VERSION ""

NS_ :

BS_:

BU_: CVC_I MHU TBOX FCAM_I MRR SRR_RL SRR_RR SRR_FL SRR_FR DUMMY_ECU ADCU_I AMP HUD

BO_ 854 CVC_ADAS_SOTA_REQUEST: 20 CVC_I
 SG_ CRC_CVC_ADAS_SOTA_REQUEST : 7|8@0+ (1,0) [0|255] ""  MHU,FCAM_I,SRR_RL,SRR_RR,SRR_FL,SRR_FR,ADCU_I
 SG_ ALIVE_CVC_ADAS_SOTA_REQUEST : 11|4@0+ (1,0) [0|15] ""  MHU,FCAM_I,SRR_RL,SRR_RR,SRR_FL,SRR_FR,ADCU_I
 SG_ CVC_ADAS_HWA_SOTA : 114|3@0+ (1,0) [0|7] ""  MHU,FCAM_I,SRR_RL,SRR_RR,SRR_FL,SRR_FR,ADCU_I
 SG_ CVC_ADAS_AESA_SOTA : 20|3@0+ (1,0) [0|7] ""  MHU,FCAM_I,SRR_RL,SRR_RR,SRR_FL,SRR_FR,ADCU_I
 SG_ CVC_ADAS_ALCA_SOTA : 23|3@0+ (1,0) [0|7] ""  MHU,FCAM_I,SRR_RL,SRR_RR,SRR_FL,SRR_FR,ADCU_I
 SG_ CVC_ADAS_BasicCruise_SOTA : 17|3@0+ (1,0) [0|7] ""  MHU,FCAM_I,SRR_RL,SRR_RR,SRR_FL,SRR_FR,ADCU_I
 SG_ CVC_ADAS_ACC_SOTA : 30|3@0+ (1,0) [0|7] ""  MHU,FCAM_I,SRR_RL,SRR_RR,SRR_FL,SRR_FR,ADCU_I
 SG_ CVC_ADAS_TSR_SOTA : 27|3@0+ (1,0) [0|7] ""  MHU,FCAM_I,SRR_RL,SRR_RR,SRR_FL,SRR_FR,ADCU_I
 SG_ CVC_ADAS_ISA_SOTA : 24|3@0+ (1,0) [0|7] ""  MHU,FCAM_I,SRR_RL,SRR_RR,SRR_FL,SRR_FR,ADCU_I
 SG_ CVC_ADAS_NOP_SOTA : 37|3@0+ (1,0) [0|7] ""  MHU,FCAM_I,SRR_RL,SRR_RR,SRR_FL,SRR_FR,ADCU_I
 SG_ CVC_ADAS_AAESA_SOTA : 34|3@0+ (1,0) [0|7] ""  MHU,FCAM_I,SRR_RL,SRR_RR,SRR_FL,SRR_FR,ADCU_I
 SG_ CVC_ADAS_ALCM_SOTA : 47|3@0+ (1,0) [0|7] ""  MHU,FCAM_I,SRR_RL,SRR_RR,SRR_FL,SRR_FR,ADCU_I
 SG_ CVC_ADAS_AACC_SOTA : 41|3@0+ (1,0) [0|7] ""  MHU,FCAM_I,SRR_RL,SRR_RR,SRR_FL,SRR_FR,ADCU_I
 SG_ CVC_ADAS_TLD_SOTA : 54|3@0+ (1,0) [0|7] ""  MHU,FCAM_I,SRR_RL,SRR_RR,SRR_FL,SRR_FR,ADCU_I
 SG_ CVC_ADAS_DNS_SOTA : 51|3@0+ (1,0) [0|7] ""  MHU,FCAM_I,SRR_RL,SRR_RR,SRR_FL,SRR_FR,ADCU_I
 SG_ CVC_ADAS_LDW_SOTA : 48|3@0+ (1,0) [0|7] ""  MHU,FCAM_I,SRR_RL,SRR_RR,SRR_FL,SRR_FR,ADCU_I
 SG_ CVC_ADAS_LKA_SOTA : 61|3@0+ (1,0) [0|7] ""  MHU,FCAM_I,SRR_RL,SRR_RR,SRR_FL,SRR_FR,ADCU_I
 SG_ CVC_ADAS_ELK_SOTA : 58|3@0+ (1,0) [0|7] ""  MHU,FCAM_I,SRR_RL,SRR_RR,SRR_FL,SRR_FR,ADCU_I
 SG_ CVC_ADAS_FAEB_SOTA : 71|3@0+ (1,0) [0|7] ""  MHU,FCAM_I,SRR_RL,SRR_RR,SRR_FL,SRR_FR,ADCU_I
 SG_ CVC_ADAS_ESA_SOTA : 68|3@0+ (1,0) [0|7] ""  MHU,FCAM_I,SRR_RL,SRR_RR,SRR_FL,SRR_FR,ADCU_I
 SG_ CVC_ADAS_RAEB_SOTA : 65|3@0+ (1,0) [0|7] ""  MHU,FCAM_I,SRR_RL,SRR_RR,SRR_FL,SRR_FR,ADCU_I
 SG_ CVC_ADAS_FCW_SOTA : 78|3@0+ (1,0) [0|7] ""  MHU,FCAM_I,SRR_RL,SRR_RR,SRR_FL,SRR_FR,ADCU_I
 SG_ CVC_ADAS_RCTA_SOTA : 75|3@0+ (1,0) [0|7] ""  MHU,FCAM_I,SRR_RL,SRR_RR,SRR_FL,SRR_FR,ADCU_I
 SG_ CVC_ADAS_BSD_SOTA : 72|3@0+ (1,0) [0|7] ""  MHU,FCAM_I,SRR_RL,SRR_RR,SRR_FL,SRR_FR,ADCU_I
 SG_ CVC_ADAS_DOW_SOTA : 85|3@0+ (1,0) [0|7] ""  MHU,FCAM_I,SRR_RL,SRR_RR,SRR_FL,SRR_FR,ADCU_I
 SG_ CVC_ADAS_IA_SOTA : 82|3@0+ (1,0) [0|7] ""  MHU,FCAM_I,SRR_RL,SRR_RR,SRR_FL,SRR_FR,ADCU_I
 SG_ CVC_ADAS_SVM_SOTA : 95|3@0+ (1,0) [0|7] ""  MHU,FCAM_I,SRR_RL,SRR_RR,SRR_FL,SRR_FR,ADCU_I
 SG_ CVC_ADAS_RVC_SOTA : 89|3@0+ (1,0) [0|7] ""  MHU,FCAM_I,SRR_RL,SRR_RR,SRR_FL,SRR_FR,ADCU_I
 SG_ CVC_ADAS_FPA_SOTA : 92|3@0+ (1,0) [0|7] ""  MHU,FCAM_I,SRR_RL,SRR_RR,SRR_FL,SRR_FR,ADCU_I
 SG_ CVC_ADAS_RPA_SOTA : 102|3@0+ (1,0) [0|7] ""  MHU,FCAM_I,SRR_RL,SRR_RR,SRR_FL,SRR_FR,ADCU_I
 SG_ CVC_ADAS_SpaFAPA_SOTA : 99|3@0+ (1,0) [0|7] ""  MHU,FCAM_I,SRR_RL,SRR_RR,SRR_FL,SRR_FR,ADCU_I
 SG_ CVC_ADAS_RP_SOTA : 44|3@0+ (1,0) [0|7] ""  MHU,FCAM_I,SRR_RL,SRR_RR,SRR_FL,SRR_FR,ADCU_I
 SG_ CVC_ADAS_VParkingSelect_SOTA : 110|3@0+ (1,0) [0|7] ""  MHU,FCAM_I,SRR_RL,SRR_RR,SRR_FL,SRR_FR,ADCU_I
 SG_ CVC_ADAS_VParkingComfort_SOTA : 107|3@0+ (1,0) [0|7] ""  MHU,FCAM_I,SRR_RL,SRR_RR,SRR_FL,SRR_FR,ADCU_I
 SG_ CVC_ADAS_VParkingSummon_SOTA : 104|3@0+ (1,0) [0|7] ""  MHU,FCAM_I,SRR_RL,SRR_RR,SRR_FL,SRR_FR,ADCU_I
 SG_ CVC_ADAS_VParkingAutoRev_SOTA : 117|3@0+ (1,0) [0|7] ""  MHU,FCAM_I,SRR_RL,SRR_RR,SRR_FL,SRR_FR,ADCU_I
 SG_ CVC_ADAS_AHB_SOTA : 127|3@0+ (1,0) [0|7] ""  MHU,FCAM_I,SRR_RL,SRR_RR,SRR_FL,SRR_FR,ADCU_I
 SG_ CVC_ADAS_ADB_SOTA : 124|3@0+ (1,0) [0|7] ""  MHU,FCAM_I,SRR_RL,SRR_RR,SRR_FL,SRR_FR,ADCU_I
 SG_ CVC_ADAS_DMS_SOTA : 121|3@0+ (1,0) [0|7] ""  MHU,FCAM_I,SRR_RL,SRR_RR,SRR_FL,SRR_FR,ADCU_I
 SG_ CVC_ADAS_DMSFaceID_SOTA : 134|3@0+ (1,0) [0|7] ""  MHU,FCAM_I,SRR_RL,SRR_RR,SRR_FL,SRR_FR,ADCU_I
 SG_ CVC_ADAS_DCM_SOTA : 131|3@0+ (1,0) [0|7] ""  MHU,FCAM_I,SRR_RL,SRR_RR,SRR_FL,SRR_FR,ADCU_I
 SG_ CVC_ADAS_AdasEDR_SOTA : 128|3@0+ (1,0) [0|7] ""  MHU,FCAM_I,SRR_RL,SRR_RR,SRR_FL,SRR_FR,ADCU_I
 SG_ CVC_ADAS_ACPE_SOTA : 141|3@0+ (1,0) [0|7] ""  MHU,FCAM_I,SRR_RL,SRR_RR,SRR_FL,SRR_FR,ADCU_I
 SG_ CVC_ADAS_SentryMode_SOTA : 138|3@0+ (1,0) [0|7] ""  MHU,FCAM_I,SRR_RL,SRR_RR,SRR_FL,SRR_FR,ADCU_I

BO_ 862 CVC_Vehicle_info: 16 CVC_I
 SG_ CRC_CVC_Vehicle_info : 7|8@0+ (1,0) [0|255] ""  MHU,ADCU_I
 SG_ ALIVE_CVC_Vehicle_info : 11|4@0+ (1,0) [0|15] ""  MHU,ADCU_I
 SG_ CVC_VehLock_STS : 13|2@0+ (1,0) [0|3] ""  ADCU_I,HUD
 SG_ CVC_VehSpd_ScreenDisplay : 23|8@0+ (1,0) [0|254] ""  ADCU_I,HUD
 SG_ CVC_VehChgAllow : 25|2@0+ (1,0) [0|3] ""  ADCU_I,HUD
 SG_ CVC_VehDischgAllow : 15|2@0+ (1,0) [0|3] ""  ADCU_I,HUD
 SG_ Re_InitCharging_Req : 27|2@0+ (1,0) [0|3] ""  ADCU_I,HUD
 SG_ CVC_StopChg_Req : 28|1@0+ (1,0) [0|1] ""  ADCU_I,HUD
 SG_ CVC_GunUnlock_Req : 30|2@0+ (1,0) [0|3] ""  ADCU_I,HUD
 SG_ CVC_Ack_LimitSetting_SOC : 39|7@0+ (1,0) [0|100] "%"  ADCU_I,HUD
 SG_ CVC_ACInputChgCurLim : 47|6@0+ (1,0) [0|48] "A"  ADCU_I,HUD
 SG_ CVC_HV_DispSOC : 41|10@0+ (0.1,0) [0|100] "%"  MHU,ADCU_I
 SG_ CVC_HV_Cur_LoadComp : 63|10@0+ (0.1,0) [0|100] "A"  ADCU_I,HUD
 SG_ CVC_AntiTheft_Status : 69|3@0+ (1,0) [0|7] ""  MHU,FCAM_I,SRR_RR,ADCU_I

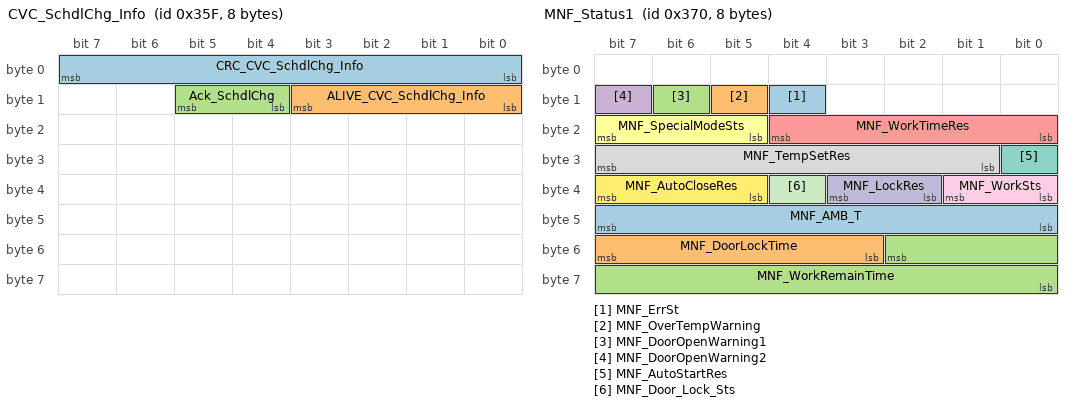
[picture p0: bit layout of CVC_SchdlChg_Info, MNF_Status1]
BO_ 863 CVC_SchdlChg_Info: 8 CVC_I
 SG_ CRC_CVC_SchdlChg_Info : 7|8@0+ (1,0) [0|255] ""  MHU
 SG_ ALIVE_CVC_SchdlChg_Info : 11|4@0+ (1,0) [0|15] ""  MHU
 SG_ Ack_SchdlChg : 13|2@0+ (1,0) [0|3] ""  MHU

BO_ 866 WCBS_RecuBrkTrqReq: 24 CVC_I
 SG_ CRC_WCBS_RecuBrkTrqReq : 7|8@0+ (1,0) [0|255] ""  SRR_RR,SRR_FR
 SG_ ALIVE_WCBS_RecuBrkTrqReq : 11|4@0+ (1,0) [0|15] ""  SRR_RR,SRR_FR
 SG_ WCBS_RBC_STS : 12|1@0+ (1,0) [0|1] ""  SRR_RR,SRR_FR
 SG_ WCBS_RegenMonFail : 13|1@0+ (1,0) [0|1] ""  SRR_RR,SRR_FR
 SG_ WCBS_TorqReqMode : 15|2@0+ (1,0) [0|3] ""  SRR_RR,SRR_FR
 SG_ WCBS_F_RegenTarTrq : 23|16@0+ (1,-4000) [-4000|0] "Nm"  SRR_RR,SRR_FR
 SG_ WCBS_R_RegenTarTrq : 39|16@0+ (1,-4000) [-4000|0] "Nm"  SRR_RR,SRR_FR
 SG_ WCBS_F_RegenTarTrqValid : 48|1@0+ (1,0) [0|1] ""  SRR_RR,SRR_FR
 SG_ WCBS_R_RegenTarTrqValid : 49|1@0+ (1,0) [0|1] ""  SRR_RR,SRR_FR
 SG_ WCBS_F_FrictionTarTrq : 63|16@0+ (1,-4000) [-4000|0] "Nm"  SRR_RR,SRR_FR
 SG_ WCBS_R_FrictionTarTrq : 79|16@0+ (1,-4000) [-4000|0] "Nm"  SRR_RR,SRR_FR
 SG_ Secure_ResetCnt_0x362 : 135|16@0+ (1,0) [0|65535] ""  SRR_RR,SRR_FR
 SG_ Secure_MsgCnt_0x362 : 151|16@0+ (1,0) [0|65535] ""  SRR_RR,SRR_FR
 SG_ Secure_MAC_0x362 : 167|32@0+ (1,0) [0|4294967295] ""  SRR_RR,SRR_FR

BO_ 872 FMCU_Fault: 8 CVC_I
 SG_ FMCU_PhaseOverCurrentSWFault : 0|1@0+ (1,0) [0|1] ""  MHU
 SG_ FMCU_MCUOverTempFault : 1|1@0+ (1,0) [0|1] ""  MHU
 SG_ FMCU_MCUOverTempAlarm : 2|1@0+ (1,0) [0|1] ""  MHU
 SG_ FMCU_MotOverTemp2Fault : 5|1@0+ (1,0) [0|1] ""  MHU
 SG_ FMCU_MotTempSenFault : 6|1@0+ (1,0) [0|1] ""  MHU
 SG_ FMCU_MotOverTemp1Fault : 7|1@0+ (1,0) [0|1] ""  MHU
 SG_ FMCU_MotOverTempAlarm : 8|1@0+ (1,0) [0|1] ""  MHU
 SG_ FMCU_MCUHVUnderVoltageFault : 9|1@0+ (1,0) [0|1] ""  MHU
 SG_ FMCU_MCUHVUnderVoltageAlarm : 10|1@0+ (1,0) [0|1] ""  MHU
 SG_ FMCU_MCUHVOverVoltageFault : 11|1@0+ (1,0) [0|1] ""  MHU
 SG_ FMCU_MCUHVOverVoltageAlarm : 12|1@0+ (1,0) [0|1] ""  MHU
 SG_ FMCU_MCUCurrentSenWFault : 13|1@0+ (1,0) [0|1] ""  MHU
 SG_ FMCU_MCUCurrentSenVFault : 14|1@0+ (1,0) [0|1] ""  MHU
 SG_ FMCU_MCUCurrentSenUFault : 15|1@0+ (1,0) [0|1] ""  MHU
 SG_ FMCU_PhaseOverCurrentHWFault : 16|1@0+ (1,0) [0|1] ""  MHU
 SG_ FMCU_MotOverFault : 17|1@0+ (1,0) [0|1] ""  MHU
 SG_ FMCU_MotOverAlarm : 18|1@0+ (1,0) [0|1] ""  MHU
 SG_ FMCU_12VUnderVoltageAlarm : 20|1@0+ (1,0) [0|1] ""  MHU
 SG_ FMCU_12VOverVoltageAlarm : 21|1@0+ (1,0) [0|1] ""  MHU
 SG_ FMCU_MCUHVSensorFault : 22|1@0+ (1,0) [0|1] ""  MHU
 SG_ FMCU_MCUDisChgFault : 24|1@0+ (1,0) [0|1] ""  MHU
 SG_ FMCU_MotBlockedFault : 30|1@0+ (1,0) [0|1] ""  MHU
 SG_ FMCU_MotRotSenFault : 31|1@0+ (1,0) [0|1] ""  MHU
 SG_ FMCU_BMSLostFault : 34|1@0+ (1,0) [0|1] ""  MHU
 SG_ FMCU_CVCLostFault : 35|1@0+ (1,0) [0|1] ""  MHU
 SG_ FMCU_CANBusoffFault : 36|1@0+ (1,0) [0|1] ""  MHU
 SG_ FMCU_IGBTFault : 37|1@0+ (1,0) [0|1] ""  MHU
 SG_ FMCU_MCUCurrentSenWZeroFault : 38|1@0+ (1,0) [0|1] ""  MHU
 SG_ FMCU_MCUCurrentSenVZeroFault : 43|1@0+ (1,0) [0|1] ""  MHU
 SG_ FMCU_MCUCurrentSenUZeroFault : 44|1@0+ (1,0) [0|1] ""  MHU
 SG_ FMCU_MCUTempSenWFault : 45|1@0+ (1,0) [0|1] ""  MHU
 SG_ FMCU_MCUTempSenVFault : 46|1@0+ (1,0) [0|1] ""  MHU
 SG_ FMCU_MCUTempSenUFault : 47|1@0+ (1,0) [0|1] ""  MHU
 SG_ FMCU_InitMode : 50|1@0+ (1,0) [0|1] ""  MHU
 SG_ FMCU_MCUFaultCode : 63|8@0+ (1,0) [0|255] ""  MHU

BO_ 874 RMCU_Fault: 8 CVC_I
 SG_ RMCU_PhaseOverCurrentSWFault : 0|1@0+ (1,0) [0|1] ""  MHU
 SG_ RMCU_MCUOverTempFault : 1|1@0+ (1,0) [0|1] ""  MHU
 SG_ RMCU_MCUOverTempAlarm : 2|1@0+ (1,0) [0|1] ""  MHU
 SG_ RMCU_MotOverTemp2Fault : 5|1@0+ (1,0) [0|1] ""  MHU
 SG_ RMCU_MotTempSenFault : 6|1@0+ (1,0) [0|1] ""  MHU
 SG_ RMCU_MotOverTemp1Fault : 7|1@0+ (1,0) [0|1] ""  MHU
 SG_ RMCU_MotOverTempAlarm : 8|1@0+ (1,0) [0|1] ""  MHU
 SG_ RMCU_MCUHVUnderVoltageFault : 9|1@0+ (1,0) [0|1] ""  MHU
 SG_ RMCU_MCUHVUnderVoltageAlarm : 10|1@0+ (1,0) [0|1] ""  MHU
 SG_ RMCU_MCUHVOverVoltageFault : 11|1@0+ (1,0) [0|1] ""  MHU
 SG_ RMCU_MCUHVOverVoltageAlarm : 12|1@0+ (1,0) [0|1] ""  MHU
 SG_ RMCU_MCUCurrentSenWFault : 13|1@0+ (1,0) [0|1] ""  MHU
 SG_ RMCU_MCUCurrentSenVFault : 14|1@0+ (1,0) [0|1] ""  MHU
 SG_ RMCU_MCUCurrentSenUFault : 15|1@0+ (1,0) [0|1] ""  MHU
 SG_ RMCU_PhaseOverCurrentHWFault : 16|1@0+ (1,0) [0|1] ""  MHU
 SG_ RMCU_MotOverFault : 17|1@0+ (1,0) [0|1] ""  MHU
 SG_ RMCU_MotOverAlarm : 18|1@0+ (1,0) [0|1] ""  MHU
 SG_ RMCU_12VUnderVoltageAlarm : 20|1@0+ (1,0) [0|1] ""  MHU
 SG_ RMCU_12VOverVoltageAlarm : 21|1@0+ (1,0) [0|1] ""  MHU
 SG_ RMCU_MCUHVSensorFault : 22|1@0+ (1,0) [0|1] ""  MHU
 SG_ RMCU_MCUDisChgFault : 24|1@0+ (1,0) [0|1] ""  MHU
 SG_ RMCU_MotBlockedFault : 30|1@0+ (1,0) [0|1] ""  MHU
 SG_ RMCU_MotRotSenFault : 31|1@0+ (1,0) [0|1] ""  MHU
 SG_ RMCU_BMSLostFault : 34|1@0+ (1,0) [0|1] ""  MHU
 SG_ RMCU_CVCLostFault : 35|1@0+ (1,0) [0|1] ""  MHU
 SG_ RMCU_CANBusoffFault : 36|1@0+ (1,0) [0|1] ""  MHU
 SG_ RMCU_IGBTFault : 37|1@0+ (1,0) [0|1] ""  MHU
 SG_ RMCU_MCUCurrentSenWZeroFault : 38|1@0+ (1,0) [0|1] ""  MHU
 SG_ RMCU_MCUCurrentSenVZeroFault : 43|1@0+ (1,0) [0|1] ""  MHU
 SG_ RMCU_MCUCurrentSenUZeroFault : 44|1@0+ (1,0) [0|1] ""  MHU
 SG_ RMCU_MCUTempSenWFault : 45|1@0+ (1,0) [0|1] ""  MHU
 SG_ RMCU_MCUTempSenVFault : 46|1@0+ (1,0) [0|1] ""  MHU
 SG_ RMCU_MCUTempSenUFault : 47|1@0+ (1,0) [0|1] ""  MHU
 SG_ RMCU_InitMode : 50|1@0+ (1,0) [0|1] ""  MHU
 SG_ RMCU_MCUFaultCode : 63|8@0+ (1,0) [0|255] ""  MHU

BO_ 880 MNF_Status1: 8 CVC_I
 SG_ MNF_ErrSt : 12|1@0+ (1,0) [0|1] ""  MHU
 SG_ MNF_OverTempWarning : 13|1@0+ (1,0) [0|1] ""  MHU
 SG_ MNF_DoorOpenWarning1 : 14|1@0+ (1,0) [0|1] ""  MHU
 SG_ MNF_DoorOpenWarning2 : 15|1@0+ (1,0) [0|1] ""  MHU
 SG_ MNF_WorkTimeRes : 20|5@0+ (1,0) [0|24] "h"  MHU
 SG_ MNF_SpecialModeSts : 23|3@0+ (1,0) [0|7] ""  MHU
 SG_ MNF_AutoStartRes : 24|1@0+ (1,0) [0|1] ""  MHU
 SG_ MNF_TempSetRes : 31|7@0+ (1,-10) [-10|116] ""  MHU
 SG_ MNF_WorkSts : 33|2@0+ (1,0) [0|3] ""  MHU
 SG_ MNF_LockRes : 35|2@0+ (1,0) [0|3] ""  MHU
 SG_ MNF_Door_Lock_Sts : 36|1@0+ (1,0) [0|1] ""  MHU
 SG_ MNF_AutoCloseRes : 39|3@0+ (1,0) [0|6] ""  MHU
 SG_ MNF_AMB_T : 47|8@0+ (1,-50) [-50|204] "Degree C"  MHU
 SG_ MNF_DoorLockTime : 55|5@0+ (1,0) [0|30] "s"  MHU
 SG_ MNF_WorkRemainTime : 50|11@0+ (1,0) [0|2046] "min"  MHU

BO_ 881 MNF_Status2: 8 CVC_I
 SG_ MNF_INT_T : 23|8@0+ (1,-50) [-50|204] "Degree C"  MHU
 SG_ MNF_ErrInfo : 27|4@0+ (1,0) [0|12] ""  MHU
 SG_ MNF_HVReq : 28|1@0+ (1,0) [0|1] ""  MHU

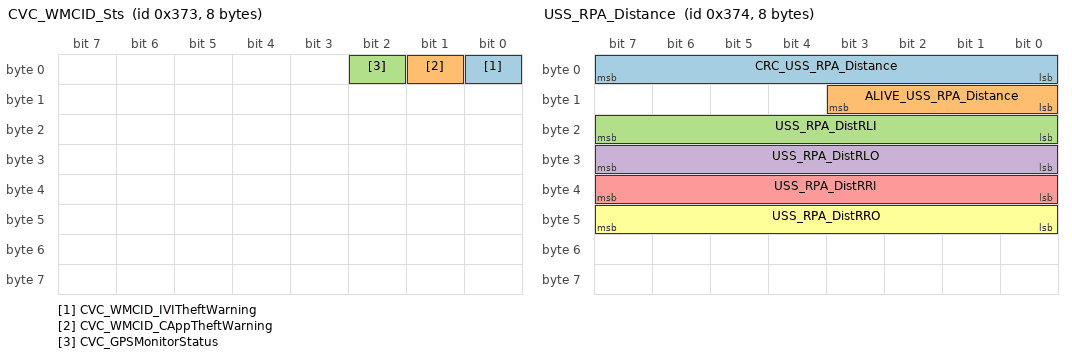
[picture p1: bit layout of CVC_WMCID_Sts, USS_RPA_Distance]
BO_ 883 CVC_WMCID_Sts: 8 CVC_I
 SG_ CVC_WMCID_IVITheftWarning : 0|1@0+ (1,0) [0|1] ""  MHU
 SG_ CVC_WMCID_CAppTheftWarning : 1|1@0+ (1,0) [0|1] ""  MHU
 SG_ CVC_GPSMonitorStatus : 2|1@0+ (1,0) [0|1] ""  MHU

BO_ 884 USS_RPA_Distance: 8 CVC_I
 SG_ CRC_USS_RPA_Distance : 7|8@0+ (1,0) [0|255] ""  MHU
 SG_ ALIVE_USS_RPA_Distance : 11|4@0+ (1,0) [0|15] ""  MHU
 SG_ USS_RPA_DistRLI : 23|8@0+ (1,0) [0|255] "cm"  MHU
 SG_ USS_RPA_DistRLO : 31|8@0+ (1,0) [0|255] "cm"  MHU
 SG_ USS_RPA_DistRRI : 39|8@0+ (1,0) [0|255] "cm"  MHU
 SG_ USS_RPA_DistRRO : 47|8@0+ (1,0) [0|255] "cm"  MHU

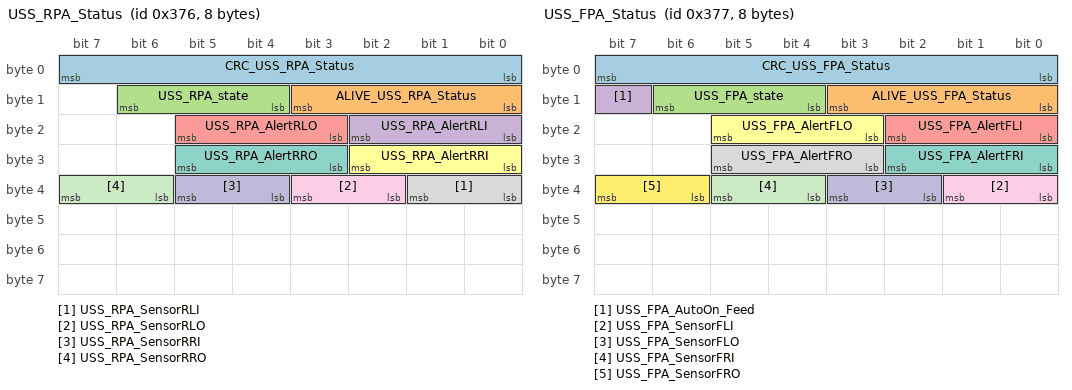
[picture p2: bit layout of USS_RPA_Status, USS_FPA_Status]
BO_ 886 USS_RPA_Status: 8 CVC_I
 SG_ CRC_USS_RPA_Status : 7|8@0+ (1,0) [0|255] ""  MHU
 SG_ ALIVE_USS_RPA_Status : 11|4@0+ (1,0) [0|15] ""  MHU
 SG_ USS_RPA_state : 14|3@0+ (1,0) [0|7] ""  MHU
 SG_ USS_RPA_AlertRLI : 18|3@0+ (1,0) [0|7] ""  MHU
 SG_ USS_RPA_AlertRLO : 21|3@0+ (1,0) [0|7] ""  MHU
 SG_ USS_RPA_AlertRRI : 26|3@0+ (1,0) [0|7] ""  MHU
 SG_ USS_RPA_AlertRRO : 29|3@0+ (1,0) [0|7] ""  MHU
 SG_ USS_RPA_SensorRLI : 33|2@0+ (1,0) [0|3] ""  MHU
 SG_ USS_RPA_SensorRLO : 35|2@0+ (1,0) [0|3] ""  MHU
 SG_ USS_RPA_SensorRRI : 37|2@0+ (1,0) [0|3] ""  MHU
 SG_ USS_RPA_SensorRRO : 39|2@0+ (1,0) [0|3] ""  MHU

BO_ 887 USS_FPA_Status: 8 CVC_I
 SG_ CRC_USS_FPA_Status : 7|8@0+ (1,0) [0|255] ""  MHU
 SG_ ALIVE_USS_FPA_Status : 11|4@0+ (1,0) [0|15] ""  MHU
 SG_ USS_FPA_state : 14|3@0+ (1,0) [0|7] ""  MHU
 SG_ USS_FPA_AutoOn_Feed : 15|1@0+ (1,0) [0|1] ""  MHU
 SG_ USS_FPA_AlertFLI : 18|3@0+ (1,0) [0|7] ""  MHU
 SG_ USS_FPA_AlertFLO : 21|3@0+ (1,0) [0|7] ""  MHU
 SG_ USS_FPA_AlertFRI : 26|3@0+ (1,0) [0|7] ""  MHU
 SG_ USS_FPA_AlertFRO : 29|3@0+ (1,0) [0|7] ""  MHU
 SG_ USS_FPA_SensorFLI : 33|2@0+ (1,0) [0|3] ""  MHU
 SG_ USS_FPA_SensorFLO : 35|2@0+ (1,0) [0|3] ""  MHU
 SG_ USS_FPA_SensorFRI : 37|2@0+ (1,0) [0|3] ""  MHU
 SG_ USS_FPA_SensorFRO : 39|2@0+ (1,0) [0|3] ""  MHU

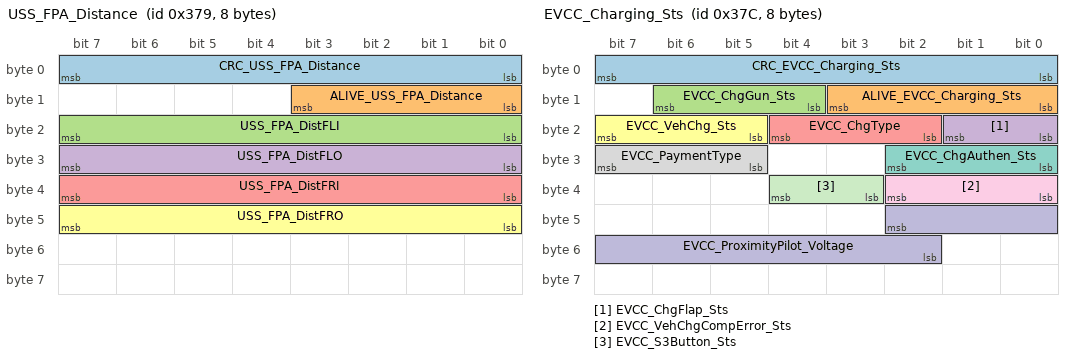
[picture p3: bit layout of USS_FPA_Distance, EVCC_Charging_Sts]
BO_ 889 USS_FPA_Distance: 8 CVC_I
 SG_ CRC_USS_FPA_Distance : 7|8@0+ (1,0) [0|255] ""  MHU
 SG_ ALIVE_USS_FPA_Distance : 11|4@0+ (1,0) [0|15] ""  MHU
 SG_ USS_FPA_DistFLI : 23|8@0+ (1,0) [0|255] "cm"  MHU
 SG_ USS_FPA_DistFLO : 31|8@0+ (1,0) [0|255] "cm"  MHU
 SG_ USS_FPA_DistFRI : 39|8@0+ (1,0) [0|255] "cm"  MHU
 SG_ USS_FPA_DistFRO : 47|8@0+ (1,0) [0|255] "cm"  MHU

BO_ 892 EVCC_Charging_Sts: 8 CVC_I
 SG_ CRC_EVCC_Charging_Sts : 7|8@0+ (1,0) [0|255] ""  MHU,ADCU_I
 SG_ ALIVE_EVCC_Charging_Sts : 11|4@0+ (1,0) [0|15] ""  MHU,ADCU_I
 SG_ EVCC_ChgGun_Sts : 14|3@0+ (1,0) [0|7] ""  MHU,ADCU_I
 SG_ EVCC_ChgFlap_Sts : 17|2@0+ (1,0) [0|3] ""  MHU,ADCU_I
 SG_ EVCC_ChgType : 20|3@0+ (1,0) [0|7] ""  MHU,ADCU_I
 SG_ EVCC_VehChg_Sts : 23|3@0+ (1,0) [0|7] ""  MHU,ADCU_I
 SG_ EVCC_ChgAuthen_Sts : 26|3@0+ (1,0) [0|7] ""  MHU,ADCU_I
 SG_ EVCC_PaymentType : 31|3@0+ (1,0) [0|7] ""  MHU,ADCU_I
 SG_ EVCC_VehChgCompError_Sts : 34|3@0+ (1,0) [0|7] ""  MHU,ADCU_I
 SG_ EVCC_ProximityPilot_Voltage : 42|9@0+ (0.01,0) [0|5] "V"  MHU,ADCU_I
 SG_ EVCC_S3Button_Sts : 36|2@0+ (1,0) [0|3] ""  MHU,ADCU_I

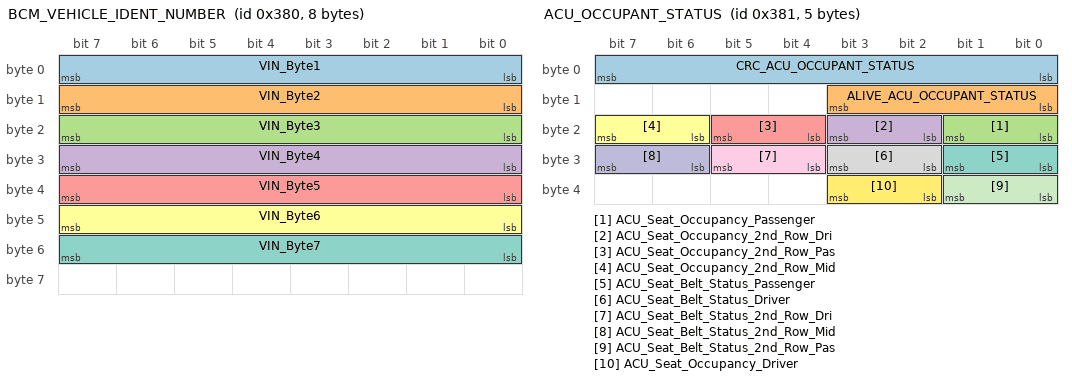
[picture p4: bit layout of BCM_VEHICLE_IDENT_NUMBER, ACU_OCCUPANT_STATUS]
BO_ 896 BCM_VEHICLE_IDENT_NUMBER: 8 CVC_I
 SG_ VIN_Byte1 : 7|8@0+ (1,0) [0|255] ""  MHU,FCAM_I,SRR_RR,ADCU_I
 SG_ VIN_Byte2 : 15|8@0+ (1,0) [0|255] ""  MHU,FCAM_I,SRR_RR,ADCU_I
 SG_ VIN_Byte3 : 23|8@0+ (1,0) [0|255] ""  MHU,FCAM_I,SRR_RR,ADCU_I
 SG_ VIN_Byte4 : 31|8@0+ (1,0) [0|255] ""  MHU,FCAM_I,SRR_RR,ADCU_I
 SG_ VIN_Byte5 : 39|8@0+ (1,0) [0|255] ""  MHU,FCAM_I,SRR_RR,ADCU_I
 SG_ VIN_Byte6 : 47|8@0+ (1,0) [0|255] ""  MHU,FCAM_I,SRR_RR,ADCU_I
 SG_ VIN_Byte7 : 55|8@0+ (1,0) [0|255] ""  MHU,FCAM_I,SRR_RR,ADCU_I

BO_ 897 ACU_OCCUPANT_STATUS: 5 CVC_I
 SG_ CRC_ACU_OCCUPANT_STATUS : 7|8@0+ (1,0) [0|255] ""  MHU,TBOX,FCAM_I,MRR,SRR_RL,SRR_RR,SRR_FL,SRR_FR,ADCU_I,AMP
 SG_ ALIVE_ACU_OCCUPANT_STATUS : 11|4@0+ (1,0) [0|15] ""  MHU,TBOX,FCAM_I,MRR,SRR_RL,SRR_RR,SRR_FL,SRR_FR,ADCU_I,AMP
 SG_ ACU_Seat_Occupancy_Passenger : 17|2@0+ (1,0) [0|3] ""  MHU,TBOX,FCAM_I,MRR,SRR_RL,SRR_RR,SRR_FL,SRR_FR,ADCU_I,AMP
 SG_ ACU_Seat_Occupancy_2nd_Row_Dri : 19|2@0+ (1,0) [0|3] ""  MHU,TBOX,FCAM_I,MRR,SRR_RL,SRR_RR,SRR_FL,SRR_FR,ADCU_I,AMP
 SG_ ACU_Seat_Occupancy_2nd_Row_Pas : 21|2@0+ (1,0) [0|3] ""  MHU,TBOX,FCAM_I,MRR,SRR_RL,SRR_RR,SRR_FL,SRR_FR,ADCU_I,AMP
 SG_ ACU_Seat_Occupancy_2nd_Row_Mid : 23|2@0+ (1,0) [0|3] ""  MHU,TBOX,FCAM_I,MRR,SRR_RL,SRR_RR,SRR_FL,SRR_FR,ADCU_I,AMP
 SG_ ACU_Seat_Belt_Status_Passenger : 25|2@0+ (1,0) [0|3] ""  MHU,TBOX,FCAM_I,MRR,SRR_RL,SRR_RR,SRR_FL,SRR_FR,ADCU_I,AMP
 SG_ ACU_Seat_Belt_Status_Driver : 27|2@0+ (1,0) [0|3] ""  MHU,TBOX,FCAM_I,MRR,SRR_RL,SRR_RR,SRR_FL,SRR_FR,ADCU_I,AMP
 SG_ ACU_Seat_Belt_Status_2nd_Row_Dri : 29|2@0+ (1,0) [0|3] ""  MHU,TBOX,FCAM_I,MRR,SRR_RL,SRR_RR,SRR_FL,SRR_FR,ADCU_I,AMP
 SG_ ACU_Seat_Belt_Status_2nd_Row_Mid : 31|2@0+ (1,0) [0|3] ""  MHU,TBOX,FCAM_I,MRR,SRR_RL,SRR_RR,SRR_FL,SRR_FR,ADCU_I,AMP
 SG_ ACU_Seat_Belt_Status_2nd_Row_Pas : 33|2@0+ (1,0) [0|3] ""  MHU,TBOX,FCAM_I,MRR,SRR_RL,SRR_RR,SRR_FL,SRR_FR,ADCU_I,AMP
 SG_ ACU_Seat_Occupancy_Driver : 35|2@0+ (1,0) [0|3] ""  MHU,TBOX,FCAM_I,MRR,SRR_RL,SRR_RR,SRR_FL,SRR_FR,ADCU_I,AMP

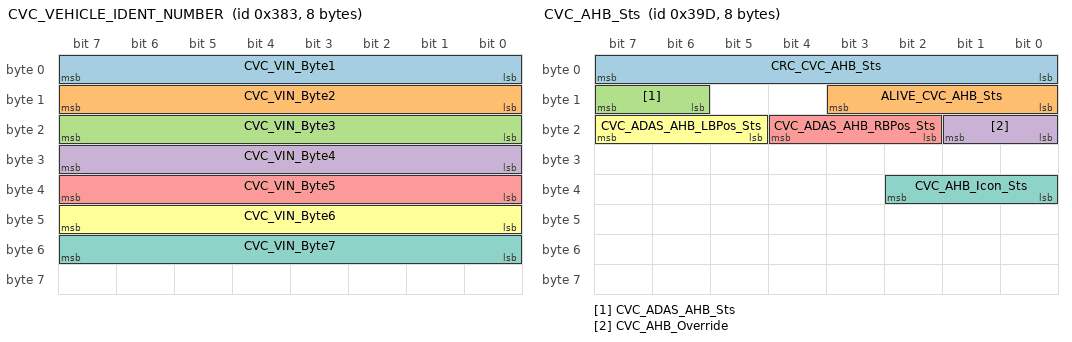
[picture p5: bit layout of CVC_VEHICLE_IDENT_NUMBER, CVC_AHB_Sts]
BO_ 899 CVC_VEHICLE_IDENT_NUMBER: 8 CVC_I
 SG_ CVC_VIN_Byte1 : 7|8@0+ (1,0) [0|255] ""  MHU
 SG_ CVC_VIN_Byte2 : 15|8@0+ (1,0) [0|255] ""  MHU
 SG_ CVC_VIN_Byte3 : 23|8@0+ (1,0) [0|255] ""  MHU
 SG_ CVC_VIN_Byte4 : 31|8@0+ (1,0) [0|255] ""  MHU
 SG_ CVC_VIN_Byte5 : 39|8@0+ (1,0) [0|255] ""  MHU
 SG_ CVC_VIN_Byte6 : 47|8@0+ (1,0) [0|255] ""  MHU
 SG_ CVC_VIN_Byte7 : 55|8@0+ (1,0) [0|255] ""  MHU

BO_ 925 CVC_AHB_Sts: 8 CVC_I
 SG_ CRC_CVC_AHB_Sts : 7|8@0+ (1,0) [0|255] ""  MHU,FCAM_I,ADCU_I
 SG_ ALIVE_CVC_AHB_Sts : 11|4@0+ (1,0) [0|15] ""  MHU,FCAM_I,ADCU_I
 SG_ CVC_ADAS_AHB_Sts : 15|2@0+ (1,0) [0|3] ""  MHU,ADCU_I
 SG_ CVC_AHB_Override : 17|2@0+ (1,0) [0|3] ""  MHU,ADCU_I
 SG_ CVC_ADAS_AHB_RBPos_Sts : 20|3@0+ (1,0) [0|7] ""  FCAM_I,ADCU_I
 SG_ CVC_ADAS_AHB_LBPos_Sts : 23|3@0+ (1,0) [0|7] ""  FCAM_I,ADCU_I
 SG_ CVC_AHB_Icon_Sts : 34|3@0+ (1,0) [0|7] ""  MHU,ADCU_I

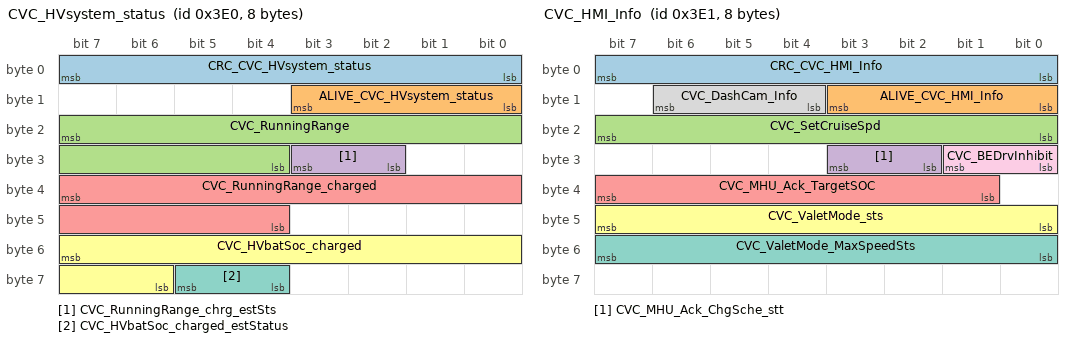
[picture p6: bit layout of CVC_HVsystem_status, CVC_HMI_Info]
BO_ 992 CVC_HVsystem_status: 8 CVC_I
 SG_ CRC_CVC_HVsystem_status : 7|8@0+ (1,0) [0|255] ""  MHU
 SG_ ALIVE_CVC_HVsystem_status : 11|4@0+ (1,0) [0|15] ""  MHU
 SG_ CVC_RunningRange : 23|12@0+ (0.5,0) [0|2047] "km"  MHU
 SG_ CVC_RunningRange_chrg_estSts : 27|2@0+ (1,0) [0|3] ""  MHU
 SG_ CVC_RunningRange_charged : 39|12@0+ (0.5,0) [0|2047] "km"  MHU
 SG_ CVC_HVbatSoc_charged : 55|10@0+ (0.1,0) [0|100] "%"  MHU
 SG_ CVC_HVbatSoc_charged_estStatus : 61|2@0+ (1,0) [0|3] ""  MHU

BO_ 993 CVC_HMI_Info: 8 CVC_I
 SG_ CRC_CVC_HMI_Info : 7|8@0+ (1,0) [0|255] ""  MHU
 SG_ ALIVE_CVC_HMI_Info : 11|4@0+ (1,0) [0|15] ""  MHU
 SG_ CVC_SetCruiseSpd : 23|8@0+ (1,0) [0|200] "km/h"  MHU
 SG_ CVC_MHU_Ack_ChgSche_stt : 27|2@0+ (1,0) [0|3] ""  MHU
 SG_ CVC_MHU_Ack_TargetSOC : 39|7@0+ (1,0) [10|100] "%"  MHU
 SG_ CVC_ValetMode_sts : 47|8@0+ (1,0) [0|255] ""  MHU
 SG_ CVC_ValetMode_MaxSpeedSts : 55|8@0+ (1,0) [0|255] "km/h"  MHU
 SG_ CVC_DashCam_Info : 14|3@0+ (1,0) [0|7] ""  MHU
 SG_ CVC_BEDrvInhibit : 25|2@0+ (1,0) [0|3] ""  MHU

BO_ 358 CVC_Status: 12 CVC_I
 SG_ CRC_CVC_Status : 7|8@0+ (1,0) [0|255] ""  MHU
 SG_ ALIVE_CVC_Status : 11|4@0+ (1,0) [0|15] ""  MHU
 SG_ CVC_DriveModeSts : 18|3@0+ (1,0) [0|7] ""  MHU
 SG_ CVC_DriveReady : 19|1@0+ (1,0) [0|1] ""  MHU
 SG_ CVC_Fault : 22|3@0+ (1,0) [0|7] ""  MHU
 SG_ CVC_VecFltInd : 23|1@0+ (1,0) [0|1] ""  MHU
 SG_ CVC_Creep_Sts : 25|2@0+ (1,0) [0|3] ""  MHU
 SG_ CVC_CruiseCtrlSts : 55|3@0+ (1,0) [0|7] ""  MHU
 SG_ CVC_StsBrakePedalSwitch : 29|2@0+ (1,0) [0|3] ""  MHU
 SG_ CVC_VehicleMode : 31|2@0+ (1,0) [0|3] ""  MHU
 SG_ CVC_CruiseSetSpd : 39|8@0+ (1,0) [30|120] ""  MHU
 SG_ CVC_CruiseFaultIndication : 41|2@0+ (1,0) [0|3] ""  MHU
 SG_ CVC_FuelDetectionSwitchState : 43|2@0+ (1,0) [0|3] ""  MHU
 SG_ CVC_FuelDetectionState : 45|2@0+ (1,0) [0|3] ""  MHU
 SG_ CVC_ParkingChargeRequest : 47|2@0+ (1,0) [0|3] ""  MHU
 SG_ CVC_ParkingChargeModeSet : 51|2@0+ (1,0) [0|3] ""  MHU
 SG_ CVC_REX_StartTimer : 49|10@0+ (1,0) [0|1023] "s"  MHU
 SG_ LV_EM_Rampup_Req : 15|2@0+ (1,0) [0|3] ""  DUMMY_ECU
 SG_ LV_PowerSupply_Status : 52|1@0+ (1,0) [0|1] ""  DUMMY_ECU
 SG_ LV_EM_OTA_Req : 27|2@0+ (1,0) [0|3] ""  DUMMY_ECU
 SG_ CVC_STAT_AirDistributionModeLH : 71|3@0+ (1,0) [0|7] ""  MHU
 SG_ CVC_STAT_AirDistributionModeRH : 68|3@0+ (1,0) [0|7] ""  MHU
 SG_ CVC_STAT_DriverOnly : 65|2@0+ (1,0) [0|3] ""  MHU

BO_ 994 WCBS_IMU_Output: 16 CVC_I
 SG_ CRC_WCBS_IMU_Output : 7|8@0+ (1,0) [0|255] ""  MHU,TBOX,SRR_RR,SRR_FR
 SG_ ALIVE_WCBS_IMU_Output : 11|4@0+ (1,0) [0|15] ""  MHU,TBOX,SRR_RR,SRR_FR
 SG_ WCBS_LateralACC_Valid : 12|1@0+ (1,0) [0|1] ""  MHU,TBOX,SRR_RR,SRR_FR
 SG_ WCBS_LongitudeACC_Valid : 13|1@0+ (1,0) [0|1] ""  MHU,TBOX,SRR_RR,SRR_FR
 SG_ WCBS_VehDynYawRate_Valid : 14|1@0+ (1,0) [0|1] ""  MHU,TBOX,SRR_RR,SRR_FR
 SG_ WCBS_LateralACC : 23|16@0+ (0.005,-60) [-60|60] "m/s2"  MHU,TBOX,SRR_RR,SRR_FR
 SG_ WCBS_LongitudeACC : 39|16@0+ (0.005,-60) [-60|60] "m/s2"  MHU,TBOX,SRR_RR,SRR_FR
 SG_ WCBS_VehDynYawRate : 55|16@0+ (0.02,-300) [-300|300] "deg/s"  MHU,TBOX,SRR_RR,SRR_FR
 SG_ WCBS_LateralACCRaw : 71|16@0+ (0.002,-60) [-60|60] "m/s2"  MHU,TBOX,SRR_RR,SRR_FR
 SG_ WCBS_LongitudeACCRaw : 87|16@0+ (0.002,-60) [-60|60] "m/s2"  MHU,TBOX,SRR_RR,SRR_FR
 SG_ WCBS_VehDynYawRateRaw : 103|16@0+ (0.01,-300) [-300|300] "deg/s"  MHU,TBOX,SRR_RR,SRR_FR
 SG_ WCBS_ESCTarYawRate : 119|16@0+ (0.01,-300) [-300|300] "deg/s"  MHU,TBOX,SRR_RR,SRR_FR

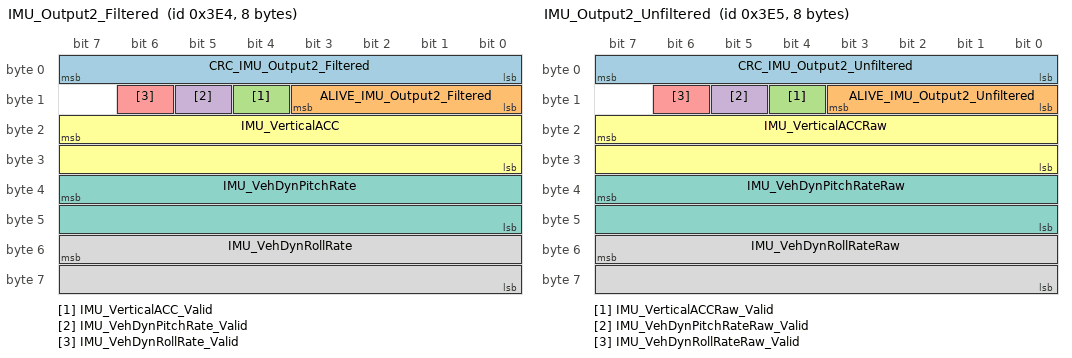
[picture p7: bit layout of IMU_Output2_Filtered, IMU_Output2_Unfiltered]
BO_ 996 IMU_Output2_Filtered: 8 CVC_I
 SG_ CRC_IMU_Output2_Filtered : 7|8@0+ (1,0) [0|255] ""  MHU,TBOX,SRR_RR,SRR_FR
 SG_ ALIVE_IMU_Output2_Filtered : 11|4@0+ (1,0) [0|15] ""  MHU,TBOX,SRR_RR,SRR_FR
 SG_ IMU_VerticalACC_Valid : 12|1@0+ (1,0) [0|1] ""  MHU,TBOX,SRR_RR,SRR_FR
 SG_ IMU_VehDynPitchRate_Valid : 13|1@0+ (1,0) [0|1] ""  MHU,TBOX,SRR_RR,SRR_FR
 SG_ IMU_VehDynRollRate_Valid : 14|1@0+ (1,0) [0|1] ""  MHU,TBOX,SRR_RR,SRR_FR
 SG_ IMU_VerticalACC : 23|16@0+ (0.002,-60) [-60|60] "m/s2"  MHU,TBOX,SRR_RR,SRR_FR
 SG_ IMU_VehDynPitchRate : 39|16@0+ (0.01,-300) [-300|300] "deg/s"  MHU,TBOX,SRR_RR,SRR_FR
 SG_ IMU_VehDynRollRate : 55|16@0+ (0.01,-300) [-300|300] "deg/s"  MHU,TBOX,SRR_RR,SRR_FR

BO_ 997 IMU_Output2_Unfiltered: 8 CVC_I
 SG_ CRC_IMU_Output2_Unfiltered : 7|8@0+ (1,0) [0|255] ""  MHU,TBOX,SRR_RR,SRR_FR
 SG_ ALIVE_IMU_Output2_Unfiltered : 11|4@0+ (1,0) [0|15] ""  MHU,TBOX,SRR_RR,SRR_FR
 SG_ IMU_VerticalACCRaw_Valid : 12|1@0+ (1,0) [0|1] ""  MHU,TBOX,SRR_RR,SRR_FR
 SG_ IMU_VehDynPitchRateRaw_Valid : 13|1@0+ (1,0) [0|1] ""  MHU,TBOX,SRR_RR,SRR_FR
 SG_ IMU_VehDynRollRateRaw_Valid : 14|1@0+ (1,0) [0|1] ""  MHU,TBOX,SRR_RR,SRR_FR
 SG_ IMU_VerticalACCRaw : 23|16@0+ (0.002,-60) [-60|60] "m/s2"  MHU,TBOX,SRR_RR,SRR_FR
 SG_ IMU_VehDynPitchRateRaw : 39|16@0+ (0.01,-300) [-300|300] "deg/s"  MHU,TBOX,SRR_RR,SRR_FR
 SG_ IMU_VehDynRollRateRaw : 55|16@0+ (0.01,-300) [-300|300] "deg/s"  MHU,TBOX,SRR_RR,SRR_FR

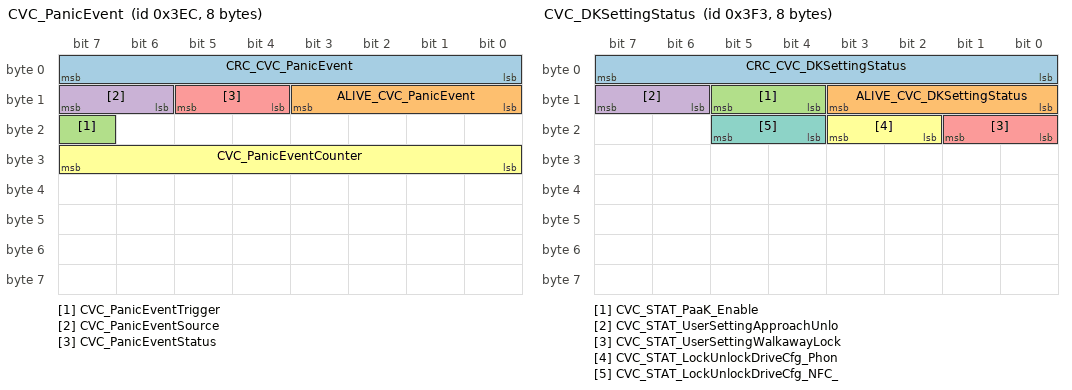
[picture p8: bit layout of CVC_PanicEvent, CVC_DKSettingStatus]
BO_ 1004 CVC_PanicEvent: 8 CVC_I
 SG_ CRC_CVC_PanicEvent : 7|8@0+ (1,0) [0|255] ""  MHU
 SG_ ALIVE_CVC_PanicEvent : 11|4@0+ (1,0) [0|15] ""  MHU
 SG_ CVC_PanicEventTrigger : 23|1@0+ (1,0) [0|1] ""  MHU
 SG_ CVC_PanicEventSource : 15|2@0+ (1,0) [0|3] ""  MHU
 SG_ CVC_PanicEventStatus : 13|2@0+ (1,0) [0|3] ""  MHU
 SG_ CVC_PanicEventCounter : 31|8@0+ (1,0) [0|255] ""  MHU

BO_ 1011 CVC_DKSettingStatus: 8 CVC_I
 SG_ CRC_CVC_DKSettingStatus : 7|8@0+ (1,0) [0|255] ""  MHU
 SG_ ALIVE_CVC_DKSettingStatus : 11|4@0+ (1,0) [0|15] ""  MHU
 SG_ CVC_STAT_PaaK_Enable : 13|2@0+ (1,0) [0|3] ""  MHU
 SG_ CVC_STAT_UserSettingApproachUnlo : 15|2@0+ (1,0) [0|3] ""  MHU
 SG_ CVC_STAT_UserSettingWalkawayLock : 17|2@0+ (1,0) [0|3] ""  MHU
 SG_ CVC_STAT_LockUnlockDriveCfg_Phon : 19|2@0+ (1,0) [0|3] ""  MHU
 SG_ CVC_STAT_LockUnlockDriveCfg_NFC_ : 21|2@0+ (1,0) [0|3] ""  MHU

BO_ 1012 DK_WarnMsg: 8 CVC_I
 SG_ CRC_DK_WarnMsg : 7|8@0+ (1,0) [0|255] ""  MHU
 SG_ ALIVE_DK_WarnMsg : 11|4@0+ (1,0) [0|15] ""  MHU
 SG_ DKAnchor_FrontAnchorStatus_A1 : 12|1@0+ (1,0) [0|1] ""  MHU
 SG_ DKAnchor_LeftAnchorStatus_A2 : 13|1@0+ (1,0) [0|1] ""  MHU
 SG_ DKAnchor_RightAnchorStatus_A3 : 14|1@0+ (1,0) [0|1] ""  MHU
 SG_ DKAnchor_RearAnchorStatus_A4 : 15|1@0+ (1,0) [0|1] ""  MHU
 SG_ DKAnchor_DKCUAnchorStatus_A5 : 16|1@0+ (1,0) [0|1] ""  MHU
 SG_ DKAnchor_CPDAnchorStatus_A6 : 17|1@0+ (1,0) [0|1] ""  MHU
 SG_ DKAnchor_ExtNFCStatus_A7 : 18|1@0+ (1,0) [0|1] ""  DUMMY_ECU
 SG_ DKAnchor_IntNFCStatus_A8 : 19|1@0+ (1,0) [0|1] ""  DUMMY_ECU
 SG_ DK_PhoneKeyPanicAlarmAlert : 20|1@0+ (1,0) [0|1] ""  DUMMY_ECU
 SG_ DK_PhoneKeyBattLowAlert : 21|1@0+ (1,0) [0|1] ""  DUMMY_ECU
 SG_ DK_PhoneKeyIdleStsAlert : 22|1@0+ (1,0) [0|1] ""  DUMMY_ECU
 SG_ DK_VehicleIdleStsAlert : 23|1@0+ (1,0) [0|1] ""  DUMMY_ECU
 SG_ DK_BleOnOffStsAlert : 24|1@0+ (1,0) [0|1] ""  DUMMY_ECU
 SG_ DK_LeftCarAlert : 25|1@0+ (1,0) [0|1] ""  DUMMY_ECU
 SG_ DK_AuthFailAlert : 26|1@0+ (1,0) [0|1] ""  DUMMY_ECU
 SG_ DK_PhoneKeyForgotInsideAlert : 27|1@0+ (1,0) [0|1] ""  DUMMY_ECU
 SG_ DK_PhoneKeyApproachUnlockAlert : 28|1@0+ (1,0) [0|1] ""  DUMMY_ECU
 SG_ DK_PhoneKeyCapabilityAlert : 29|1@0+ (1,0) [0|1] ""  DUMMY_ECU
 SG_ DK_PhoneKeyNfcExteriorAuthFailAl : 30|1@0+ (1,0) [0|1] ""  DUMMY_ECU
 SG_ DK_PhoneKeyNfcInteriorAuthFailAl : 31|1@0+ (1,0) [0|1] ""  DUMMY_ECU
 SG_ DK_PhoneKeyTrunkClosingAlert : 32|1@0+ (1,0) [0|1] ""  DUMMY_ECU
 SG_ DK_PhoneKeyWalkawayLockFailAlert : 33|1@0+ (1,0) [0|1] ""  DUMMY_ECU
 SG_ DK_PhoneKeyRemoteBLECmdFailAlert : 34|1@0+ (1,0) [0|1] ""  DUMMY_ECU

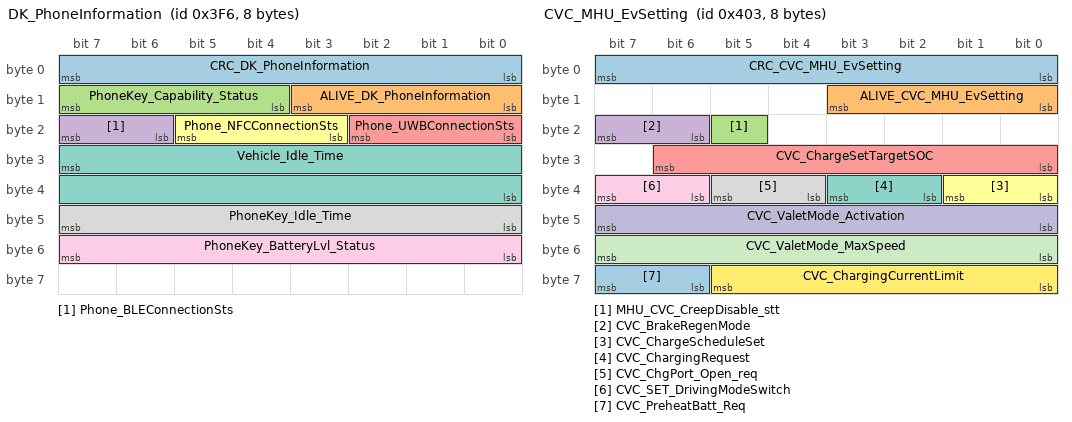
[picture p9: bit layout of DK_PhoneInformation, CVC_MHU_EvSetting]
BO_ 1014 DK_PhoneInformation: 8 CVC_I
 SG_ CRC_DK_PhoneInformation : 7|8@0+ (1,0) [0|255] ""  MHU
 SG_ ALIVE_DK_PhoneInformation : 11|4@0+ (1,0) [0|15] ""  MHU
 SG_ PhoneKey_Capability_Status : 15|4@0+ (1,0) [0|15] ""  MHU
 SG_ Phone_BLEConnectionSts : 23|2@0+ (1,0) [0|3] ""  MHU
 SG_ Phone_UWBConnectionSts : 18|3@0+ (1,0) [0|7] ""  MHU
 SG_ Phone_NFCConnectionSts : 21|3@0+ (1,0) [0|7] ""  MHU
 SG_ Vehicle_Idle_Time : 31|16@0+ (1,0) [0|65535] ""  DUMMY_ECU
 SG_ PhoneKey_Idle_Time : 47|8@0+ (1,0) [0|255] ""  DUMMY_ECU
 SG_ PhoneKey_BatteryLvl_Status : 55|8@0+ (1,0) [0|100] ""  DUMMY_ECU

BO_ 1015 CVC_MFS_Control_Button: 12 CVC_I
 SG_ CRC_CVC_MFS_Control_Button : 7|8@0+ (1,0) [0|255] ""  MHU,FCAM_I,ADCU_I
 SG_ ALIVE_CVC_MFS_Control_Button : 11|4@0+ (1,0) [0|15] ""  MHU,FCAM_I,ADCU_I
 SG_ MFS_L_Lever_Control : 14|3@0+ (1,0) [0|7] ""  MHU,FCAM_I,ADCU_I
 SG_ MFS_L_LeverButton_Control : 24|3@0+ (1,0) [0|7] ""  MHU,FCAM_I,ADCU_I
 SG_ MFS_L_Failure : 17|3@0+ (1,0) [0|7] ""  MHU,FCAM_I,ADCU_I
 SG_ MFS_L_UpControl : 23|3@0+ (1,0) [0|7] ""  MHU,FCAM_I,ADCU_I
 SG_ MFS_L_DownControl : 20|3@0+ (1,0) [0|7] ""  MHU,FCAM_I,ADCU_I
 SG_ MFS_L_LeftControl : 30|3@0+ (1,0) [0|7] ""  MHU,FCAM_I,ADCU_I
 SG_ MFS_L_RightControl : 27|3@0+ (1,0) [0|7] ""  MHU,FCAM_I,ADCU_I
 SG_ MFS_LIN_error : 51|3@0+ (1,0) [0|7] ""  MHU,FCAM_I,ADCU_I
 SG_ MFS_R_Lever_Control : 37|3@0+ (1,0) [0|7] ""  MHU,FCAM_I,ADCU_I
 SG_ MFS_R_LeverButton_Control : 54|3@0+ (1,0) [0|7] ""  MHU,FCAM_I,ADCU_I
 SG_ MFS_R_Failure : 48|3@0+ (1,0) [0|7] ""  MHU,FCAM_I,ADCU_I
 SG_ MFS_R_UpControl : 47|3@0+ (1,0) [0|7] ""  MHU,FCAM_I,ADCU_I
 SG_ MFS_R_DownControl : 34|3@0+ (1,0) [0|7] ""  MHU,FCAM_I,ADCU_I
 SG_ MFS_R_LeftControl : 44|3@0+ (1,0) [0|7] ""  MHU,FCAM_I,ADCU_I
 SG_ MFS_R_RightControl : 41|3@0+ (1,0) [0|7] ""  MHU,FCAM_I,ADCU_I
 SG_ MFS_Delta_Scroll_Wheel_Left : 71|8@0+ (1,0) [0|255] ""  MHU,FCAM_I,ADCU_I
 SG_ MFS_Delta_Scroll_Wheel_Right : 79|8@0+ (1,0) [0|255] ""  MHU,FCAM_I,ADCU_I
 SG_ MFS_Scroll_Wheel_Left_Direction : 61|2@0+ (1,0) [0|3] ""  MHU,FCAM_I,ADCU_I
 SG_ MFS_Scroll_Wheel_Right_Direction : 59|2@0+ (1,0) [0|3] ""  MHU,FCAM_I,ADCU_I
 SG_ MFS_Scroll_Wheel_Left_Press : 57|2@0+ (1,0) [0|3] ""  MHU,FCAM_I,ADCU_I
 SG_ MFS_Scroll_Wheel_Right_Press : 85|2@0+ (1,0) [0|3] ""  MHU,FCAM_I,ADCU_I
 SG_ MFS_Scroll_Wheel_Left_Valid : 86|1@0+ (1,0) [0|1] ""  MHU,FCAM_I,ADCU_I
 SG_ MFS_Scroll_Wheel_Right_Valid : 87|1@0+ (1,0) [0|1] ""  MHU,FCAM_I,ADCU_I
 SG_ MFS_Scroll_Wheel_Left_ID : 83|4@0+ (1,0) [0|15] ""  MHU,FCAM_I,ADCU_I
 SG_ MFS_Scroll_Wheel_Right_ID : 91|4@0+ (1,0) [0|15] ""  MHU,FCAM_I,ADCU_I

BO_ 1027 CVC_MHU_EvSetting: 8 CVC_I
 SG_ CRC_CVC_MHU_EvSetting : 7|8@0+ (1,0) [0|255] ""  FCAM_I,SRR_RR,ADCU_I
 SG_ ALIVE_CVC_MHU_EvSetting : 11|4@0+ (1,0) [0|15] ""  FCAM_I,SRR_RR,ADCU_I
 SG_ MHU_CVC_CreepDisable_stt : 21|1@0+ (1,0) [0|1] ""  FCAM_I,SRR_RR,ADCU_I
 SG_ CVC_BrakeRegenMode : 23|2@0+ (1,0) [0|3] ""  FCAM_I,SRR_RR,ADCU_I
 SG_ CVC_ChargeSetTargetSOC : 30|7@0+ (1,0) [10|100] "%"  FCAM_I,SRR_RR,ADCU_I
 SG_ CVC_ChargeScheduleSet : 33|2@0+ (1,0) [0|3] ""  FCAM_I,SRR_RR,ADCU_I
 SG_ CVC_ChargingRequest : 35|2@0+ (1,0) [0|3] ""  FCAM_I,SRR_RR,ADCU_I
 SG_ CVC_ChgPort_Open_req : 37|2@0+ (1,0) [0|3] ""  FCAM_I,SRR_RR,ADCU_I
 SG_ CVC_SET_DrivingModeSwitch : 39|2@0+ (1,0) [0|3] ""  FCAM_I,SRR_RR,ADCU_I
 SG_ CVC_ValetMode_Activation : 47|8@0+ (1,0) [0|255] ""  FCAM_I,SRR_RR,ADCU_I
 SG_ CVC_ValetMode_MaxSpeed : 55|8@0+ (1,0) [0|255] "km/h"  FCAM_I,SRR_RR,ADCU_I
 SG_ CVC_ChargingCurrentLimit : 61|6@0+ (1,0) [0|62] "A"  FCAM_I,SRR_RR,ADCU_I
 SG_ CVC_PreheatBatt_Req : 63|2@0+ (1,0) [0|2] ""  MHU,FCAM_I,SRR_RR,ADCU_I

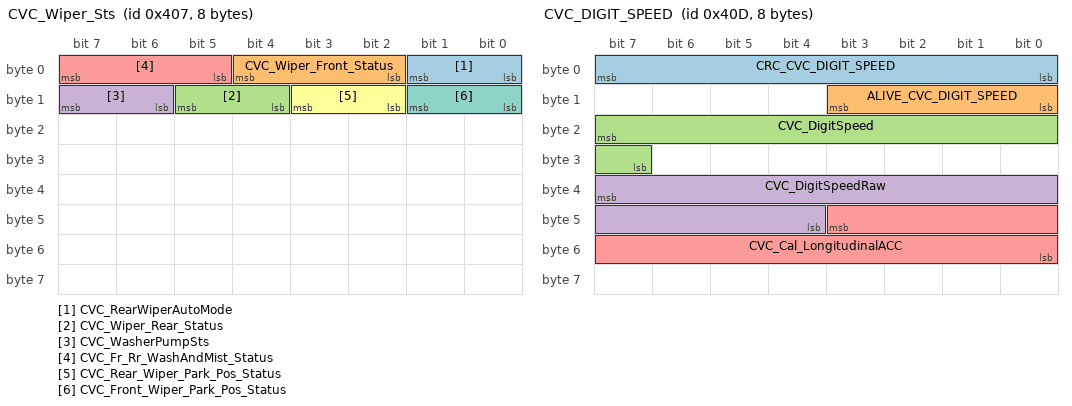
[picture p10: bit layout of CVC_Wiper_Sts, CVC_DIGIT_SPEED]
BO_ 1031 CVC_Wiper_Sts: 8 CVC_I
 SG_ CVC_RearWiperAutoMode : 1|2@0+ (1,0) [0|3] ""  MHU,FCAM_I,ADCU_I
 SG_ CVC_Wiper_Front_Status : 4|3@0+ (1,0) [0|7] ""  FCAM_I,ADCU_I
 SG_ CVC_Wiper_Rear_Status : 13|2@0+ (1,0) [0|3] ""  FCAM_I,ADCU_I
 SG_ CVC_WasherPumpSts : 15|2@0+ (1,0) [0|3] ""  FCAM_I,ADCU_I
 SG_ CVC_Fr_Rr_WashAndMist_Status : 7|3@0+ (1,0) [0|7] ""  FCAM_I,ADCU_I
 SG_ CVC_Rear_Wiper_Park_Pos_Status : 11|2@0+ (1,0) [0|3] ""  FCAM_I,ADCU_I
 SG_ CVC_Front_Wiper_Park_Pos_Status : 9|2@0+ (1,0) [0|3] ""  FCAM_I,ADCU_I

BO_ 1037 CVC_DIGIT_SPEED: 8 CVC_I
 SG_ CRC_CVC_DIGIT_SPEED : 7|8@0+ (1,0) [0|255] ""  MHU,FCAM_I,SRR_RR,ADCU_I
 SG_ ALIVE_CVC_DIGIT_SPEED : 11|4@0+ (1,0) [0|15] ""  MHU,FCAM_I,SRR_RR,ADCU_I
 SG_ CVC_DigitSpeed : 23|9@0+ (1,0) [0|300] "km/h"  MHU,FCAM_I,SRR_RR,ADCU_I
 SG_ CVC_DigitSpeedRaw : 39|12@0+ (0.1,0) [0|300] "km/h"  MHU,FCAM_I,SRR_RR,ADCU_I
 SG_ CVC_Cal_LongitudinalACC : 43|12@0+ (0.01,-20) [-20|20] "m/s2"  MHU,FCAM_I,SRR_RR,ADCU_I

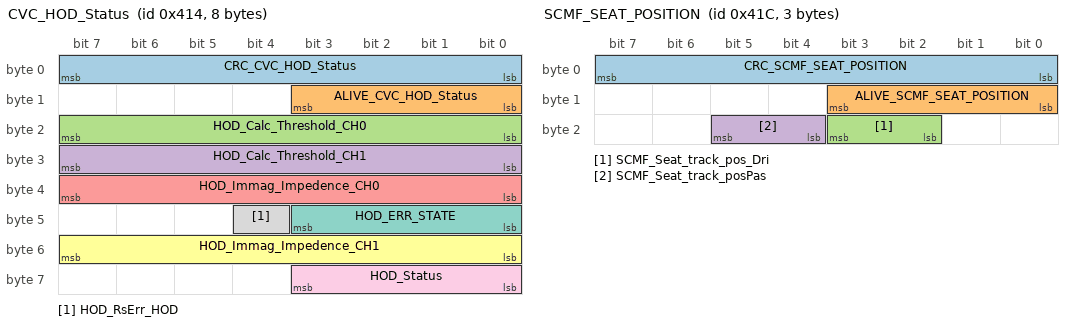
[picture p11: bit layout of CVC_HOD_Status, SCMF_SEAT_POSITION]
BO_ 1044 CVC_HOD_Status: 8 CVC_I
 SG_ CRC_CVC_HOD_Status : 7|8@0+ (1,0) [0|255] ""  FCAM_I,ADCU_I
 SG_ ALIVE_CVC_HOD_Status : 11|4@0+ (1,0) [0|15] ""  FCAM_I,ADCU_I
 SG_ HOD_Calc_Threshold_CH0 : 23|8@0+ (1,0) [0|255] ""  FCAM_I,ADCU_I
 SG_ HOD_Calc_Threshold_CH1 : 31|8@0+ (1,0) [0|255] ""  FCAM_I,ADCU_I
 SG_ HOD_Immag_Impedence_CH0 : 39|8@0+ (1,0) [0|255] ""  FCAM_I,ADCU_I
 SG_ HOD_Immag_Impedence_CH1 : 55|8@0+ (1,0) [0|255] ""  FCAM_I,ADCU_I
 SG_ HOD_ERR_STATE : 43|4@0+ (1,0) [0|15] ""  FCAM_I,ADCU_I
 SG_ HOD_RsErr_HOD : 44|1@0+ (1,0) [0|1] ""  FCAM_I,ADCU_I
 SG_ HOD_Status : 59|4@0+ (1,0) [0|15] ""  FCAM_I,ADCU_I

BO_ 1052 SCMF_SEAT_POSITION: 3 CVC_I
 SG_ CRC_SCMF_SEAT_POSITION : 7|8@0+ (1,0) [0|255] ""  MHU
 SG_ ALIVE_SCMF_SEAT_POSITION : 11|4@0+ (1,0) [0|15] ""  MHU
 SG_ SCMF_Seat_track_pos_Dri : 19|2@0+ (1,0) [0|3] ""  MHU
 SG_ SCMF_Seat_track_posPas : 21|2@0+ (1,0) [0|3] ""  MHU

BO_ 1055 OCS_PasSts: 3 CVC_I
 SG_ CRC_OCS_PasSts : 7|8@0+ (1,0) [0|255] ""  MHU
 SG_ ALIVE_OCS_PasSts : 11|4@0+ (1,0) [0|15] ""  MHU
 SG_ OCS_Passenger_class_stat : 17|2@0+ (1,0) [0|3] ""  MHU

BO_ 1059 AVAS_Status: 8 CVC_I
 SG_ AVAS_BatteryUnderVoltage : 0|1@0+ (1,0) [0|1] ""  MHU,AMP
 SG_ AVAS_BatteryOverVoltage : 1|1@0+ (1,0) [0|1] ""  MHU,AMP
 SG_ AVAS_VINInfoNotPrgm : 2|1@0+ (1,0) [0|1] ""  MHU,AMP
 SG_ AVAS_AMPVoltSplDrvOperationFail : 3|1@0+ (1,0) [0|1] ""  MHU,AMP
 SG_ AVAS_AMPIntFaultOverCurr : 4|1@0+ (1,0) [0|1] ""  MHU,AMP
 SG_ AVAS_AMPInternalFaultDCError : 5|1@0+ (1,0) [0|1] ""  MHU,AMP
 SG_ AVAS_AMPInternalFaultOverTemp : 6|1@0+ (1,0) [0|1] ""  MHU,AMP
 SG_ AVAS_AMPInternalFaultClockError : 7|1@0+ (1,0) [0|1] ""  MHU,AMP
 SG_ AVAS_SpkrMntPwrSwDrvHighFlt : 8|1@0+ (1,0) [0|1] ""  MHU,AMP
 SG_ AVAS_SpkrMntPwrSwDrvLowFlt : 9|1@0+ (1,0) [0|1] ""  MHU,AMP
 SG_ AVAS_InternalSpeakerOpen : 10|1@0+ (1,0) [0|1] ""  MHU,AMP
 SG_ AVAS_ECUMalFlshOperationErr : 11|1@0+ (1,0) [0|1] ""  MHU,AMP
 SG_ AVAS_ECUMalfunctionRamFailure : 12|1@0+ (1,0) [0|1] ""  MHU,AMP
 SG_ AVAS_ECUMalEEPROMFailure : 13|1@0+ (1,0) [0|1] ""  MHU,AMP
 SG_ AVAS_CANBusOff : 14|1@0+ (1,0) [0|1] ""  MHU,AMP
 SG_ AVAS_LossCommVehicleSpeed : 15|1@0+ (1,0) [0|1] ""  MHU,AMP
 SG_ AVAS_LossCommGearPosition : 16|1@0+ (1,0) [0|1] ""  MHU,AMP
 SG_ AVAS_LossCommAVASCloseCmd : 17|1@0+ (1,0) [0|1] ""  MHU,AMP
 SG_ AVAS_EnableSts : 20|1@0+ (1,0) [0|1] ""  MHU,AMP

BO_ 1064 CVC_CH_1: 1 CVC_I
 SG_ TRMFitted : 2|2@0+ (1,0) [0|3] ""  MHU,FCAM_I,SRR_RR,ADCU_I

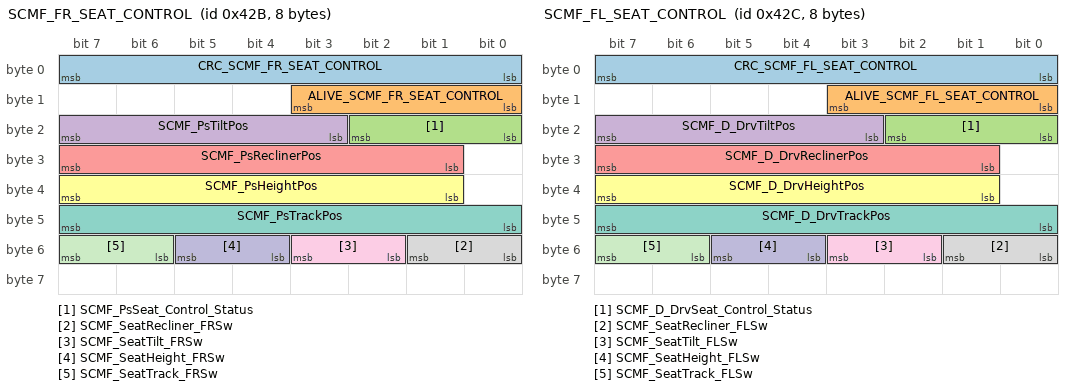
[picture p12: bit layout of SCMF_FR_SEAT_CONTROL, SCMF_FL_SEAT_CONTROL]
BO_ 1067 SCMF_FR_SEAT_CONTROL: 8 CVC_I
 SG_ CRC_SCMF_FR_SEAT_CONTROL : 7|8@0+ (1,0) [0|255] ""  MHU
 SG_ ALIVE_SCMF_FR_SEAT_CONTROL : 11|4@0+ (1,0) [0|15] ""  MHU
 SG_ SCMF_PsSeat_Control_Status : 18|3@0+ (1,0) [0|7] ""  MHU
 SG_ SCMF_PsTiltPos : 23|5@0+ (1,0) [0|31] "mm"  MHU
 SG_ SCMF_PsReclinerPos : 31|7@0+ (1,-54) [-54|24] "degree"  MHU
 SG_ SCMF_PsHeightPos : 39|7@0+ (1,-30) [-30|35] "mm"  MHU
 SG_ SCMF_PsTrackPos : 47|8@0+ (1,-40) [-40|190] "mm"  MHU
 SG_ SCMF_SeatRecliner_FRSw : 49|2@0+ (1,0) [0|3] ""  MHU
 SG_ SCMF_SeatTilt_FRSw : 51|2@0+ (1,0) [0|3] ""  MHU
 SG_ SCMF_SeatHeight_FRSw : 53|2@0+ (1,0) [0|3] ""  MHU
 SG_ SCMF_SeatTrack_FRSw : 55|2@0+ (1,0) [0|3] ""  MHU

BO_ 1068 SCMF_FL_SEAT_CONTROL: 8 CVC_I
 SG_ CRC_SCMF_FL_SEAT_CONTROL : 7|8@0+ (1,0) [0|255] ""  MHU
 SG_ ALIVE_SCMF_FL_SEAT_CONTROL : 11|4@0+ (1,0) [0|15] ""  MHU
 SG_ SCMF_D_DrvSeat_Control_Status : 18|3@0+ (1,0) [0|7] ""  MHU
 SG_ SCMF_D_DrvTiltPos : 23|5@0+ (1,0) [0|31] "mm"  MHU
 SG_ SCMF_D_DrvReclinerPos : 31|7@0+ (1,-54) [-54|24] "degree"  MHU
 SG_ SCMF_D_DrvHeightPos : 39|7@0+ (1,-30) [-30|35] "mm"  MHU
 SG_ SCMF_D_DrvTrackPos : 47|8@0+ (1,-40) [-40|190] "mm"  MHU
 SG_ SCMF_SeatRecliner_FLSw : 49|2@0+ (1,0) [0|3] ""  MHU
 SG_ SCMF_SeatTilt_FLSw : 51|2@0+ (1,0) [0|3] ""  MHU
 SG_ SCMF_SeatHeight_FLSw : 53|2@0+ (1,0) [0|3] ""  MHU
 SG_ SCMF_SeatTrack_FLSw : 55|2@0+ (1,0) [0|3] ""  MHU

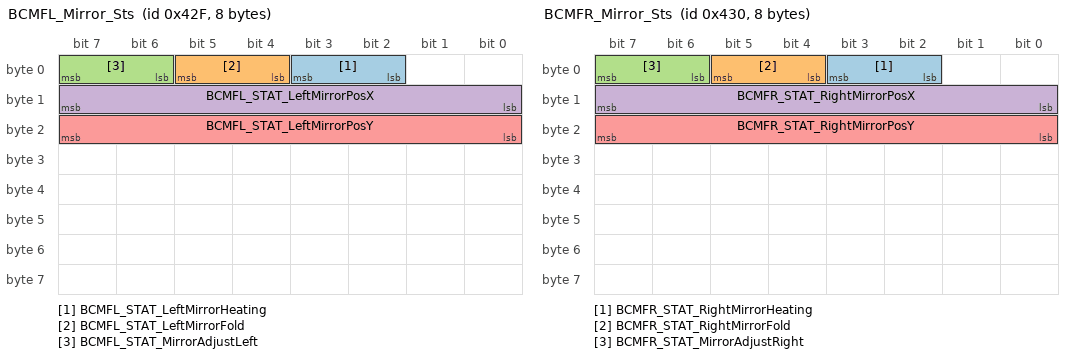
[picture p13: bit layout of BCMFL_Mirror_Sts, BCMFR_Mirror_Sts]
BO_ 1071 BCMFL_Mirror_Sts: 8 CVC_I
 SG_ BCMFL_STAT_LeftMirrorHeating : 3|2@0+ (1,0) [0|3] "" Vector__XXX
 SG_ BCMFL_STAT_LeftMirrorFold : 5|2@0+ (1,0) [0|3] ""  MHU,ADCU_I
 SG_ BCMFL_STAT_MirrorAdjustLeft : 7|2@0+ (1,0) [0|3] "" Vector__XXX
 SG_ BCMFL_STAT_LeftMirrorPosX : 15|8@0+ (1,-15) [-15|15] "Degree" Vector__XXX
 SG_ BCMFL_STAT_LeftMirrorPosY : 23|8@0+ (1,-15) [-15|15] "Degree" Vector__XXX

BO_ 1072 BCMFR_Mirror_Sts: 8 CVC_I
 SG_ BCMFR_STAT_RightMirrorHeating : 3|2@0+ (1,0) [0|3] "" Vector__XXX
 SG_ BCMFR_STAT_RightMirrorFold : 5|2@0+ (1,0) [0|3] ""  MHU,ADCU_I
 SG_ BCMFR_STAT_MirrorAdjustRight : 7|2@0+ (1,0) [0|3] "" Vector__XXX
 SG_ BCMFR_STAT_RightMirrorPosX : 15|8@0+ (1,-15) [-15|15] "Degree" Vector__XXX
 SG_ BCMFR_STAT_RightMirrorPosY : 23|8@0+ (1,-15) [-15|15] "Degree" Vector__XXX

BO_ 181 BCM_WindowsFR_Status: 8 CVC_I
 SG_ CRC_BCM_WindowsFR_Status : 7|8@0+ (1,0) [0|255] ""  ADCU_I
 SG_ ALIVE_BCM_WindowsFR_Status : 11|4@0+ (1,0) [0|15] ""  ADCU_I
 SG_ BCMFR_WindowsFR_AntiPinch_Warn : 19|2@0+ (1,0) [0|3] ""  ADCU_I
 SG_ BCMFR_WindowFR_Learning_Sts : 23|2@0+ (1,0) [0|3] ""  ADCU_I
 SG_ BCMFR_WindowFR_Suppression_Warn : 25|2@0+ (1,0) [0|2] ""  ADCU_I
 SG_ BCMFR_WindowFR_LockActive : 26|1@0+ (1,0) [0|1] ""  ADCU_I
 SG_ BCMFR_WindowFR_ThermalProtect : 29|2@0+ (1,0) [0|2] ""  ADCU_I
 SG_ BCMFR_WindowFR_Error : 27|1@0+ (1,0) [0|1] ""  ADCU_I
 SG_ BCMFR_WindowsRR_AntiPinch_Warn : 33|2@0+ (1,0) [0|3] ""  ADCU_I
 SG_ BCMFR_WindowRR_LockActive : 35|1@0+ (1,0) [0|1] ""  ADCU_I
 SG_ BCMFR_WindowRR_Error : 34|1@0+ (1,0) [0|1] ""  ADCU_I
 SG_ BCMFR_WindowRR_Learning_Sts : 37|2@0+ (1,0) [0|3] ""  ADCU_I
 SG_ BCMFR_WindowRR_Suppression_Warn : 39|2@0+ (1,0) [0|2] ""  ADCU_I
 SG_ BCMFR_WindowRR_ThermalProtect : 41|2@0+ (1,0) [0|2] ""  ADCU_I
 SG_ BCMFR_WindowBtnPress_FrontPass : 44|3@0+ (1,0) [0|4] ""  ADCU_I
 SG_ Window_Position_FR : 51|4@0+ (1,0) [0|15] ""  ADCU_I
 SG_ Window_Position_RR : 55|4@0+ (1,0) [0|15] ""  ADCU_I
 SG_ BCMFR_WindowBtnPress_RR : 47|3@0+ (1,0) [0|4] ""  ADCU_I
 SG_ BCMFR_WindowFR_Malfunction_Warn : 63|2@0+ (1,0) [0|3] ""  ADCU_I
 SG_ BCMFR_WindowRR_Malfunction_Warn : 61|2@0+ (1,0) [0|3] ""  ADCU_I

BO_ 535 BCMRE_ExteriorLight_STS: 12 CVC_I
 SG_ BCM_PositionLight_RL_STS : 2|3@0+ (1,0) [0|4] ""  ADCU_I
 SG_ BCM_PositionLight_RR_STS : 5|3@0+ (1,0) [0|4] ""  ADCU_I
 SG_ BCM_TurnIndicator_RL_STS : 10|3@0+ (1,0) [0|4] ""  ADCU_I
 SG_ BCM_TurnIndicator_RR_STS : 13|3@0+ (1,0) [0|4] ""  ADCU_I
 SG_ BCM_ReverseLamp_RL_STS : 18|3@0+ (1,0) [0|4] ""  ADCU_I
 SG_ BCM_ReverseLamp_RR_STS : 21|3@0+ (1,0) [0|4] ""  ADCU_I
 SG_ BCM_BrakeLight_RL_STS : 26|3@0+ (1,0) [0|4] ""  ADCU_I
 SG_ BCM_BrakeLight_RR_STS : 29|3@0+ (1,0) [0|4] ""  ADCU_I
 SG_ BCM_RearFogLamp_RR_STS : 34|3@0+ (1,0) [0|4] ""  ADCU_I
 SG_ BCM_BrakeLight_Center_STS : 37|3@0+ (1,0) [0|4] ""  ADCU_I
 SG_ BCM_LicensePlateLamp_RE_STS : 42|3@0+ (1,0) [0|4] ""  ADCU_I
 SG_ BCM_RearFogLamp_RL_STS : 45|3@0+ (1,0) [0|4] ""  ADCU_I
 SG_ BCM_SignatureRear_STS : 55|3@0+ (1,0) [0|4] ""  ADCU_I
 SG_ BCMRE_WelcomeFarewellLight_STS : 71|3@0+ (1,0) [0|7] ""  ADCU_I
 SG_ BCM_PositionLight_RM_STS : 68|3@0+ (1,0) [0|4] ""  ADCU_I
 SG_ BCM_ParkingLight_RL_STS : 65|2@0+ (1,0) [0|3] ""  ADCU_I
 SG_ BCM_ParkingLight_RM_STS : 79|2@0+ (1,0) [0|3] ""  ADCU_I
 SG_ BCM_ParkingLight_RR_STS : 77|2@0+ (1,0) [0|3] ""  ADCU_I

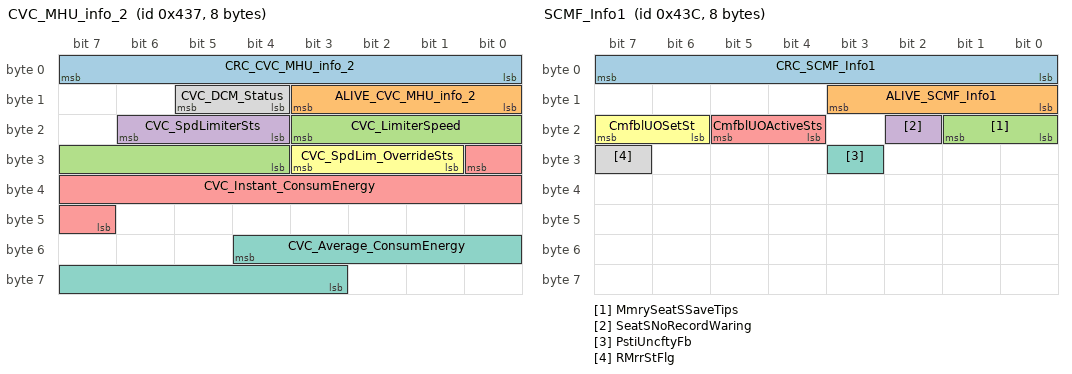
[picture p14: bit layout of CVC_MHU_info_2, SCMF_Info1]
BO_ 1079 CVC_MHU_info_2: 8 CVC_I
 SG_ CRC_CVC_MHU_info_2 : 7|8@0+ (1,0) [0|255] ""  MHU
 SG_ ALIVE_CVC_MHU_info_2 : 11|4@0+ (1,0) [0|15] ""  MHU
 SG_ CVC_LimiterSpeed : 19|8@0+ (1,0) [0|200] "km/h"  MHU
 SG_ CVC_SpdLimiterSts : 22|3@0+ (1,0) [0|7] ""  MHU
 SG_ CVC_Instant_ConsumEnergy : 24|10@0+ (0.1,0) [0|100] "kWh/100km"  MHU
 SG_ CVC_SpdLim_OverrideSts : 27|3@0+ (10,0) [0|30] "km/h"  MHU
 SG_ CVC_Average_ConsumEnergy : 52|10@0+ (0.1,0) [0|100] "kWh/100km"  MHU
 SG_ CVC_DCM_Status : 13|2@0+ (1,0) [0|3] ""  MHU,ADCU_I

BO_ 1082 CVC_MHU_info: 8 CVC_I
 SG_ CRC_CVC_MHU_info : 7|8@0+ (1,0) [0|255] ""  MHU
 SG_ ALIVE_CVC_MHU_info : 11|4@0+ (1,0) [0|15] ""  MHU
 SG_ CVC_BrakeRegenMode : 13|2@0+ (1,0) [0|3] ""  MHU
 SG_ CVC_CreepEnable_stt : 14|1@0+ (1,0) [0|1] ""  MHU
 SG_ CVC_PowerRegenGaugeDisplay : 23|8@0+ (1,-100) [-100|100] "%"  MHU
 SG_ CVC_Regen_available : 31|2@0+ (1,0) [0|3] ""  MHU
 SG_ CVC_StoppingMode_stt : 37|3@0+ (1,0) [0|7] ""  MHU
 SG_ CVC_AutoP_Feedback : 39|2@0+ (1,0) [0|3] ""  MHU
 SG_ CVC_SOC_display : 46|10@0+ (0.1,0) [0|100] "%"  MHU
 SG_ CVC_Hvbatt_charging_stt : 58|1@0+ (1,0) [0|1] ""  MHU
 SG_ CVC_PreheatBatt_Sts : 15|1@0+ (1,0) [0|1] ""  MHU
 SG_ CVC_HDC_Status : 34|3@0+ (1,0) [0|7] ""  MHU
 SG_ CVC_STAT_RearAircondition : 52|2@0+ (1,0) [0|3] ""  MHU
 SG_ CVC_STAT_AirDistributionRear : 50|2@0+ (1,0) [0|3] ""  MHU
 SG_ CVC_STAT_RearFanSpeed : 62|4@0+ (1,0) [0|15] ""  MHU
 SG_ CVC_STAT_TempRear : 29|6@0+ (0.5,16) [16|32] "degC"  MHU
 SG_ CVC_STAT_RearAuto : 48|2@0+ (1,0) [0|3] ""  MHU

BO_ 1084 SCMF_Info1: 8 CVC_I
 SG_ CRC_SCMF_Info1 : 7|8@0+ (1,0) [0|255] ""  MHU
 SG_ ALIVE_SCMF_Info1 : 11|4@0+ (1,0) [0|15] ""  MHU
 SG_ MmrySeatSSaveTips : 17|2@0+ (1,0) [0|3] ""  MHU
 SG_ SeatSNoRecordWaring : 18|1@0+ (1,0) [0|1] ""  MHU
 SG_ CmfblUOActiveSts : 21|2@0+ (1,0) [0|3] ""  MHU
 SG_ CmfblUOSetSt : 23|2@0+ (1,0) [0|3] ""  MHU
 SG_ PstiUncftyFb : 27|1@0+ (1,0) [0|1] ""  MHU
 SG_ RMrrStFlg : 31|1@0+ (1,0) [0|1] ""  MHU

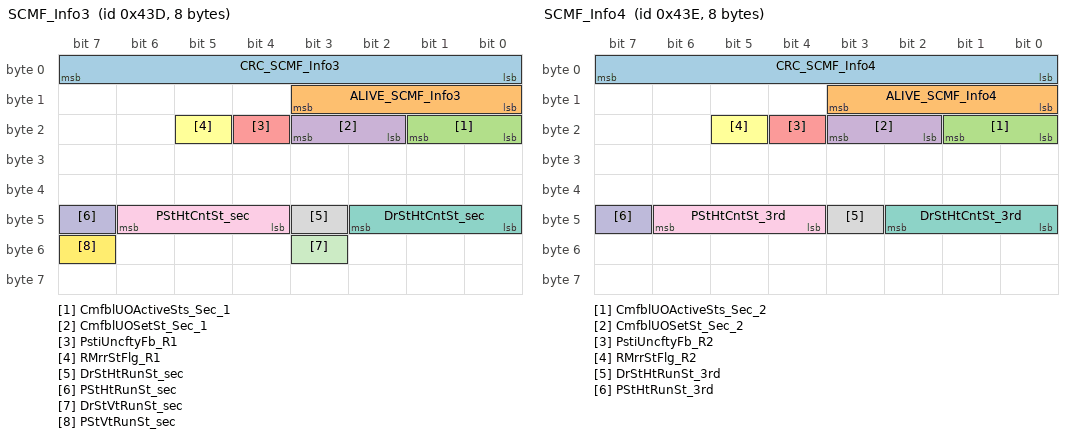
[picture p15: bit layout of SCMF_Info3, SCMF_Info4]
BO_ 1085 SCMF_Info3: 8 CVC_I
 SG_ CRC_SCMF_Info3 : 7|8@0+ (1,0) [0|255] ""  MHU
 SG_ ALIVE_SCMF_Info3 : 11|4@0+ (1,0) [0|15] ""  MHU
 SG_ CmfblUOActiveSts_Sec_1 : 17|2@0+ (1,0) [0|3] ""  MHU
 SG_ CmfblUOSetSt_Sec_1 : 19|2@0+ (1,0) [0|3] ""  MHU
 SG_ PstiUncftyFb_R1 : 20|1@0+ (1,0) [0|1] ""  MHU
 SG_ RMrrStFlg_R1 : 21|1@0+ (1,0) [0|1] ""  MHU
 SG_ DrStHtCntSt_sec : 42|3@0+ (1,0) [0|7] ""  MHU
 SG_ DrStHtRunSt_sec : 43|1@0+ (1,0) [0|1] ""  MHU
 SG_ PStHtCntSt_sec : 46|3@0+ (1,0) [0|7] ""  MHU
 SG_ PStHtRunSt_sec : 47|1@0+ (1,0) [0|1] ""  MHU
 SG_ DrStVtRunSt_sec : 51|1@0+ (1,0) [0|1] ""  MHU
 SG_ PStVtRunSt_sec : 55|1@0+ (1,0) [0|1] ""  MHU

BO_ 1086 SCMF_Info4: 8 CVC_I
 SG_ CRC_SCMF_Info4 : 7|8@0+ (1,0) [0|255] ""  MHU
 SG_ ALIVE_SCMF_Info4 : 11|4@0+ (1,0) [0|15] ""  MHU
 SG_ CmfblUOActiveSts_Sec_2 : 17|2@0+ (1,0) [0|3] ""  MHU
 SG_ CmfblUOSetSt_Sec_2 : 19|2@0+ (1,0) [0|3] ""  MHU
 SG_ PstiUncftyFb_R2 : 20|1@0+ (1,0) [0|1] ""  MHU
 SG_ RMrrStFlg_R2 : 21|1@0+ (1,0) [0|1] ""  MHU
 SG_ DrStHtCntSt_3rd : 42|3@0+ (1,0) [0|7] ""  MHU
 SG_ DrStHtRunSt_3rd : 43|1@0+ (1,0) [0|1] ""  MHU
 SG_ PStHtCntSt_3rd : 46|3@0+ (1,0) [0|7] ""  MHU
 SG_ PStHtRunSt_3rd : 47|1@0+ (1,0) [0|1] ""  MHU

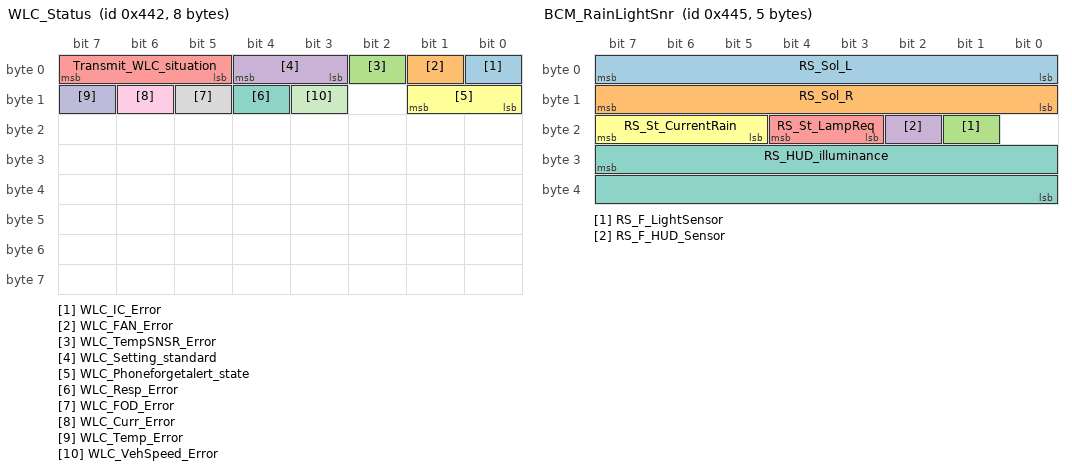
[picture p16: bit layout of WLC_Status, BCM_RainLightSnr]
BO_ 1090 WLC_Status: 8 CVC_I
 SG_ WLC_IC_Error : 0|1@0+ (1,0) [0|1] ""  MHU
 SG_ WLC_FAN_Error : 1|1@0+ (1,0) [0|1] ""  MHU
 SG_ WLC_TempSNSR_Error : 2|1@0+ (1,0) [0|1] ""  MHU
 SG_ WLC_Setting_standard : 4|2@0+ (1,0) [0|3] ""  MHU
 SG_ Transmit_WLC_situation : 7|3@0+ (1,0) [0|7] ""  MHU
 SG_ WLC_Phoneforgetalert_state : 9|2@0+ (1,0) [0|3] ""  MHU
 SG_ WLC_Resp_Error : 12|1@0+ (1,0) [0|1] ""  MHU
 SG_ WLC_FOD_Error : 13|1@0+ (1,0) [0|1] ""  MHU
 SG_ WLC_Curr_Error : 14|1@0+ (1,0) [0|1] ""  MHU
 SG_ WLC_Temp_Error : 15|1@0+ (1,0) [0|1] ""  MHU
 SG_ WLC_VehSpeed_Error : 11|1@0+ (1,0) [0|1] ""  MHU

BO_ 1093 BCM_RainLightSnr: 5 CVC_I
 SG_ RS_Sol_L : 7|8@0+ (5,0) [0|1000] "W/m^2"  MHU,ADCU_I
 SG_ RS_Sol_R : 15|8@0+ (5,0) [0|1000] "W/m^2"  MHU,ADCU_I
 SG_ RS_F_LightSensor : 17|1@0+ (1,0) [0|1] ""  MHU,ADCU_I
 SG_ RS_F_HUD_Sensor : 18|1@0+ (1,0) [0|1] ""  MHU,ADCU_I
 SG_ RS_St_LampReq : 20|2@0+ (1,0) [0|3] ""  MHU,ADCU_I
 SG_ RS_St_CurrentRain : 23|3@0+ (1,0) [0|7] ""  MHU,ADCU_I
 SG_ RS_HUD_illuminance : 31|16@0+ (1,0) [0|10000] "cd/m2"  MHU,ADCU_I

BO_ 529 BCMFL_ExteriorLight_STS: 16 CVC_I
 SG_ CRC_BCMFL_ExteriorLight_STS : 7|8@0+ (1,0) [0|255] ""  ADCU_I
 SG_ ALIVE_BCMFL_ExteriorLight_STS : 11|4@0+ (1,0) [0|15] ""  ADCU_I
 SG_ BCM_LowBeam_FL_Sts : 102|3@0+ (1,0) [0|4] ""  ADCU_I
 SG_ BCM_HighBeam_FL_Sts : 98|3@0+ (1,0) [0|4] ""  ADCU_I
 SG_ BCM_TurnIndicator_FL_STS : 18|3@0+ (1,0) [0|4] ""  ADCU_I
 SG_ BCM_PositionLight_FL_STS : 34|3@0+ (1,0) [0|4] ""  ADCU_I
 SG_ BCM_RearFogLamp_FL_STS : 46|3@0+ (1,0) [0|4] ""  DUMMY_ECU
 SG_ BCM_HeightSensorSTS_Front : 71|2@0+ (1,0) [0|3] ""  DUMMY_ECU
 SG_ BCM_HeightSensorValue_Front : 69|14@0+ (0.5,0) [0|8191.5] ""  DUMMY_ECU
 SG_ BCM_MirrorLED_FL_STS : 82|3@0+ (1,0) [0|4] ""  DUMMY_ECU
 SG_ BCM_HazardButton_FL_STS : 86|3@0+ (1,0) [0|4] ""  DUMMY_ECU
 SG_ BCM_DaytimeRunningLight_FL_Sts : 90|3@0+ (1,0) [0|4] ""  DUMMY_ECU
 SG_ BCM_FrontFogLamp_FL_STS : 94|3@0+ (1,0) [0|4] ""  DUMMY_ECU

BO_ 1100 SCMF_Info2: 8 CVC_I
 SG_ SCMF_RLSeatVent_Sts : 15|3@0+ (1,0) [0|7] ""  MHU
 SG_ SCMF_RRSeatVent_Sts : 20|3@0+ (1,0) [0|7] ""  MHU
 SG_ MmryFctOprtSetSt : 23|3@0+ (1,0) [0|7] ""  MHU
 SG_ PsStHtCntSt : 26|3@0+ (1,0) [0|7] ""  MHU
 SG_ PsStHtRunSt : 27|1@0+ (1,0) [0|1] ""  MHU
 SG_ DrStHtCntSt : 30|3@0+ (1,0) [0|7] ""  MHU
 SG_ DrStHtRunSt : 31|1@0+ (1,0) [0|1] ""  MHU
 SG_ SCMF_FRSeatVent_Sts : 34|3@0+ (1,0) [0|7] ""  MHU
 SG_ PsStVtRunSt : 35|1@0+ (1,0) [0|1] ""  MHU
 SG_ SCMF_FLSeatVent_Sts : 38|3@0+ (1,0) [0|7] ""  MHU
 SG_ DrStVtRunSt : 39|1@0+ (1,0) [0|1] ""  MHU
 SG_ Key2AscitAcuntSt : 43|4@0+ (1,0) [0|15] ""  MHU
 SG_ Key1AscitAcuntSt : 47|4@0+ (1,0) [0|15] ""  MHU
 SG_ Key4AscitAcuntSt : 51|4@0+ (1,0) [0|15] ""  MHU
 SG_ Key3AscitAcuntSt : 55|4@0+ (1,0) [0|15] ""  MHU
 SG_ MmryDrvSeatSSetReq : 59|4@0+ (1,0) [0|15] ""  MHU
 SG_ MmryPsSeatSSetReq : 63|4@0+ (1,0) [0|15] ""  MHU

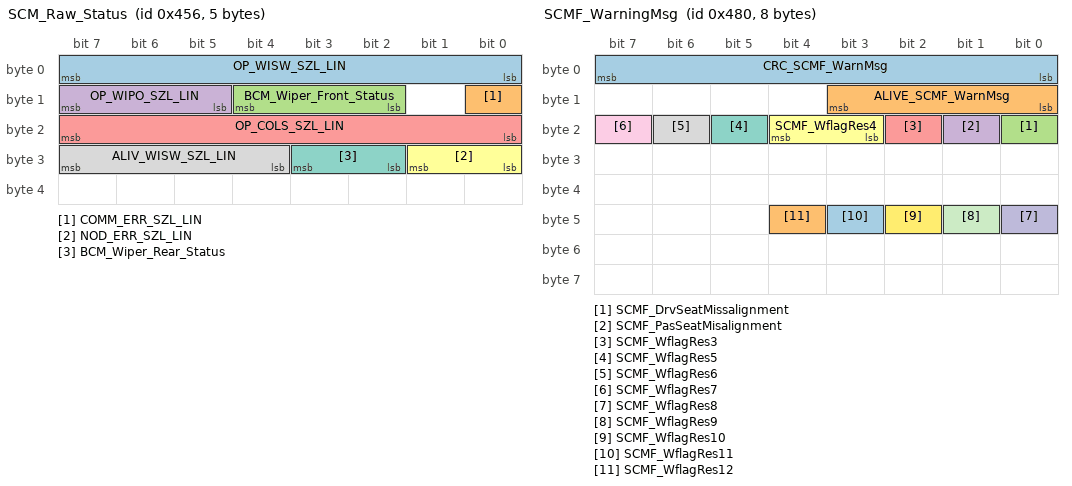
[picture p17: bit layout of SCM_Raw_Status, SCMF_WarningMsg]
BO_ 1110 SCM_Raw_Status: 5 CVC_I
 SG_ OP_WISW_SZL_LIN : 7|8@0+ (1,0) [0|255] ""  MHU
 SG_ COMM_ERR_SZL_LIN : 8|1@0+ (1,0) [0|1] ""  MHU
 SG_ BCM_Wiper_Front_Status : 12|3@0+ (1,0) [0|7] ""  MHU
 SG_ OP_WIPO_SZL_LIN : 15|3@0+ (1,0) [0|7] ""  MHU
 SG_ OP_COLS_SZL_LIN : 23|8@0+ (1,0) [0|255] ""  MHU
 SG_ NOD_ERR_SZL_LIN : 25|2@0+ (1,0) [0|3] ""  MHU
 SG_ BCM_Wiper_Rear_Status : 27|2@0+ (1,0) [0|3] ""  MHU
 SG_ ALIV_WISW_SZL_LIN : 31|4@0+ (1,0) [0|15] ""  MHU

BO_ 1152 SCMF_WarningMsg: 8 CVC_I
 SG_ CRC_SCMF_WarnMsg : 7|8@0+ (1,0) [0|255] ""  MHU
 SG_ ALIVE_SCMF_WarnMsg : 11|4@0+ (1,0) [0|15] ""  MHU
 SG_ SCMF_DrvSeatMissalignment : 16|1@0+ (1,0) [0|1] ""  MHU
 SG_ SCMF_PasSeatMisalignment : 17|1@0+ (1,0) [0|1] ""  MHU
 SG_ SCMF_WflagRes3 : 18|1@0+ (1,0) [0|1] ""  MHU
 SG_ SCMF_WflagRes4 : 20|2@0+ (1,0) [0|3] ""  MHU
 SG_ SCMF_WflagRes5 : 21|1@0+ (1,0) [0|1] ""  MHU
 SG_ SCMF_WflagRes6 : 22|1@0+ (1,0) [0|1] ""  MHU
 SG_ SCMF_WflagRes7 : 23|1@0+ (1,0) [0|1] ""  MHU
 SG_ SCMF_WflagRes8 : 40|1@0+ (1,0) [0|1] ""  MHU
 SG_ SCMF_WflagRes9 : 41|1@0+ (1,0) [0|1] ""  MHU
 SG_ SCMF_WflagRes10 : 42|1@0+ (1,0) [0|1] ""  MHU
 SG_ SCMF_WflagRes11 : 43|1@0+ (1,0) [0|1] ""  MHU
 SG_ SCMF_WflagRes12 : 44|1@0+ (1,0) [0|1] ""  MHU

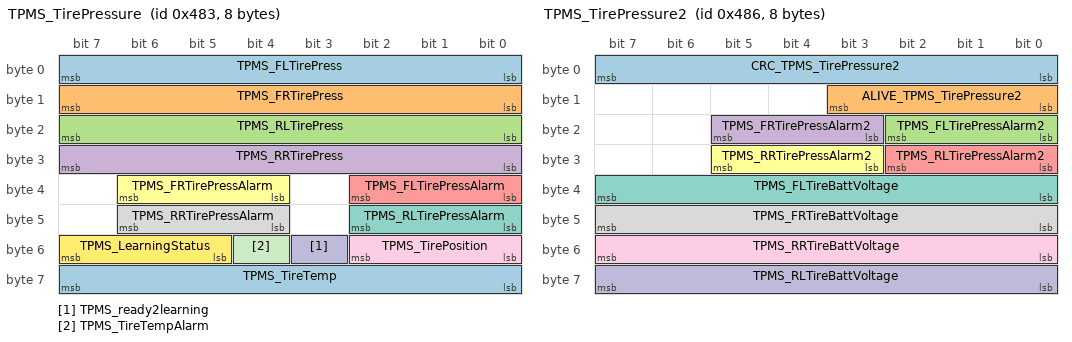
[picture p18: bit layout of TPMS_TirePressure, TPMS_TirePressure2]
BO_ 1155 TPMS_TirePressure: 8 CVC_I
 SG_ TPMS_FLTirePress : 7|8@0+ (1.373,0) [0|350] "kPa"  MHU
 SG_ TPMS_FRTirePress : 15|8@0+ (1.373,0) [0|350] "kPa"  MHU
 SG_ TPMS_RLTirePress : 23|8@0+ (1.373,0) [0|350] "kPa"  MHU
 SG_ TPMS_RRTirePress : 31|8@0+ (1.373,0) [0|350] "kPa"  MHU
 SG_ TPMS_FLTirePressAlarm : 34|3@0+ (1,0) [0|7] ""  MHU
 SG_ TPMS_FRTirePressAlarm : 38|3@0+ (1,0) [0|7] ""  MHU
 SG_ TPMS_RLTirePressAlarm : 42|3@0+ (1,0) [0|7] ""  MHU
 SG_ TPMS_RRTirePressAlarm : 46|3@0+ (1,0) [0|7] ""  MHU
 SG_ TPMS_TirePosition : 50|3@0+ (1,0) [0|7] ""  MHU
 SG_ TPMS_ready2learning : 51|1@0+ (1,0) [0|1] ""  MHU
 SG_ TPMS_TireTempAlarm : 52|1@0+ (1,0) [0|1] ""  MHU
 SG_ TPMS_LearningStatus : 55|3@0+ (1,0) [0|7] ""  MHU
 SG_ TPMS_TireTemp : 63|8@0+ (1,-40) [-40|215] "Degree C"  MHU

BO_ 1157 TBox_RemVehCtrlAssist_SecOC3: 8 CVC_I
 SG_ TBOX_RPADirSel : 15|4@0+ (1,0) [0|15] ""  TBOX

BO_ 1158 TPMS_TirePressure2: 8 CVC_I
 SG_ CRC_TPMS_TirePressure2 : 7|8@0+ (1,0) [0|255] ""  MHU,FCAM_I,ADCU_I
 SG_ ALIVE_TPMS_TirePressure2 : 11|4@0+ (1,0) [0|15] ""  MHU,FCAM_I,ADCU_I
 SG_ TPMS_FLTirePressAlarm2 : 18|3@0+ (1,0) [0|7] ""  MHU,FCAM_I,ADCU_I
 SG_ TPMS_FRTirePressAlarm2 : 21|3@0+ (1,0) [0|7] ""  MHU,FCAM_I,ADCU_I
 SG_ TPMS_RLTirePressAlarm2 : 26|3@0+ (1,0) [0|7] ""  MHU,FCAM_I,ADCU_I
 SG_ TPMS_RRTirePressAlarm2 : 29|3@0+ (1,0) [0|7] ""  MHU,FCAM_I,ADCU_I
 SG_ TPMS_FLTireBattVoltage : 39|8@0+ (0.1,0) [0|12] "V"  MHU,FCAM_I,ADCU_I
 SG_ TPMS_FRTireBattVoltage : 47|8@0+ (0.1,0) [0|12] "V"  MHU,FCAM_I,ADCU_I
 SG_ TPMS_RRTireBattVoltage : 55|8@0+ (0.1,0) [0|12] "V"  MHU,FCAM_I,ADCU_I
 SG_ TPMS_RLTireBattVoltage : 63|8@0+ (0.1,0) [0|12] "V"  MHU,FCAM_I,ADCU_I

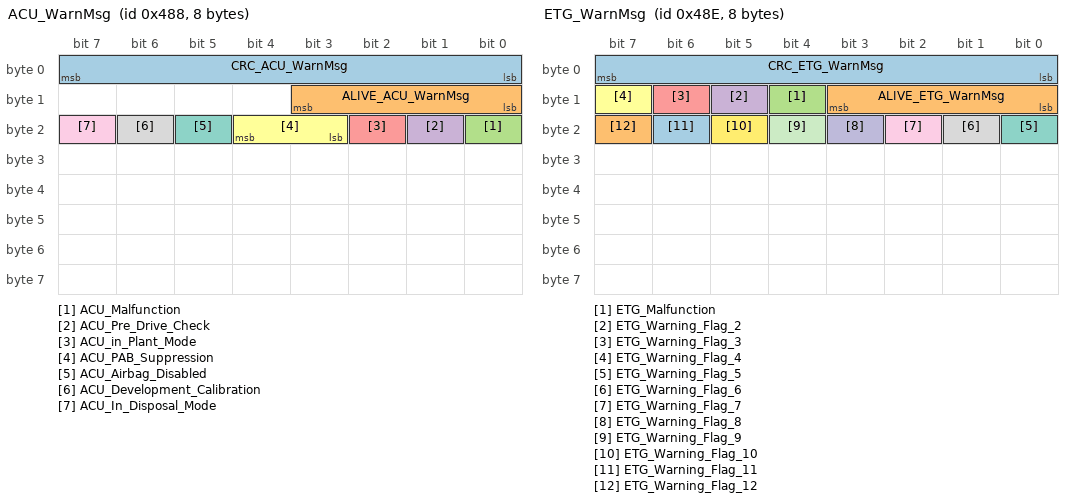
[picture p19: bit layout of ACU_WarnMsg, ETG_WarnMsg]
BO_ 1160 ACU_WarnMsg: 8 CVC_I
 SG_ CRC_ACU_WarnMsg : 7|8@0+ (1,0) [0|255] ""  MHU,FCAM_I,ADCU_I
 SG_ ALIVE_ACU_WarnMsg : 11|4@0+ (1,0) [0|15] ""  MHU,FCAM_I,ADCU_I
 SG_ ACU_Malfunction : 16|1@0+ (1,0) [0|1] ""  MHU,FCAM_I,ADCU_I
 SG_ ACU_Pre_Drive_Check : 17|1@0+ (1,0) [0|1] ""  MHU,FCAM_I,ADCU_I
 SG_ ACU_in_Plant_Mode : 18|1@0+ (1,0) [0|1] ""  MHU,FCAM_I,ADCU_I
 SG_ ACU_PAB_Suppression : 20|2@0+ (1,0) [0|3] ""  MHU,FCAM_I,ADCU_I
 SG_ ACU_Airbag_Disabled : 21|1@0+ (1,0) [0|1] ""  MHU,FCAM_I,ADCU_I
 SG_ ACU_Development_Calibration : 22|1@0+ (1,0) [0|1] ""  MHU,FCAM_I,ADCU_I
 SG_ ACU_In_Disposal_Mode : 23|1@0+ (1,0) [0|1] ""  MHU,FCAM_I,ADCU_I

BO_ 1166 ETG_WarnMsg: 8 CVC_I
 SG_ CRC_ETG_WarnMsg : 7|8@0+ (1,0) [0|255] ""  MHU
 SG_ ALIVE_ETG_WarnMsg : 11|4@0+ (1,0) [0|15] ""  MHU
 SG_ ETG_Malfunction : 12|1@0+ (1,0) [0|1] ""  MHU
 SG_ ETG_Warning_Flag_2 : 13|1@0+ (1,0) [0|1] ""  MHU
 SG_ ETG_Warning_Flag_3 : 14|1@0+ (1,0) [0|1] ""  MHU
 SG_ ETG_Warning_Flag_4 : 15|1@0+ (1,0) [0|1] ""  MHU
 SG_ ETG_Warning_Flag_5 : 16|1@0+ (1,0) [0|1] ""  MHU
 SG_ ETG_Warning_Flag_6 : 17|1@0+ (1,0) [0|1] ""  MHU
 SG_ ETG_Warning_Flag_7 : 18|1@0+ (1,0) [0|1] ""  MHU
 SG_ ETG_Warning_Flag_8 : 19|1@0+ (1,0) [0|1] ""  MHU
 SG_ ETG_Warning_Flag_9 : 20|1@0+ (1,0) [0|1] ""  MHU
 SG_ ETG_Warning_Flag_10 : 21|1@0+ (1,0) [0|1] ""  MHU
 SG_ ETG_Warning_Flag_11 : 22|1@0+ (1,0) [0|1] ""  MHU
 SG_ ETG_Warning_Flag_12 : 23|1@0+ (1,0) [0|1] ""  MHU

BO_ 1171 BMS_WarnMsg: 8 CVC_I
 SG_ CRC_BMS_WarnMsg : 7|8@0+ (1,0) [0|255] ""  MHU
 SG_ ALIVE_BMS_WarnMsg : 11|4@0+ (1,0) [0|15] ""  MHU
 SG_ BMS_PackTempSts : 13|2@0+ (1,0) [0|3] ""  MHU
 SG_ BMS_ThermalRunaway : 14|1@0+ (1,0) [0|1] ""  MHU
 SG_ BMS_BatteryReplacement : 15|1@0+ (1,0) [0|1] ""  MHU
 SG_ BMS_Warning_PowerDegrade : 16|1@0+ (1,0) [0|1] ""  MHU
 SG_ BMS_Warning_DeltaSoC : 17|1@0+ (1,0) [0|1] ""  MHU
 SG_ BMS_Warning_HVILSts : 18|1@0+ (1,0) [0|1] ""  MHU
 SG_ BMS_Warning_Isolation : 19|1@0+ (1,0) [0|1] ""  MHU
 SG_ BMS_Warning_CoolantLeakage : 20|1@0+ (1,0) [0|1] ""  MHU
 SG_ BMS_MalfunctionSts : 21|1@0+ (1,0) [0|1] ""  MHU
 SG_ BMS_LowBattery : 23|2@0+ (1,0) [0|3] ""  MHU
 SG_ BMS_Warning_DeltaTemperature : 31|8@0+ (1,0) [0|255] ""  MHU
 SG_ BMS_Warning_BDUTemperatureSts : 39|8@0+ (1,0) [0|255] ""  MHU
 SG_ BMS_Warning_Contactor_Aging : 47|1@0+ (1,0) [0|1] ""  MHU
 SG_ BMS_Reserved_signal4 : 55|8@0+ (1,0) [0|255] ""  MHU
 SG_ BMS_Reserved_signal5 : 63|8@0+ (1,0) [0|255] ""  MHU

CM_ SG_ 854 CVC_ADAS_HWA_SOTA "HWA / TJA - Highway Driving Assist  / Traffic Jam Assist Customer SOTA Disable or Enable";
CM_ SG_ 854 CVC_ADAS_AESA_SOTA "AESA - Automatic Emergency Stop Assist  (L2) Customer SOTA Disable or Enable";
CM_ SG_ 854 CVC_ADAS_ALCA_SOTA "ALCA - Auto Lane Changing Assist   (L2) Customer SOTA Disable or Enable";
CM_ SG_ 854 CVC_ADAS_BasicCruise_SOTA "Basic Cruise Control & Speed limiter (L0)Customer SOTA Disable or Enable";
CM_ SG_ 854 CVC_ADAS_ACC_SOTA "ACC - Adaptive Cruise Control  (L1) Customer SOTA Disable or Enable";
CM_ SG_ 854 CVC_ADAS_TSR_SOTA "TSR - Traffic Sign Recognition  (L0) Customer SOTA Disable or Enable";
CM_ SG_ 854 CVC_ADAS_ISA_SOTA "ISA - Intelligent Speed Adjustment (L1) Customer SOTA Disable or Enable";
CM_ SG_ 854 CVC_ADAS_NOP_SOTA "NOP - Navigation on Pilot (Highway) (L2+) Customer SOTA Disable or Enable";
CM_ SG_ 854 CVC_ADAS_AAESA_SOTA "AAESA - Advaced Automatic Emergency Stop Assist  (L2+)  Customer SOTA Disable or Enable";
CM_ SG_ 854 CVC_ADAS_ALCM_SOTA "ALCM - Advanced Lane Change Maneuver  (L2+) Customer SOTA Disable or EnableALCM - Advanced Lane Change Maneuver  (L2+) Customer SOTA Disable or Enable";
CM_ SG_ 854 CVC_ADAS_AACC_SOTA "AACC - Advaced Adaptive Cruise Control  (L1) Customer SOTA Disable or Enable";
CM_ SG_ 854 CVC_ADAS_TLD_SOTA "TLD - Traffic Light Detection (L0) Customer SOTA Disable or Enable";
CM_ SG_ 854 CVC_ADAS_DNS_SOTA "DNS - Departure Notification System (L0) Customer SOTA Disable or Enable";
CM_ SG_ 854 CVC_ADAS_LDW_SOTA "LDW - Lane Departure Warning  (L0) Customer SOTA Disable or Enable";
CM_ SG_ 854 CVC_ADAS_LKA_SOTA "LKA - Lane Keep Assist  (L0)Customer SOTA Disable or Enable";
CM_ SG_ 854 CVC_ADAS_ELK_SOTA "ELK - Emergency Lane Keep Assist (L1) Customer SOTA Disable or Enable";
CM_ SG_ 854 CVC_ADAS_FAEB_SOTA "FAEB - Front Automatic Emergency Brake  (L0) Customer SOTA Disable or Enable";
CM_ SG_ 854 CVC_ADAS_ESA_SOTA "ESA - Evasive Steering Assist  (L0) Customer SOTA Disable or Enable";
CM_ SG_ 854 CVC_ADAS_RAEB_SOTA "RAEB - Rear Automatic Emergency Brake  (L0) Customer SOTA Disable or Enable";
CM_ SG_ 854 CVC_ADAS_FCW_SOTA "FCW - Forward Collision Warning (L0) Customer SOTA Disable or Enable";
CM_ SG_ 854 CVC_ADAS_RCTA_SOTA "RCTA - Rear Cross-Traffic Alert  (L0) Customer SOTA Disable or Enable";
CM_ SG_ 854 CVC_ADAS_BSD_SOTA "BSD - Blind Spot Detection  (L0) Customer SOTA Disable or Enable";
CM_ SG_ 854 CVC_ADAS_DOW_SOTA "DOW - Door Open Warning  (L0) Customer SOTA Disable or Enable";
CM_ SG_ 854 CVC_ADAS_IA_SOTA "IA - Intersection assist  Customer SOTA Disable or Enable";
CM_ SG_ 854 CVC_ADAS_SVM_SOTA "SVM - Surround View Monitoring (L0)  Customer SOTA Disable or Enable";
CM_ SG_ 854 CVC_ADAS_RVC_SOTA "RVC - Rear View Camera (L0) Customer SOTA Disable or Enable";
CM_ SG_ 854 CVC_ADAS_FPA_SOTA "FPA - Front Parking Assist (L0) Customer SOTA Disable or Enable";
CM_ SG_ 854 CVC_ADAS_RPA_SOTA "RPA - Rear Parking Assist  (L0) Customer SOTA Disable or Enable";
CM_ SG_ 854 CVC_ADAS_SpaFAPA_SOTA "SPA / FAPA - Smart Parking Assist  / Fully Automated Parking Assist (L2)  Customer SOTA Disable or Enable";
CM_ SG_ 854 CVC_ADAS_RP_SOTA "RP - Remote Parking Assist  (L2)  Customer SOTA Disable or Enable";
CM_ SG_ 854 CVC_ADAS_VParkingSelect_SOTA "V-Parking Select (L2+)  Customer SOTA Disable or Enable";
CM_ SG_ 854 CVC_ADAS_VParkingComfort_SOTA "V-Parking Comfort (L2++)  Customer SOTA Disable or Enable";
CM_ SG_ 854 CVC_ADAS_VParkingSummon_SOTA "V-Parking Comfort (L2++)  Customer SOTA Disable or Enable";
CM_ SG_ 854 CVC_ADAS_VParkingAutoRev_SOTA "V-Parking Auto Reverse (L2++) Customer SOTA Disable or EnableV-Parking Auto Reverse (L2++) Customer SOTA Disable or Enable";
CM_ SG_ 854 CVC_ADAS_AHB_SOTA "AHB - Automatic High Beam  (L0 ) Customer SOTA Disable or Enable";
CM_ SG_ 854 CVC_ADAS_ADB_SOTA "ADB - Adaptive Driving Beam (L0) Customer SOTA Disable or Enable";
CM_ SG_ 854 CVC_ADAS_DMS_SOTA "DMS  - Driver Monitoring System (DDAW / ADDW) Customer SOTA Disable or Enable";
CM_ SG_ 854 CVC_ADAS_DMSFaceID_SOTA "Using DMS camera as FaceID, health tracking,, Customer SOTA Disable or Enable";
CM_ SG_ 854 CVC_ADAS_DCM_SOTA "DCM - Dash Cam Mode Recoder Customer SOTA Disable or Enable";
CM_ SG_ 854 CVC_ADAS_AdasEDR_SOTA "ADAS Event Data Recoder Customer SOTA Disable or Enable";
CM_ SG_ 854 CVC_ADAS_ACPE_SOTA "Acceleration control for Pedal Error (ACPE) Customer SOTA Disable or Enable";
CM_ SG_ 854 CVC_ADAS_SentryMode_SOTA "Sentry Mode Customer SOTA Disable or Enable";
CM_ SG_ 862 CRC_CVC_Vehicle_info "Checksum";
CM_ SG_ 862 ALIVE_CVC_Vehicle_info "Alive counter";
CM_ SG_ 862 CVC_VehLock_STS "Vehicle Lock Status";
CM_ SG_ 862 CVC_VehSpd_ScreenDisplay "Indicate the display speed on HMI screen calculated according to Vehicle actual speed.";
CM_ SG_ 862 CVC_VehChgAllow "Indicate the request to allow the vehicle to start charging";
CM_ SG_ 862 CVC_VehDischgAllow "Indicate the request to allow the vehicle to start discharging";
CM_ SG_ 862 Re_InitCharging_Req "Request re-initiate charging";
CM_ SG_ 862 CVC_StopChg_Req "Stop charging request";
CM_ SG_ 862 CVC_GunUnlock_Req "Unlock charging gun request";
CM_ SG_ 862 CVC_Ack_LimitSetting_SOC "Indicate the acknowledge setting value for the limit of the HV state-of-charge.";
CM_ SG_ 862 CVC_ACInputChgCurLim "Indicate the setting value for the limit of the AC input charge current.";
CM_ SG_ 862 CVC_HV_DispSOC "Indicate the state-of-charge of the HV battery rounded by CVC to display to user";
CM_ SG_ 862 CVC_HV_Cur_LoadComp "Indicate the necessary current estimated by CVC to compensate HV load during charging.";
CM_ SG_ 863 CRC_CVC_SchdlChg_Info "Checksum";
CM_ SG_ 863 ALIVE_CVC_SchdlChg_Info "Alive counter";
CM_ SG_ 863 Ack_SchdlChg "Indicate the acknowledge setting value for schedule charging function";
CM_ SG_ 866 WCBS_RBC_STS "Regen Brake Control Status";
CM_ SG_ 866 WCBS_RegenMonFail "Regenerative braking monitoring fault";
CM_ SG_ 866 WCBS_TorqReqMode "Indicate the torque request mode";
CM_ SG_ 866 WCBS_F_RegenTarTrq "Front axle target energy recovery torque (wheel end torque)";
CM_ SG_ 866 WCBS_R_RegenTarTrq "Rear axle target energy recovery torque (wheel end torque)";
CM_ SG_ 866 WCBS_F_RegenTarTrqValid "Effective position of front axle target energy recovery torque";
CM_ SG_ 866 WCBS_R_RegenTarTrqValid "Effective position of rear axle target energy recovery torque";
CM_ SG_ 866 WCBS_F_FrictionTarTrq "Friction brake calculated during Regen - Front";
CM_ SG_ 866 WCBS_R_FrictionTarTrq "Friction brake calculated during Regen - Rear";
CM_ SG_ 872 FMCU_PhaseOverCurrentSWFault "Front Phase Current Overcurrent software fault";
CM_ SG_ 872 FMCU_MCUOverTempFault "FMCU over temperture fault";
CM_ SG_ 872 FMCU_MCUOverTempAlarm "FMCU over temperture alarm";
CM_ SG_ 872 FMCU_MotOverTemp2Fault "Front Motor temperature sensorU fault";
CM_ SG_ 872 FMCU_MotTempSenFault "Front Motor temperature sensor fault";
CM_ SG_ 872 FMCU_MotOverTemp1Fault "Front Motor over temperture fault";
CM_ SG_ 872 FMCU_MotOverTempAlarm "Front Motor over temperture alarm";
CM_ SG_ 872 FMCU_MCUHVUnderVoltageFault "FMCU high voltage under voltage fault";
CM_ SG_ 872 FMCU_MCUHVUnderVoltageAlarm "FMCU high voltage under voltage alarm";
CM_ SG_ 872 FMCU_MCUHVOverVoltageFault "FMCU high voltage over voltage fault";
CM_ SG_ 872 FMCU_MCUHVOverVoltageAlarm "FMCU high voltage over voltage alarm";
CM_ SG_ 872 FMCU_MCUCurrentSenWFault "FMCU current sensorW fault";
CM_ SG_ 872 FMCU_MCUCurrentSenVFault "FMCU current sensorV fault";
CM_ SG_ 872 FMCU_MCUCurrentSenUFault "FMCU current sensorU fault";
CM_ SG_ 872 FMCU_PhaseOverCurrentHWFault "Phase Current Overcurrent hardware fault";
CM_ SG_ 872 FMCU_MotOverFault "Motor overspeed fault fault";
CM_ SG_ 872 FMCU_MotOverAlarm "Motor overspeed fault alarm";
CM_ SG_ 872 FMCU_12VUnderVoltageAlarm "12V Power under voltage alarm";
CM_ SG_ 872 FMCU_12VOverVoltageAlarm "12V Power over voltage alarm";
CM_ SG_ 872 FMCU_MCUHVSensorFault "FMCU high voltage sensor fault";
CM_ SG_ 872 FMCU_MCUDisChgFault "FMCU Active discharge fault";
CM_ SG_ 872 FMCU_MotBlockedFault "Motor blocked fault";
CM_ SG_ 872 FMCU_MotRotSenFault "Motor resolver fault";
CM_ SG_ 872 FMCU_BMSLostFault "BMS lost communication fault";
CM_ SG_ 872 FMCU_CVCLostFault "CVC lost communication fault";
CM_ SG_ 872 FMCU_CANBusoffFault "CAN busoff fault";
CM_ SG_ 872 FMCU_IGBTFault "IGBT fault";
CM_ SG_ 872 FMCU_MCUCurrentSenWZeroFault "FMCU current sensorW Zero fault";
CM_ SG_ 872 FMCU_MCUCurrentSenVZeroFault "FMCU current sensorV Zero fault";
CM_ SG_ 872 FMCU_MCUCurrentSenUZeroFault "FMCU current sensorU Zero fault";
CM_ SG_ 872 FMCU_MCUTempSenWFault "FMCU temperature sensorW fault";
CM_ SG_ 872 FMCU_MCUTempSenVFault "FMCU temperature sensorV fault";
CM_ SG_ 872 FMCU_MCUTempSenUFault "FMCU temperature sensorU fault";
CM_ SG_ 872 FMCU_InitMode "Initial mode";
CM_ SG_ 872 FMCU_MCUFaultCode "FMCU Fault Code";
CM_ SG_ 874 RMCU_PhaseOverCurrentSWFault "Rear Phase Current Overcurrent software fault";
CM_ SG_ 874 RMCU_MCUOverTempFault "RMCU over temperture fault";
CM_ SG_ 874 RMCU_MCUOverTempAlarm "RMCU over temperture alarm";
CM_ SG_ 874 RMCU_MotOverTemp2Fault "Rear Motor temperature sensorU fault";
CM_ SG_ 874 RMCU_MotTempSenFault "Rear Motor temperature sensor fault";
CM_ SG_ 874 RMCU_MotOverTemp1Fault "Rear Motor over temperture fault";
CM_ SG_ 874 RMCU_MotOverTempAlarm "Rear Motor over temperture alarm";
CM_ SG_ 874 RMCU_MCUHVUnderVoltageFault "RMCU high voltage under voltage fault";
CM_ SG_ 874 RMCU_MCUHVUnderVoltageAlarm "RMCU high voltage under voltage alarm";
CM_ SG_ 874 RMCU_MCUHVOverVoltageFault "RMCU high voltage over voltage fault";
CM_ SG_ 874 RMCU_MCUHVOverVoltageAlarm "RMCU high voltage over voltage alarm";
CM_ SG_ 874 RMCU_MCUCurrentSenWFault "RMCU current sensorW fault";
CM_ SG_ 874 RMCU_MCUCurrentSenVFault "RMCU current sensorV fault";
CM_ SG_ 874 RMCU_MCUCurrentSenUFault "RMCU current sensorU fault";
CM_ SG_ 874 RMCU_PhaseOverCurrentHWFault "Phase Current Overcurrent hardware fault";
CM_ SG_ 874 RMCU_MotOverFault "Motor overspeed fault fault";
CM_ SG_ 874 RMCU_MotOverAlarm "Motor overspeed fault alarm";
CM_ SG_ 874 RMCU_12VUnderVoltageAlarm "12V Power under voltage alarm";
CM_ SG_ 874 RMCU_12VOverVoltageAlarm "12V Power over voltage alarm";
CM_ SG_ 874 RMCU_MCUHVSensorFault "RMCU high voltage sensor fault";
CM_ SG_ 874 RMCU_MCUDisChgFault "RMCU Active discharge fault";
CM_ SG_ 874 RMCU_MotBlockedFault "Motor blocked fault";
CM_ SG_ 874 RMCU_MotRotSenFault "Motor resolver fault";
CM_ SG_ 874 RMCU_BMSLostFault "BMS lost communication fault";
CM_ SG_ 874 RMCU_CVCLostFault "CVC lost communication fault";
CM_ SG_ 874 RMCU_CANBusoffFault "CAN busoff fault";
CM_ SG_ 874 RMCU_IGBTFault "IGBT fault";
CM_ SG_ 874 RMCU_MCUCurrentSenWZeroFault "RMCU current sensorW Zero fault";
CM_ SG_ 874 RMCU_MCUCurrentSenVZeroFault "RMCU current sensorV Zero fault";
CM_ SG_ 874 RMCU_MCUCurrentSenUZeroFault "RMCU current sensorU Zero fault";
CM_ SG_ 874 RMCU_MCUTempSenWFault "RMCU temperature sensorW fault";
CM_ SG_ 874 RMCU_MCUTempSenVFault "RMCU temperature sensorV fault";
CM_ SG_ 874 RMCU_MCUTempSenUFault "RMCU temperature sensorU fault";
CM_ SG_ 874 RMCU_InitMode "Initial mode";
CM_ SG_ 874 RMCU_MCUFaultCode "RMCU Fault Code";
CM_ SG_ 880 MNF_ErrSt "Mini fridge fault status";
CM_ SG_ 880 MNF_OverTempWarning "Mini fridge ambient temperature overheat alarm";
CM_ SG_ 880 MNF_DoorOpenWarning1 "Mini fridge door open timeout reminder";
CM_ SG_ 880 MNF_DoorOpenWarning2 "Mini fridge door open reminder when leaving the vehicle";
CM_ SG_ 880 MNF_WorkTimeRes "Mini fridge off-vehicle continuous working duration feedback";
CM_ SG_ 880 MNF_SpecialModeSts "Mini fridge special mode status";
CM_ SG_ 880 MNF_AutoStartRes "Mini fridge auto-on setting feedback when boarding the vehicle";
CM_ SG_ 880 MNF_TempSetRes "Mini fridge temperature setting feedback";
CM_ SG_ 880 MNF_WorkSts "Mini fridge working status";
CM_ SG_ 880 MNF_LockRes "Mini fridge child lock status";
CM_ SG_ 880 MNF_Door_Lock_Sts "Mini fridge door status";
CM_ SG_ 880 MNF_AutoCloseRes "Mini fridge auto-shutdown reason";
CM_ SG_ 880 MNF_AMB_T "Mini fridge ambient temperature";
CM_ SG_ 880 MNF_DoorLockTime "Mini fridge door thermal protection remaining time";
CM_ SG_ 880 MNF_WorkRemainTime "Mini fridge off-vehicle working remaining time";
CM_ SG_ 881 MNF_INT_T "Mini fridge internal temperature";
CM_ SG_ 881 MNF_ErrInfo "Mini fridge fault information";
CM_ SG_ 881 MNF_HVReq "Mini fridge high-voltage operation request";
CM_ SG_ 884 CRC_USS_RPA_Distance "Checksum";
CM_ SG_ 884 ALIVE_USS_RPA_Distance "Alive counter";
CM_ SG_ 884 USS_RPA_DistRLI "This signal indicates the distance of obstacle";
CM_ SG_ 884 USS_RPA_DistRLO "This signal indicates the distance of obstacle";
CM_ SG_ 884 USS_RPA_DistRRI "This signal indicates the distance of obstacle";
CM_ SG_ 884 USS_RPA_DistRRO "This signal indicates the distance of obstacle";
CM_ SG_ 886 CRC_USS_RPA_Status "Checksum";
CM_ SG_ 886 ALIVE_USS_RPA_Status "Alive Counter";
CM_ SG_ 886 USS_RPA_state "This signal indicates the status of Rear Parking System state";
CM_ SG_ 886 USS_RPA_AlertRLI "This signal indicates the warning level of Rear Left Inner USS";
CM_ SG_ 886 USS_RPA_AlertRLO "This signal indicates the warning level of Rear Left Outer USS";
CM_ SG_ 886 USS_RPA_AlertRRI "This signal indicates the warning level of Rear Right Inner USS";
CM_ SG_ 886 USS_RPA_AlertRRO "This signal indicates the warning level of Rear Right Outer USS";
CM_ SG_ 886 USS_RPA_SensorRLI "This signal indicates the status of Rear Left Inner USS sensor";
CM_ SG_ 886 USS_RPA_SensorRLO "This signal indicates the status of Rear Left Outer USS sensor";
CM_ SG_ 886 USS_RPA_SensorRRI "This signal indicates the status of Rear Right Inner USS sensor";
CM_ SG_ 886 USS_RPA_SensorRRO "This signal indicates the status of Rear Right Outer USS sensor";
CM_ SG_ 887 CRC_USS_FPA_Status "Checksum";
CM_ SG_ 887 ALIVE_USS_FPA_Status "Alive Counter";
CM_ SG_ 887 USS_FPA_state "This signal indicates the status of Front Parking System state";
CM_ SG_ 887 USS_FPA_AutoOn_Feed "This signal indicates the status of Auto Front Parking Assist";
CM_ SG_ 887 USS_FPA_AlertFLI "This signal indicates the warning level of Front Left Inner USS";
CM_ SG_ 887 USS_FPA_AlertFLO "This signal indicates the warning level of Front Left Outer USS";
CM_ SG_ 887 USS_FPA_AlertFRI "This signal indicates the warning level of Front Right Inner USS";
CM_ SG_ 887 USS_FPA_AlertFRO "This signal indicates the warning level of Front Right Outer USS";
CM_ SG_ 887 USS_FPA_SensorFLI "This signal indicates the status of Front Left Inner USS sensor";
CM_ SG_ 887 USS_FPA_SensorFLO "This signal indicates the status of Front Left Outer USS sensor";
CM_ SG_ 887 USS_FPA_SensorFRI "This signal indicates the status of Front Right Inner USS sensor";
CM_ SG_ 887 USS_FPA_SensorFRO "This signal indicates the status of Front Right Outer USS sensor";
CM_ SG_ 889 CRC_USS_FPA_Distance "Checksum";
CM_ SG_ 889 ALIVE_USS_FPA_Distance "Alive counter";
CM_ SG_ 889 USS_FPA_DistFLI "This signal indicates the distance of obstacle";
CM_ SG_ 889 USS_FPA_DistFLO "This signal indicates the distance of obstacle";
CM_ SG_ 889 USS_FPA_DistFRI "This signal indicates the distance of obstacle";
CM_ SG_ 889 USS_FPA_DistFRO "This signal indicates the distance of obstacle";
CM_ SG_ 892 CRC_EVCC_Charging_Sts "Checksum";
CM_ SG_ 892 ALIVE_EVCC_Charging_Sts "Alive counter";
CM_ SG_ 892 EVCC_ChgGun_Sts "Indicate the status of the charge gun: whether it is connected, removed, or if there is an error.";
CM_ SG_ 892 EVCC_ChgFlap_Sts "Indicate the status of the charge flap: whether it is opened, closed and locked or released.";
CM_ SG_ 892 EVCC_ChgType "Indicate the charging type for the charging session. The charging type is detected via the PWM value of the CP pin and the message pair ServiceDiscovery during PLC communication";
CM_ SG_ 892 EVCC_VehChg_Sts "Indicate the charging status.";
CM_ SG_ 892 EVCC_ChgAuthen_Sts "Indicate the authentication status of charging session, whether the vehicle and the EVSE is compatible or not.";
CM_ SG_ 892 EVCC_PaymentType "Description Indicate the payment type for the charging session.";
CM_ SG_ 892 EVCC_VehChgCompError_Sts "Indicate the error status of the charging components from the vehicle.";
CM_ SG_ 892 EVCC_ProximityPilot_Voltage "Indicate the measure voltage of Proximity pilot (PP) pin";
CM_ SG_ 892 EVCC_S3Button_Sts "S3 button state";
CM_ SG_ 896 VIN_Byte1 "This signal contains the seventh last digit of the chassis number. (The individual digits are encoded in ASCII characters.)";
CM_ SG_ 896 VIN_Byte2 "This signal contains the sixth last digit of the chassis number. (The individual digits are encoded in ASCII characters.)";
CM_ SG_ 896 VIN_Byte3 "This signal contains the fifth last digit of the chassis number. (The individual digits are encoded in ASCII characters.)";
CM_ SG_ 896 VIN_Byte4 "This signal contains the fourth last digit of the chassis number. (The individual digits are encoded in ASCII characters.)";
CM_ SG_ 896 VIN_Byte5 "This signal contains the third last digit of the chassis number. (The individual digits are encoded in ASCII characters.)";
CM_ SG_ 896 VIN_Byte6 "This signal contains the penultimate digit of the chassis number. (The individual digits are encoded in ASCII characters.)";
CM_ SG_ 896 VIN_Byte7 "This signal contains the last digit of the chassis number. (The individual digits are encoded in ASCII characters.)";
CM_ SG_ 897 CRC_ACU_OCCUPANT_STATUS "Checksum";
CM_ SG_ 897 ALIVE_ACU_OCCUPANT_STATUS "Alive Counter";
CM_ SG_ 897 ACU_Seat_Occupancy_Passenger "Passenger seat occupancy status";
CM_ SG_ 897 ACU_Seat_Occupancy_2nd_Row_Dri "The occupancy status of the driver's side seat in the second row";
CM_ SG_ 897 ACU_Seat_Occupancy_2nd_Row_Pas "The occupancy status of the second row passenger side seat";
CM_ SG_ 897 ACU_Seat_Occupancy_2nd_Row_Mid "The occupancy status of the middle seat in the second row";
CM_ SG_ 897 ACU_Seat_Belt_Status_Passenger "The status of passenger seat belts";
CM_ SG_ 897 ACU_Seat_Belt_Status_Driver "The status of the driver's seat belt";
CM_ SG_ 897 ACU_Seat_Belt_Status_2nd_Row_Dri "The status of the driver's side seat belt in the second row";
CM_ SG_ 897 ACU_Seat_Belt_Status_2nd_Row_Mid "The status of the second row middle seat belt";
CM_ SG_ 897 ACU_Seat_Belt_Status_2nd_Row_Pas "The status of the second row passenger side seat belt";
CM_ SG_ 897 ACU_Seat_Occupancy_Driver "Driver seat occupancy status";
CM_ SG_ 899 CVC_VIN_Byte1 "This signal contains the seventh last digit of the chassis number. (The individual digits are encoded in ASCII characters.)";
CM_ SG_ 899 CVC_VIN_Byte2 "This signal contains the sixth last digit of the chassis number. (The individual digits are encoded in ASCII characters.)";
CM_ SG_ 899 CVC_VIN_Byte3 "This signal contains the fifth last digit of the chassis number. (The individual digits are encoded in ASCII characters.)";
CM_ SG_ 899 CVC_VIN_Byte4 "This signal contains the fourth last digit of the chassis number. (The individual digits are encoded in ASCII characters.)";
CM_ SG_ 899 CVC_VIN_Byte5 "This signal contains the third last digit of the chassis number. (The individual digits are encoded in ASCII characters.)";
CM_ SG_ 899 CVC_VIN_Byte6 "This signal contains the penultimate digit of the chassis number. (The individual digits are encoded in ASCII characters.)";
CM_ SG_ 899 CVC_VIN_Byte7 "This signal contains the last digit of the chassis number. (The individual digits are encoded in ASCII characters.)";
CM_ SG_ 925 CRC_CVC_AHB_Sts "Checksum";
CM_ SG_ 925 ALIVE_CVC_AHB_Sts "Alive counter";
CM_ SG_ 925 CVC_ADAS_AHB_Sts "AHB state";
CM_ SG_ 925 CVC_AHB_Override "Automatic High Beam Override by Driver using Stalk lever";
CM_ SG_ 925 CVC_ADAS_AHB_RBPos_Sts "High Beam Position Request Signal staus(Right Ramp)";
CM_ SG_ 925 CVC_ADAS_AHB_LBPos_Sts "High Beam Position Request Signal staus(Left Ramp)";
CM_ SG_ 925 CVC_AHB_Icon_Sts "AHB ICON status";
CM_ SG_ 992 CRC_CVC_HVsystem_status "Checksum";
CM_ SG_ 992 ALIVE_CVC_HVsystem_status "Alive counter";
CM_ SG_ 992 CVC_RunningRange "Estimated running range ( at present )";
CM_ SG_ 992 CVC_RunningRange_chrg_estSts "Status of estimation running range after charged by current charging condition ( max chg.current, chg.time, ?)";
CM_ SG_ 992 CVC_RunningRange_charged "Estimated running range after charged by current charging condition ( max chg.current, chg.time, ?)";
CM_ SG_ 992 CVC_HVbatSoc_charged "Estimated HVBattery SOC by current charging condition ( max chg.current, chg.time, ?)";
CM_ SG_ 992 CVC_HVbatSoc_charged_estStatus "Status of SOC Estimation by current charging condition ( max chg.current, chg.time, ?)";
CM_ SG_ 993 CRC_CVC_HMI_Info "Checksum";
CM_ SG_ 993 ALIVE_CVC_HMI_Info "Alive counter";
CM_ SG_ 993 CVC_SetCruiseSpd "Set Cruise Speed";
CM_ SG_ 993 CVC_MHU_Ack_ChgSche_stt "Status Enabled/ Disabled of Schedule Charging acknowledged by CVC base on request from MHU 0x403 MHU_ChargeScheduleSet.";
CM_ SG_ 993 CVC_MHU_Ack_TargetSOC "Target SOC acknowledged by CVC base on request from MHU";
CM_ SG_ 993 CVC_ValetMode_sts "Status indicate valet mode is effected to CVC";
CM_ SG_ 993 CVC_ValetMode_MaxSpeedSts "Max speed setting of Valet mode";
CM_ SG_ 993 CVC_DashCam_Info "Car camera information";
CM_ SG_ 993 CVC_BEDrvInhibit "Driving inhibition status from Back-End";
CM_ SG_ 358 CRC_CVC_Status "CRC code to check the data integrity";
CM_ SG_ 358 ALIVE_CVC_Status "signal couting the times of this message";
CM_ SG_ 358 CVC_DriveModeSts "CVC_Drive Mode Status";
CM_ SG_ 358 CVC_DriveReady "Drive ready indicator";
CM_ SG_ 358 CVC_Fault "Vehicle Fault Level";
CM_ SG_ 358 CVC_VecFltInd "Vehicle Fault Indication";
CM_ SG_ 358 CVC_Creep_Sts "Creep Status";
CM_ SG_ 358 CVC_CruiseCtrlSts "cruise control Status";
CM_ SG_ 358 CVC_StsBrakePedalSwitch "Brake pedal Switch status";
CM_ SG_ 358 CVC_VehicleMode "Vehiclemodestatus";
CM_ SG_ 358 CVC_CruiseSetSpd "Cruise set speed";
CM_ SG_ 358 CVC_CruiseFaultIndication "CVC_Cruise Fault";
CM_ SG_ 358 CVC_FuelDetectionSwitchState "Fuel detection switch status feedback";
CM_ SG_ 358 CVC_FuelDetectionState "Fuel detection mode";
CM_ SG_ 358 CVC_ParkingChargeRequest "Parking charging switch";
CM_ SG_ 358 CVC_ParkingChargeModeSet "Parking charging mode setting";
CM_ SG_ 994 WCBS_LateralACC_Valid "Valid flag of lateral acceleration";
CM_ SG_ 994 WCBS_LongitudeACC_Valid "Valid flag of longitude acceleration";
CM_ SG_ 994 WCBS_VehDynYawRate_Valid "Valid flag of yaw rate";
CM_ SG_ 994 WCBS_LateralACC "Indicate lateral acceleration";
CM_ SG_ 994 WCBS_LongitudeACC "Indicate longitude acceleration";
CM_ SG_ 994 WCBS_VehDynYawRate "Indicate the yaw rate";
CM_ SG_ 994 WCBS_LateralACCRaw "Raw Lateral Acceleration from sensor";
CM_ SG_ 994 WCBS_LongitudeACCRaw "Raw Longitude Acceleration from sensor";
CM_ SG_ 994 WCBS_VehDynYawRateRaw "Raw yaw rate from sensor";
CM_ SG_ 994 WCBS_ESCTarYawRate "ESC target yaw rate";
CM_ SG_ 996 IMU_VerticalACC_Valid "Valid flag of Vertical acceleration";
CM_ SG_ 996 IMU_VehDynPitchRate_Valid "Valid flag of Pitch Rate";
CM_ SG_ 996 IMU_VehDynRollRate_Valid "Valid flag of Roll Rate";
CM_ SG_ 996 IMU_VerticalACC "Filtered vertical acceleration";
CM_ SG_ 996 IMU_VehDynPitchRate "Filtered pitch rate";
CM_ SG_ 996 IMU_VehDynRollRate "Filtered roll rate";
CM_ SG_ 997 IMU_VerticalACCRaw_Valid "Valid flag of Vertical acceleration raw";
CM_ SG_ 997 IMU_VehDynPitchRateRaw_Valid "Valid flag of Pitch Rate raw";
CM_ SG_ 997 IMU_VehDynRollRateRaw_Valid "Valid flag of Roll Rate raw";
CM_ SG_ 997 IMU_VerticalACCRaw "Raw Vertical acceleration from sensor";
CM_ SG_ 997 IMU_VehDynPitchRateRaw "Raw Pitch Rate from sensor";
CM_ SG_ 997 IMU_VehDynRollRateRaw "Raw Roll Rate from sensor";
CM_ SG_ 1004 CVC_PanicEventTrigger "Emergency event trigger signal";
CM_ SG_ 1004 CVC_PanicEventSource "Emergency event trigger source";
CM_ SG_ 1004 CVC_PanicEventStatus "Emergency status";
CM_ SG_ 1004 CVC_PanicEventCounter "Emergency event counter";
CM_ SG_ 1012 DKAnchor_ExtNFCStatus_A7 "Exterior NFC Reader Fault";
CM_ SG_ 1012 DKAnchor_IntNFCStatus_A8 "Interior NFC Reader Fault";
CM_ SG_ 1012 DK_PhoneKeyPanicAlarmAlert "User requested PanicAlarm via C-App";
CM_ SG_ 1012 DK_PhoneKeyBattLowAlert "PhoneKey battery level lower than 20%";
CM_ SG_ 1012 DK_PhoneKeyIdleStsAlert "PhoneKey Idle  for n minutes (PHONEKEYIDLETIMEOUT)";
CM_ SG_ 1012 DK_VehicleIdleStsAlert "Vehicle idle for n days (TUNABLE_VEHICLE_IDLE_TIMEOUT )";
CM_ SG_ 1012 DK_BleOnOffStsAlert "Bluetooth On/Off status";
CM_ SG_ 1012 DK_LeftCarAlert "Alert when key left car";
CM_ SG_ 1012 DK_AuthFailAlert "Alert when Digital Key authentication fails";
CM_ SG_ 1012 DK_PhoneKeyForgotInsideAlert "Alert whenwhen fogot inside and attempting to lock";
CM_ SG_ 1012 DK_PhoneKeyApproachUnlockAlert "Alert when approach unklock successful/unsucessful";
CM_ SG_ 1012 DK_PhoneKeyCapabilityAlert "Alert when BLE only device detected";
CM_ SG_ 1012 DK_PhoneKeyNfcExteriorAuthFailAl "Alert when NFC Exterior reader auth fails";
CM_ SG_ 1012 DK_PhoneKeyNfcInteriorAuthFailAl "Alert when NFC Interior  reader auth fails";
CM_ SG_ 1012 DK_PhoneKeyTrunkClosingAlert "Alert when Tailgate is closing";
CM_ SG_ 1012 DK_PhoneKeyWalkawayLockFailAlert "Alert when Walkaway Lock fails.";
CM_ SG_ 1012 DK_PhoneKeyRemoteBLECmdFailAlert "Alert when Bluetooth Remote Command fails.";
CM_ SG_ 1014 Vehicle_Idle_Time "vehicle idle status";
CM_ SG_ 1014 PhoneKey_Idle_Time "PhoneKey idle status";
CM_ SG_ 1014 PhoneKey_BatteryLvl_Status "PhoneKey battery status";
CM_ SG_ 1015 MFS_L_Lever_Control "Left steering wheel lever control signal";
CM_ SG_ 1015 MFS_L_LeverButton_Control "Control signal for the left steering wheel lever button";
CM_ SG_ 1015 MFS_L_Failure "Fault signal of left multifunction control module of steering wheel";
CM_ SG_ 1015 MFS_L_UpControl "Left side upward control signal of steering wheel";
CM_ SG_ 1015 MFS_L_DownControl "Left side downward control signal of steering wheel";
CM_ SG_ 1015 MFS_L_LeftControl "Left control signal on the left side of the steering wheel";
CM_ SG_ 1015 MFS_L_RightControl "Left to right control signal of steering wheel";
CM_ SG_ 1015 MFS_LIN_error "LIN bus error signal of steering wheel multifunction module";
CM_ SG_ 1015 MFS_R_Lever_Control "Steering wheel right lever control signal";
CM_ SG_ 1015 MFS_R_LeverButton_Control "Steering wheel right lever button control signal";
CM_ SG_ 1015 MFS_R_Failure "Fault signal of multifunctional control module on the right side of the steering wheel";
CM_ SG_ 1015 MFS_R_UpControl "Control signal for upward movement on the right side of the steering wheel";
CM_ SG_ 1015 MFS_R_DownControl "Right side downward control signal of steering wheel";
CM_ SG_ 1015 MFS_R_LeftControl "Right control signal on the right side of the steering wheel";
CM_ SG_ 1015 MFS_R_RightControl "Right control signal on the right side of the steering wheel";
CM_ SG_ 1015 MFS_Delta_Scroll_Wheel_Left "Steering wheel left wheel operation signal";
CM_ SG_ 1015 MFS_Delta_Scroll_Wheel_Right "Steering wheel right wheel operation signal";
CM_ SG_ 1015 MFS_Scroll_Wheel_Left_Direction "Left wheel rolling direction signal";
CM_ SG_ 1015 MFS_Scroll_Wheel_Right_Direction "Right side roller rolling direction signal";
CM_ SG_ 1015 MFS_Scroll_Wheel_Left_Press "Left wheel pressing signal on steering wheel";
CM_ SG_ 1015 MFS_Scroll_Wheel_Right_Press "Signal for pressing the right wheel of the steering wheel";
CM_ SG_ 1015 MFS_Scroll_Wheel_Left_Valid "Signal indicating the effectiveness of the left wheel operation on the steering wheel";
CM_ SG_ 1015 MFS_Scroll_Wheel_Right_Valid "Signal indicating the effectiveness of the right wheel operation on the steering wheel";
CM_ SG_ 1015 MFS_Scroll_Wheel_Left_ID "Unique identifier for the left wheel of the steering wheel";
CM_ SG_ 1015 MFS_Scroll_Wheel_Right_ID "Unique identifier for the right wheel of the steering wheel";
CM_ SG_ 1027 CRC_CVC_MHU_EvSetting "Checksum for EV setting";
CM_ SG_ 1027 ALIVE_CVC_MHU_EvSetting "Alive Counter for EV Setting";
CM_ SG_ 1027 MHU_CVC_CreepDisable_stt "Request for CVC to disable creep function";
CM_ SG_ 1027 CVC_BrakeRegenMode "Brake Regen Style";
CM_ SG_ 1027 CVC_ChargeSetTargetSOC "Request for CVC to set target HV SOC";
CM_ SG_ 1027 CVC_ChargeScheduleSet "Request for CVC to enable/disable Charging Scheduling";
CM_ SG_ 1027 CVC_ChargingRequest "Request for CVC to ON/OFF Charging when schedule is reached";
CM_ SG_ 1027 CVC_ChgPort_Open_req "Request to open charging port(release latch)";
CM_ SG_ 1027 CVC_SET_DrivingModeSwitch "Change vehicle driving mode";
CM_ SG_ 1027 CVC_ValetMode_Activation "Activate Valet mode from MHU";
CM_ SG_ 1027 CVC_ValetMode_MaxSpeed "Setting of maximum allowable in valet mode";
CM_ SG_ 1027 CVC_ChargingCurrentLimit "Request CVC the max charging current at the rush hour - Apply for AC charging only at home";
CM_ SG_ 1027 CVC_PreheatBatt_Req "Preheat battery request";
CM_ SG_ 1031 CVC_RearWiperAutoMode "Turn On/Off Auto rear wiper";
CM_ SG_ 1037 CRC_CVC_DIGIT_SPEED "Checksum";
CM_ SG_ 1037 ALIVE_CVC_DIGIT_SPEED "Alive Counter";
CM_ SG_ 1037 CVC_DigitSpeed "This signal represents the digital speed and is displayed values between 301 and 511 are invalid.";
CM_ BO_ 1044 "CVC_HOD_Status";
CM_ SG_ 1044 CRC_CVC_HOD_Status "This signal includes a CRC checksum value which has for purpose of securing the communication path end to end (E2E).";
CM_ SG_ 1044 ALIVE_CVC_HOD_Status "This signal includes a counter value which has for purpose of securing the communication path end to end (E2E).";
CM_ SG_ 1044 HOD_Calc_Threshold_CH0 "The signal represents the calculated threshold value for the hands-off detection.";
CM_ SG_ 1044 HOD_Calc_Threshold_CH1 "The signal represents the calculated threshold value for the hands-off detection.";
CM_ SG_ 1044 HOD_Immag_Impedence_CH0 "The signal represents the currently measured imaginary part value.";
CM_ SG_ 1044 HOD_Immag_Impedence_CH1 "The signal represents the currently measured imaginary part value.";
CM_ SG_ 1044 HOD_ERR_STATE "The signal includes the error information of the HOD.";
CM_ SG_ 1044 HOD_RsErr_HOD "The signal represents the standard communication error bit as specified in the LIN protocol.";
CM_ SG_ 1044 HOD_Status "The signal includes the information, whether the driver touches the steering wheel or not.";
CM_ SG_ 1052 CRC_SCMF_SEAT_POSITION "Checksum";
CM_ SG_ 1052 ALIVE_SCMF_SEAT_POSITION "Alive Counter";
CM_ SG_ 1052 SCMF_Seat_track_pos_Dri "SCMF Seat track position driver";
CM_ SG_ 1052 SCMF_Seat_track_posPas "SCMF Seat track position front passenger";
CM_ SG_ 1055 CRC_OCS_PasSts "Checksum";
CM_ SG_ 1055 ALIVE_OCS_PasSts "Alive Counter";
CM_ SG_ 1055 OCS_Passenger_class_stat "Occupant classification for passenger";
CM_ SG_ 1059 AVAS_BatteryUnderVoltage "Battery voltage below threshold";
CM_ SG_ 1059 AVAS_BatteryOverVoltage "Battery voltage over threshold";
CM_ SG_ 1059 AVAS_VINInfoNotPrgm "VIN code is not saved";
CM_ SG_ 1059 AVAS_AMPVoltSplDrvOperationFail "AMP voltage supply drive operation fail";
CM_ SG_ 1059 AVAS_AMPIntFaultOverCurr "Amplifier internal overcurrent fail";
CM_ SG_ 1059 AVAS_AMPInternalFaultDCError "Amplifier internal DC fault";
CM_ SG_ 1059 AVAS_AMPInternalFaultOverTemp "Amplifier internal over-temperature fault";
CM_ SG_ 1059 AVAS_AMPInternalFaultClockError "Amplifier internal clock fault";
CM_ SG_ 1059 AVAS_SpkrMntPwrSwDrvHighFlt "Speaker monitor power switch drive high fault";
CM_ SG_ 1059 AVAS_SpkrMntPwrSwDrvLowFlt "speaker power switch drive low fault";
CM_ SG_ 1059 AVAS_InternalSpeakerOpen "Internal speaker open";
CM_ SG_ 1059 AVAS_ECUMalFlshOperationErr "ECU malfunction : flash operation error";
CM_ SG_ 1059 AVAS_ECUMalfunctionRamFailure "ECU malfunction : RAM failure";
CM_ SG_ 1059 AVAS_ECUMalEEPROMFailure "EEPROM operation fail";
CM_ SG_ 1059 AVAS_CANBusOff "CAN Bus off";
CM_ SG_ 1059 AVAS_LossCommVehicleSpeed "Loss Communication with vehicle speed signal";
CM_ SG_ 1059 AVAS_LossCommGearPosition "Loss Communication with gear position signal";
CM_ SG_ 1059 AVAS_LossCommAVASCloseCmd "Loss Communication with avas close command signal";
CM_ SG_ 1059 AVAS_EnableSts "AVAS enable disable state";
CM_ SG_ 1064 TRMFitted "Signal indicating that TRM is fitted or not. Signal is copy of H16 parameter in the VOD setting withing XGW";
CM_ SG_ 1067 CRC_SCMF_FR_SEAT_CONTROL "Checksum";
CM_ SG_ 1067 ALIVE_SCMF_FR_SEAT_CONTROL "Alive Counter";
CM_ SG_ 1067 SCMF_PsSeat_Control_Status "Right front seat control status";
CM_ SG_ 1067 SCMF_PsTiltPos "Current tilt position of the right front seat";
CM_ SG_ 1067 SCMF_PsReclinerPos "Current position of the right front seat recliner";
CM_ SG_ 1067 SCMF_PsHeightPos "Current height position of the right front seat";
CM_ SG_ 1067 SCMF_PsTrackPos "Current track position of right front seat";
CM_ SG_ 1067 SCMF_SeatRecliner_FRSw "Switch for controlling the position of the seat right front tilt adjuster";
CM_ SG_ 1067 SCMF_SeatTilt_FRSw "Switch for controlling the tilt position of the right front seat";
CM_ SG_ 1067 SCMF_SeatHeight_FRSw "Switch for controlling the height position of the right front seat";
CM_ SG_ 1067 SCMF_SeatTrack_FRSw "Switch for controlling the position of the right front seat track";
CM_ SG_ 1068 CRC_SCMF_FL_SEAT_CONTROL "Checksum";
CM_ SG_ 1068 ALIVE_SCMF_FL_SEAT_CONTROL "Alive Counter";
CM_ SG_ 1068 SCMF_D_DrvSeat_Control_Status "SCMF_D driver seat control status";
CM_ SG_ 1068 SCMF_D_DrvTiltPos "Current tilt position of driver seat";
CM_ SG_ 1068 SCMF_D_DrvReclinerPos "Current recliner position of driver seat";
CM_ SG_ 1068 SCMF_D_DrvHeightPos "Current height position of driver seat";
CM_ SG_ 1068 SCMF_D_DrvTrackPos "Current track position of driver seat";
CM_ SG_ 1068 SCMF_SeatRecliner_FLSw "The switch to control recliner position of the Seat front left";
CM_ SG_ 1068 SCMF_SeatTilt_FLSw "The switch to control tilt position of the Seat front left";
CM_ SG_ 1068 SCMF_SeatHeight_FLSw "The switch to control height position of the Seat front left";
CM_ SG_ 1068 SCMF_SeatTrack_FLSw "The switch to control track position of the Seat front left";
CM_ SG_ 1071 BCMFL_STAT_LeftMirrorHeating "Feedback Left mirror heating status";
CM_ SG_ 1071 BCMFL_STAT_LeftMirrorFold "Control the mirror fold/unfold and feedback mirror status";
CM_ SG_ 1071 BCMFL_STAT_MirrorAdjustLeft "Feedback actual left mirror position";
CM_ SG_ 1071 BCMFL_STAT_LeftMirrorPosX "Feedback actual left mirror left right position";
CM_ SG_ 1071 BCMFL_STAT_LeftMirrorPosY "Feedback actual left mirror up down position";
CM_ SG_ 1072 BCMFR_STAT_RightMirrorHeating "Feedback right mirror heating status";
CM_ SG_ 1072 BCMFR_STAT_RightMirrorFold "Control right mirror fold/unfold and feedback mirror status";
CM_ SG_ 1072 BCMFR_STAT_MirrorAdjustRight "Feedback actual right mirror position";
CM_ SG_ 1072 BCMFR_STAT_RightMirrorPosX "Feedback actual right mirror left right position";
CM_ SG_ 1072 BCMFR_STAT_RightMirrorPosY "Feedback actual right mirror up down position";
CM_ SG_ 181 BCMFR_WindowsFR_AntiPinch_Warn "Feedback anti-pinch status to CVC for HMI warning";
CM_ SG_ 181 BCMFR_WindowFR_Learning_Sts "Feedback learning status to CVC";
CM_ SG_ 181 BCMFR_WindowFR_Suppression_Warn "Feedback the lifter suppression status";
CM_ SG_ 181 BCMFR_WindowFR_LockActive "Feedback current window lock status";
CM_ SG_ 181 BCMFR_WindowFR_ThermalProtect "Feedback thermal protection status";
CM_ SG_ 181 BCMFR_WindowFR_Error "Feedback front right  window error position to CVC for corresponding warning on HMI";
CM_ SG_ 181 BCMFR_WindowsRR_AntiPinch_Warn "Feedback anti-pinch status to CVC for HMI warning";
CM_ SG_ 181 BCMFR_WindowRR_LockActive "Feedback current window lock status";
CM_ SG_ 181 BCMFR_WindowRR_Error "Feedback rear right window error position to CVC for corresponding warning on HMI";
CM_ SG_ 181 BCMFR_WindowRR_Learning_Sts "Feedback learning status to CVC";
CM_ SG_ 181 BCMFR_WindowRR_Suppression_Warn "Feedback the lifter suppression status";
CM_ SG_ 181 BCMFR_WindowRR_ThermalProtect "Feedback thermal protection status";
CM_ SG_ 181 BCMFR_WindowBtnPress_FrontPass "Front Right Window button status";
CM_ SG_ 181 Window_Position_FR "Feedback the current front right window position to CVC";
CM_ SG_ 181 Window_Position_RR "Feedback the current rear right window position to CVC";
CM_ SG_ 181 BCMFR_WindowBtnPress_RR "Rear Right Window Button status";
CM_ SG_ 535 BCM_PositionLight_RL_STS "Feedback status of RL position light";
CM_ SG_ 535 BCM_PositionLight_RR_STS "Feedback status of RR position light";
CM_ SG_ 535 BCM_TurnIndicator_RL_STS "Feedback status of RL indicator";
CM_ SG_ 535 BCM_TurnIndicator_RR_STS "Feedback status of RR indicator";
CM_ SG_ 535 BCM_ReverseLamp_RL_STS "Feedback left reverse lamp status";
CM_ SG_ 535 BCM_ReverseLamp_RR_STS "Feedback right reverse lamp status";
CM_ SG_ 535 BCM_BrakeLight_RL_STS "Feedback left brake light status";
CM_ SG_ 535 BCM_BrakeLight_RR_STS "Feedback right brake light status";
CM_ SG_ 535 BCM_RearFogLamp_RR_STS "Feedback Front fog light right";
CM_ SG_ 535 BCM_BrakeLight_Center_STS "Feedback center mounting light status";
CM_ SG_ 535 BCM_LicensePlateLamp_RE_STS "Feedback license plate lamp status";
CM_ SG_ 535 BCM_RearFogLamp_RL_STS "Feedback Front fog light left";
CM_ SG_ 535 BCM_PositionLight_RM_STS "RM Position Light Status";
CM_ SG_ 535 BCM_ParkingLight_RL_STS "RL Parking Light Status";
CM_ SG_ 535 BCM_ParkingLight_RM_STS "RM Parking Light Status";
CM_ SG_ 535 BCM_ParkingLight_RR_STS "RR Parking Light Status";
CM_ SG_ 1079 CRC_CVC_MHU_info_2 "Checksum";
CM_ SG_ 1079 ALIVE_CVC_MHU_info_2 "Alive Counter";
CM_ SG_ 1079 CVC_LimiterSpeed "Set Limiter Speed";
CM_ SG_ 1079 CVC_SpdLimiterSts "Speed Limiter state";
CM_ SG_ 1079 CVC_Instant_ConsumEnergy "Instant Consumption Energy";
CM_ SG_ 1079 CVC_SpdLim_OverrideSts "Extra Override Speed in Speed Limiter";
CM_ SG_ 1079 CVC_Average_ConsumEnergy "Average Consumption Energy";
CM_ SG_ 1079 CVC_DCM_Status "Indicate if there is any fault related to DCM  from CVC";
CM_ SG_ 1082 CRC_CVC_MHU_info "Checksum";
CM_ SG_ 1082 ALIVE_CVC_MHU_info "Alive counter";
CM_ SG_ 1082 CVC_BrakeRegenMode "CVC Brake regenerative mode";
CM_ SG_ 1082 CVC_CreepEnable_stt "Feedback for Creep disable request";
CM_ SG_ 1082 CVC_PowerRegenGaugeDisplay "Power Regen gauge display, plus vaue is power level, minus value is regen level.";
CM_ SG_ 1082 CVC_Regen_available "When braking / coasting regeneration system not available or regeneration system capability = 0 or regeneration system = failed.";
CM_ SG_ 1082 CVC_StoppingMode_stt "Stopping mode status";
CM_ SG_ 1082 CVC_AutoP_Feedback "CVC feedback Auto P Setting status";
CM_ SG_ 1082 CVC_SOC_display "HV battery SOC for displaying only - for CVC strategy";
CM_ SG_ 1082 CVC_Hvbatt_charging_stt "HV battery charging - not charging status,for displaying only ( for both regen/ charging )";
CM_ SG_ 1082 CVC_PreheatBatt_Sts "Preheat battery status";
CM_ SG_ 1084 CRC_SCMF_Info1 "SCMF_InfoCheckSum";
CM_ SG_ 1084 ALIVE_SCMF_Info1 "Alive Counter";
CM_ SG_ 1084 MmrySeatSSaveTips "Prompt for successful saving of current sitting position";
CM_ SG_ 1084 SeatSNoRecordWaring "Warning for no record of current sitting position";
CM_ SG_ 1084 CmfblUOActiveSts "Comfortable Up and Off  Active Status";
CM_ SG_ 1084 CmfblUOSetSt "Comfortable Up and Off  Set Statu";
CM_ SG_ 1084 PstiUncftyFb "Position Unconformity Feedback";
CM_ SG_ 1084 RMrrStFlg "Seat Operation Flag";
CM_ SG_ 1085 CRC_SCMF_Info3 "SCMF_Info3CheckSum";
CM_ SG_ 1085 ALIVE_SCMF_Info3 "Alive Counter";
CM_ SG_ 1085 CmfblUOActiveSts_Sec_1 "Comfortable Up and Off  Active Status";
CM_ SG_ 1085 CmfblUOSetSt_Sec_1 "Comfortable Up and Off  Set Statu";
CM_ SG_ 1085 PstiUncftyFb_R1 "Position Unconformity Feedback";
CM_ SG_ 1085 RMrrStFlg_R1 "Seat Operation Flag";
CM_ SG_ 1085 DrStHtCntSt_sec "Second row driver's seat heating control status(Reserved)";
CM_ SG_ 1085 DrStHtRunSt_sec "Heating operation status of the driver's seat on the second row(Reserved)";
CM_ SG_ 1085 PStHtCntSt_sec "Second row passenger side seat heating control status";
CM_ SG_ 1085 PStHtRunSt_sec "Heating operation status of the second row passenger side seat";
CM_ SG_ 1085 DrStVtRunSt_sec "Ventilation operation status of the driver's side seat in the second row";
CM_ SG_ 1085 PStVtRunSt_sec "Ventilation operation status of the second row passenger seat";
CM_ SG_ 1086 CRC_SCMF_Info4 "SCMF_Info4CheckSum";
CM_ SG_ 1086 ALIVE_SCMF_Info4 "Alive Counter";
CM_ SG_ 1086 CmfblUOActiveSts_Sec_2 "Comfortable up and down movement state";
CM_ SG_ 1086 CmfblUOSetSt_Sec_2 "Comfortable up and down opening and closing state";
CM_ SG_ 1086 PstiUncftyFb_R2 "Position inconsistency feedback";
CM_ SG_ 1086 RMrrStFlg_R2 "Seat operation signs";
CM_ SG_ 1086 DrStHtCntSt_3rd "Third row driver's seat side heating control status(Reserved)";
CM_ SG_ 1086 DrStHtRunSt_3rd "Third row driver's seat side hot running status(Reserved)";
CM_ SG_ 1086 PStHtCntSt_3rd "Third row passenger seat side heating control status";
CM_ SG_ 1086 PStHtRunSt_3rd "Third row passenger seat side hot running status";
CM_ SG_ 1090 WLC_IC_Error "Internal Error (Charging IC)";
CM_ SG_ 1090 WLC_FAN_Error "FAN fault";
CM_ SG_ 1090 WLC_TempSNSR_Error "Temperature sensor fault";
CM_ SG_ 1090 WLC_Setting_standard "Need to transmit information on WLC ON/OFF Setting standard or Set standard";
CM_ SG_ 1090 Transmit_WLC_situation "Need to transmit WLC situation signal";
CM_ SG_ 1090 WLC_Phoneforgetalert_state "Phone forget alert function on/off Status";
CM_ SG_ 1090 WLC_Resp_Error "Any error from WLC side";
CM_ SG_ 1090 WLC_FOD_Error "FOD error, Foreign Object detection";
CM_ SG_ 1090 WLC_Curr_Error "Over current";
CM_ SG_ 1090 WLC_Temp_Error "Over temperature";
CM_ SG_ 1090 WLC_VehSpeed_Error "Maximum vehicle speed over error (> 300 km/h)";
CM_ SG_ 1093 RS_Sol_L "Left Solar sensor values for the CCU";
CM_ SG_ 1093 RS_Sol_R "Right Solar sensor values for the CCU";
CM_ SG_ 1093 RS_F_LightSensor "Light sensor HW error";
CM_ SG_ 1093 RS_F_HUD_Sensor "HUD HW error";
CM_ SG_ 1093 RS_St_LampReq "Rain light sensor lamp request";
CM_ SG_ 1093 RS_St_CurrentRain "Represents the intensity of rain from RLS";
CM_ SG_ 1093 RS_HUD_illuminance "HUD sensor input";
CM_ SG_ 529 BCM_LowBeam_FL_Sts "Low beam headlight left front status";
CM_ SG_ 529 BCM_HighBeam_FL_Sts "High beam left front status";
CM_ SG_ 529 BCM_TurnIndicator_FL_STS "Feedback status of left front indicator";
CM_ SG_ 529 BCM_PositionLight_FL_STS "Left front position light feedback status";
CM_ SG_ 529 BCM_RearFogLamp_FL_STS "Feedback front left fog lamp";
CM_ SG_ 529 BCM_HeightSensorSTS_Front "The working status of the front height sensor";
CM_ SG_ 529 BCM_HeightSensorValue_Front "Voltage value of front height sensor";
CM_ SG_ 529 BCM_MirrorLED_FL_STS "The status of the left front and rear mirror LED lights, such as the switch or fault status of the lights";
CM_ SG_ 529 BCM_HazardButton_FL_STS "The status of the left front (or specific position) hazard warning light button";
CM_ SG_ 529 BCM_DaytimeRunningLight_FL_Sts "Working status of left front daytime running light";
CM_ SG_ 529 BCM_FrontFogLamp_FL_STS "Working status of left front fog lamp";
CM_ SG_ 1100 SCMF_RLSeatVent_Sts "Ventilation setting status of the driver's seat on the second row";
CM_ SG_ 1100 SCMF_RRSeatVent_Sts "Ventilation setting status of the second row passenger seat";
CM_ SG_ 1100 MmryFctOprtSetSt "Memory FunctionOperation Set Statu";
CM_ SG_ 1100 PsStHtCntSt "Passenger  Seat  Heat Control  Status(Reserved)";
CM_ SG_ 1100 PsStHtRunSt "Passenger  Seat  Heat Running Status(Reserved)";
CM_ SG_ 1100 DrStHtCntSt "Driver  Seat  Heat Control Status(Reserved)";
CM_ SG_ 1100 DrStHtRunSt "Driver  Seat  Heat Running Status(Reserved)";
CM_ SG_ 1100 SCMF_FRSeatVent_Sts "Passenger  Seat  Vent Set Status";
CM_ SG_ 1100 PsStVtRunSt "Passenger Seat Vent Running Status";
CM_ SG_ 1100 SCMF_FLSeatVent_Sts "Driver  Seat  Vent Set Status";
CM_ SG_ 1100 DrStVtRunSt "Driver Seat Vent Running Status";
CM_ SG_ 1100 Key2AscitAcuntSt "Key 2 associated accounts Status";
CM_ SG_ 1100 Key1AscitAcuntSt "Key 1 associated accounts Status";
CM_ SG_ 1100 Key4AscitAcuntSt "Key 4 associated accounts Status";
CM_ SG_ 1100 Key3AscitAcuntSt "Key 3 associated accounts Status";
CM_ SG_ 1100 MmryDrvSeatSSetReq "Memory Drive seat status setting request";
CM_ SG_ 1100 MmryPsSeatSSetReq "Memory passenger seat status setting request";
CM_ SG_ 1110 OP_WISW_SZL_LIN "Wiper Status Signal (Right Stalk)";
CM_ SG_ 1110 COMM_ERR_SZL_LIN "This signal showes if there is or was a communication error.";
CM_ SG_ 1110 BCM_Wiper_Front_Status "Front Wiper Motor Feedback of status";
CM_ SG_ 1110 OP_WIPO_SZL_LIN "Wiper Step (Right Stalk)";
CM_ SG_ 1110 OP_COLS_SZL_LIN "Left Stalk Lever Signal (Light function)";
CM_ SG_ 1110 NOD_ERR_SZL_LIN "If SCM detects any error (any error status occurred), SCM sends this signal as ?error active?.";
CM_ SG_ 1110 BCM_Wiper_Rear_Status "Rear wiper status check";
CM_ SG_ 1110 ALIV_WISW_SZL_LIN "Standard Alive-counter for validation of the transmission between SCM and Master ECU.";
CM_ SG_ 1152 CRC_SCMF_WarnMsg "Checksum for SCMF warning message";
CM_ SG_ 1152 ALIVE_SCMF_WarnMsg "Alive counter for SCMF warning message";
CM_ SG_ 1152 SCMF_DrvSeatMissalignment "Driver Seat Misalignment";
CM_ SG_ 1152 SCMF_PasSeatMisalignment "Passenger Seat Misalignment";
CM_ SG_ 1152 SCMF_WflagRes3 "Warning Flag Reserved Bit 3";
CM_ SG_ 1152 SCMF_WflagRes4 "Warning Flag Reserved Bit 4";
CM_ SG_ 1152 SCMF_WflagRes5 "Warning Flag Reserved Bit 5";
CM_ SG_ 1152 SCMF_WflagRes6 "Warning Flag Reserved Bit 6";
CM_ SG_ 1152 SCMF_WflagRes7 "Warning Flag Reserved Bit 7";
CM_ SG_ 1152 SCMF_WflagRes8 "Warning Flag Reserved Bit 8";
CM_ SG_ 1152 SCMF_WflagRes9 "Warning Flag Reserved Bit 9";
CM_ SG_ 1152 SCMF_WflagRes10 "Warning Flag Reserved Bit 10";
CM_ SG_ 1152 SCMF_WflagRes11 "Warning Flag Reserved Bit 11";
CM_ SG_ 1152 SCMF_WflagRes12 "Warning Flag Reserved Bit 12";
CM_ SG_ 1155 TPMS_FLTirePress "Front left tire pressure signal";
CM_ SG_ 1155 TPMS_FRTirePress "Front right tire pressure signal";
CM_ SG_ 1155 TPMS_RLTirePress "Rear left tire pressure signal";
CM_ SG_ 1155 TPMS_RRTirePress "Rear right tire pressure signal";
CM_ SG_ 1155 TPMS_FLTirePressAlarm "Front left tire pressure alarm  signal";
CM_ SG_ 1155 TPMS_FRTirePressAlarm "Front right tire pressure alarm signal";
CM_ SG_ 1155 TPMS_RLTirePressAlarm "Rear left tire pressure alarm signal";
CM_ SG_ 1155 TPMS_RRTirePressAlarm "Rear right tire pressure alarm signal";
CM_ SG_ 1155 TPMS_TirePosition "Tire position signal";
CM_ SG_ 1155 TPMS_ready2learning "BCM feedback signal ready to learning";
CM_ SG_ 1155 TPMS_TireTempAlarm "Tire temperature alarm signal";
CM_ SG_ 1155 TPMS_LearningStatus "BCM feedback signal for learning status";
CM_ SG_ 1155 TPMS_TireTemp "Tire temperature signal";
CM_ SG_ 1157 TBOX_RPADirSel "Remote Parking Direction Selection: During remote parking, the user clicks the available parking direction displayed on the APP for selection, and TBOX forwards TBOX_RPADirSel to ANRC to feedback the specific parking direction selected by the user. ANRC feeds back the user's choice of direction signals sent by the APP";
CM_ SG_ 1158 CRC_TPMS_TirePressure2 "Checksum";
CM_ SG_ 1158 ALIVE_TPMS_TirePressure2 "Alive Counter";
CM_ SG_ 1158 TPMS_FLTirePressAlarm2 "Front left tire pressure alarm  signal";
CM_ SG_ 1158 TPMS_FRTirePressAlarm2 "Front right tire pressure alarm signal";
CM_ SG_ 1158 TPMS_RLTirePressAlarm2 "Rear left tire pressure alarm signal";
CM_ SG_ 1158 TPMS_RRTirePressAlarm2 "Rear right tire pressure alarm signal";
CM_ SG_ 1158 TPMS_FLTireBattVoltage "Send front left tire pressure Battery Voltage status to CVC";
CM_ SG_ 1158 TPMS_FRTireBattVoltage "Send front right tire pressure Battery Voltage status to CVC";
CM_ SG_ 1158 TPMS_RRTireBattVoltage "Send rear right tire pressure Battery Voltage status to CVC";
CM_ SG_ 1158 TPMS_RLTireBattVoltage "Send rear left tire pressure Battery Voltage status to CVC";
CM_ SG_ 1160 CRC_ACU_WarnMsg "Checksum for ACU warning message";
CM_ SG_ 1160 ALIVE_ACU_WarnMsg "Alive counter for ACU warning message";
CM_ SG_ 1160 ACU_Malfunction "ACU Malfunction (trigger airbag warning lamp)";
CM_ SG_ 1160 ACU_Pre_Drive_Check "ACU status after pre-drive check (trigger airbag warning lamp if any failure)";
CM_ SG_ 1160 ACU_in_Plant_Mode "ACU plant mode status (trigger airbag warning lamp)";
CM_ SG_ 1160 ACU_PAB_Suppression "ACU suppress passenger airbag (front AB 1st stage, front AB 2nd stage, knee AB). This is used to trigger PAB indicator in MHU's display.";
CM_ SG_ 1160 ACU_Airbag_Disabled "ACU airbag disabled status due to Algo disabled or Firing disabled due to diagnostic or inert calibration file is flashed (trigger Airbag warning lamp when airbag is disabled)";
CM_ SG_ 1160 ACU_Development_Calibration "ACU calibration file status indicate whether ACU is flashed with calibration file for development purpose only (trigger Airbag warning lamp and chime when ACU is flashed with development calibration file)";
CM_ SG_ 1160 ACU_In_Disposal_Mode "ACU disposal mode status (trigger airbag warning lamp when ACU in disposal mode)";
CM_ SG_ 1166 CRC_ETG_WarnMsg "Checksum";
CM_ SG_ 1166 ALIVE_ETG_WarnMsg "Alive Counter";
CM_ SG_ 1166 ETG_Malfunction "ETG_Malfunction";
CM_ SG_ 1166 ETG_Warning_Flag_2 "Warning Message Flag, Component owner, Supplier align and define for this signal";
CM_ SG_ 1166 ETG_Warning_Flag_3 "Warning Message Flag, Component owner, Supplier align and define for this signal";
CM_ SG_ 1166 ETG_Warning_Flag_4 "Warning Message Flag, Component owner, Supplier align and define for this signal";
CM_ SG_ 1166 ETG_Warning_Flag_5 "Warning Message Flag, Component owner, Supplier align and define for this signal";
CM_ SG_ 1166 ETG_Warning_Flag_6 "Warning Message Flag, Component owner, Supplier align and define for this signal";
CM_ SG_ 1166 ETG_Warning_Flag_7 "Warning Message Flag, Component owner, Supplier align and define for this signal";
CM_ SG_ 1166 ETG_Warning_Flag_8 "Warning Message Flag, Component owner, Supplier align and define for this signal";
CM_ SG_ 1166 ETG_Warning_Flag_9 "Warning Message Flag, Component owner, Supplier align and define for this signal";
CM_ SG_ 1166 ETG_Warning_Flag_10 "Warning Message Flag, Component owner, Supplier align and define for this signal";
CM_ SG_ 1166 ETG_Warning_Flag_11 "Warning Message Flag, Component owner, Supplier align and define for this signal";
CM_ SG_ 1166 ETG_Warning_Flag_12 "Warning Message Flag, Component owner, Supplier align and define for this signal";
CM_ SG_ 1171 CRC_BMS_WarnMsg "Checksum";
CM_ SG_ 1171 ALIVE_BMS_WarnMsg "Alive Counter";
CM_ SG_ 1171 BMS_PackTempSts "Pack temperature warning";
CM_ SG_ 1171 BMS_ThermalRunaway "Thermal runaway warning";
CM_ SG_ 1171 BMS_BatteryReplacement "Separate signal to indicate the battery replacement information(Battery replacement MHU)";
CM_ SG_ 1171 BMS_Warning_PowerDegrade "Pack Power Degrade: Battery is cold & limited capacity, please charge";
CM_ SG_ 1171 BMS_Warning_DeltaSoC "EV Battery Delta SOC is high, range reduction in vehicle will be absorbed";
CM_ SG_ 1171 BMS_Warning_HVILSts "HVIL warning signal";
CM_ SG_ 1171 BMS_Warning_Isolation "Coolant Leakage warning";
CM_ SG_ 1171 BMS_Warning_CoolantLeakage "Coolant Leakage warning";
CM_ SG_ 1171 BMS_MalfunctionSts "Malfunction status of battery for MHU display";
CM_ SG_ 1171 BMS_LowBattery "Low Battery Warning";
CM_ SG_ 1171 BMS_Warning_DeltaTemperature "Delta temperature warning signal";
CM_ SG_ 1171 BMS_Warning_BDUTemperatureSts "BDU temperature warning signal";
CM_ SG_ 1171 BMS_Warning_Contactor_Aging "Contactor Aging Warning";
CM_ SG_ 1171 BMS_Reserved_signal4 "Warning Message Flag, Component owner, Supplier align and define for this signal";
CM_ SG_ 1171 BMS_Reserved_signal5 "Warning Message Flag, Component owner, Supplier align and define for this signal";
BA_DEF_ BO_  "DiagRequest" ENUM  "No","Yes";
BA_DEF_ BO_  "DiagResponse" ENUM  "No","Yes";
BA_DEF_ BO_  "DiagState" ENUM  "No","Yes";
BA_DEF_ BO_  "GenMsgCycleTime" INT 0 65535;
BA_DEF_ BO_  "GenMsgCycleTimeFast" INT 0 65535;
BA_DEF_ BO_  "GenMsgDelayTime" INT 0 65535;
BA_DEF_ BO_  "GenMsgILSupport" ENUM  "No","Yes";
BA_DEF_ BO_  "GenMsgNrOfRepetition" INT 0 65535;
BA_DEF_ BO_  "GenMsgSendType" ENUM  "Cyclic","NoMsgSendType","NotUsed","NotUsed","NotUsed","NotUsed","NotUsed","IfActive","NoMsgSendType","NotUsed";
BA_DEF_ BO_  "NmAsrMessage" ENUM  "No","Yes";
BA_DEF_ BO_  "NmMessage" ENUM  "No","Yes";
BA_DEF_ SG_  "GenSigSendType" ENUM  "Cyclic","NoSigSendType","OnWriteWithRepetition","OnChange","OnChangeWithRepetition","IfActive","IfActiveWithRepetition","OnWrite","NotUsed","NotUsed","NotUsed","NotUsed","NotUsed";
BA_DEF_ SG_  "GenSigStartValue" INT 0 2147483647;
BA_DEF_ SG_  "GenSigTimeoutTime_ALL" INT 0 65535;
BA_DEF_ SG_  "InvalidValue" STRING ;
BA_DEF_ SG_  "GenSigInactiveValue" INT 0 2147483647;
BA_DEF_ BO_  "VFrameFormat" ENUM  "StandardCAN","ExtendedCAN","reserved","J1939PG","reserved","reserved","reserved","reserved","reserved","reserved","reserved","reserved","reserved","reserved","StandardCAN_FD","ExtendedCAN_FD";
BA_DEF_ BO_  "CANFD_BRS" ENUM  "0","1";
BA_DEF_ SG_  "SystemSignalLongSymbol" STRING ;
BA_DEF_ BO_  "SystemMessageLongSymbol" STRING ;
BA_DEF_DEF_  "DiagRequest" "No";
BA_DEF_DEF_  "DiagResponse" "No";
BA_DEF_DEF_  "DiagState" "No";
BA_DEF_DEF_  "GenMsgCycleTime" 0;
BA_DEF_DEF_  "GenMsgCycleTimeFast" 0;
BA_DEF_DEF_  "GenMsgDelayTime" 0;
BA_DEF_DEF_  "GenMsgILSupport" "Yes";
BA_DEF_DEF_  "GenMsgNrOfRepetition" 0;
BA_DEF_DEF_  "GenMsgSendType" "Cyclic";
BA_DEF_DEF_  "NmAsrMessage" "No";
BA_DEF_DEF_  "NmMessage" "No";
BA_DEF_DEF_  "GenSigSendType" "Cyclic";
BA_DEF_DEF_  "GenSigStartValue" 0;
BA_DEF_DEF_  "GenSigTimeoutTime_ALL" 0;
BA_DEF_DEF_  "InvalidValue" "";
BA_DEF_DEF_  "GenSigInactiveValue" 0;
BA_DEF_DEF_  "VFrameFormat" "StandardCAN_FD";
BA_DEF_DEF_  "CANFD_BRS" "1";
BA_DEF_DEF_  "SystemSignalLongSymbol" "";
BA_DEF_DEF_  "SystemMessageLongSymbol" "";
BA_ "GenMsgCycleTime" BO_ 854 1000;
BA_ "GenMsgCycleTimeFast" BO_ 854 20;
BA_ "GenMsgNrOfRepetition" BO_ 854 3;
BA_ "GenMsgCycleTime" BO_ 862 100;
BA_ "GenMsgCycleTime" BO_ 863 100;
BA_ "GenMsgCycleTime" BO_ 866 10;
BA_ "GenMsgCycleTime" BO_ 872 100;
BA_ "GenMsgCycleTime" BO_ 874 100;
BA_ "GenMsgCycleTime" BO_ 880 100;
BA_ "GenMsgCycleTime" BO_ 881 100;
BA_ "GenMsgCycleTime" BO_ 883 200;
BA_ "GenMsgCycleTime" BO_ 884 200;
BA_ "GenMsgCycleTimeFast" BO_ 884 20;
BA_ "GenMsgNrOfRepetition" BO_ 884 3;
BA_ "GenMsgCycleTime" BO_ 886 200;
BA_ "GenMsgCycleTimeFast" BO_ 886 20;
BA_ "GenMsgNrOfRepetition" BO_ 886 3;
BA_ "GenMsgCycleTime" BO_ 887 200;
BA_ "GenMsgCycleTimeFast" BO_ 887 20;
BA_ "GenMsgNrOfRepetition" BO_ 887 3;
BA_ "GenMsgCycleTime" BO_ 889 200;
BA_ "GenMsgCycleTimeFast" BO_ 889 20;
BA_ "GenMsgNrOfRepetition" BO_ 889 3;
BA_ "GenMsgCycleTime" BO_ 892 100;
BA_ "GenMsgCycleTime" BO_ 896 1000;
BA_ "GenMsgCycleTime" BO_ 897 40;
BA_ "GenMsgCycleTime" BO_ 899 1000;
BA_ "GenMsgCycleTime" BO_ 925 50;
BA_ "GenMsgCycleTime" BO_ 992 150;
BA_ "GenMsgCycleTime" BO_ 993 100;
BA_ "GenMsgCycleTime" BO_ 358 20;
BA_ "GenMsgCycleTime" BO_ 994 10;
BA_ "GenMsgCycleTime" BO_ 996 20;
BA_ "GenMsgCycleTime" BO_ 997 10;
BA_ "GenMsgCycleTime" BO_ 1004 100;
BA_ "GenMsgCycleTime" BO_ 1011 500;
BA_ "GenMsgCycleTime" BO_ 1012 100;
BA_ "GenMsgCycleTime" BO_ 1014 100;
BA_ "GenMsgCycleTime" BO_ 1015 1000;
BA_ "GenMsgCycleTimeFast" BO_ 1015 50;
BA_ "GenMsgNrOfRepetition" BO_ 1015 3;
BA_ "GenMsgCycleTime" BO_ 1027 100;
BA_ "GenMsgCycleTime" BO_ 1031 100;
BA_ "GenMsgCycleTime" BO_ 1037 120;
BA_ "GenMsgCycleTime" BO_ 1044 500;
BA_ "GenMsgCycleTime" BO_ 1052 1000;
BA_ "GenMsgCycleTime" BO_ 1055 500;
BA_ "GenMsgCycleTime" BO_ 1059 1000;
BA_ "GenMsgCycleTime" BO_ 1064 200;
BA_ "GenMsgCycleTime" BO_ 1067 200;
BA_ "GenMsgCycleTime" BO_ 1068 200;
BA_ "GenMsgCycleTime" BO_ 1071 100;
BA_ "GenMsgCycleTime" BO_ 1072 100;
BA_ "GenMsgCycleTime" BO_ 181 100;
BA_ "GenMsgCycleTime" BO_ 535 100;
BA_ "GenMsgCycleTime" BO_ 1079 100;
BA_ "GenMsgCycleTime" BO_ 1082 100;
BA_ "GenMsgCycleTime" BO_ 1084 100;
BA_ "GenMsgCycleTime" BO_ 1085 100;
BA_ "GenMsgCycleTime" BO_ 1086 100;
BA_ "GenMsgCycleTime" BO_ 1090 500;
BA_ "GenMsgCycleTime" BO_ 1093 100;
BA_ "GenMsgCycleTime" BO_ 529 100;
BA_ "GenMsgCycleTimeFast" BO_ 529 10;
BA_ "GenMsgNrOfRepetition" BO_ 529 3;
BA_ "GenMsgCycleTime" BO_ 1100 100;
BA_ "GenMsgSendType" BO_ 1110 1;
BA_ "GenMsgCycleTime" BO_ 1152 1000;
BA_ "GenMsgCycleTime" BO_ 1155 50;
BA_ "GenMsgCycleTime" BO_ 1157 50;
BA_ "GenMsgCycleTime" BO_ 1158 50;
BA_ "GenMsgCycleTime" BO_ 1160 1000;
BA_ "GenMsgCycleTime" BO_ 1166 100;
BA_ "GenMsgCycleTime" BO_ 1171 1000;
BA_ "InvalidValue" SG_ 854 ALIVE_CVC_ADAS_SOTA_REQUEST "Fh";
BA_ "InvalidValue" SG_ 854 CVC_ADAS_HWA_SOTA "7h";
BA_ "GenSigSendType" SG_ 854 CVC_ADAS_HWA_SOTA 2;
BA_ "InvalidValue" SG_ 854 CVC_ADAS_AESA_SOTA "7h";
BA_ "GenSigSendType" SG_ 854 CVC_ADAS_AESA_SOTA 2;
BA_ "InvalidValue" SG_ 854 CVC_ADAS_ALCA_SOTA "7h";
BA_ "GenSigSendType" SG_ 854 CVC_ADAS_ALCA_SOTA 2;
BA_ "InvalidValue" SG_ 854 CVC_ADAS_BasicCruise_SOTA "7h";
BA_ "GenSigSendType" SG_ 854 CVC_ADAS_BasicCruise_SOTA 2;
BA_ "InvalidValue" SG_ 854 CVC_ADAS_ACC_SOTA "7h";
BA_ "GenSigSendType" SG_ 854 CVC_ADAS_ACC_SOTA 2;
BA_ "InvalidValue" SG_ 854 CVC_ADAS_TSR_SOTA "7h";
BA_ "GenSigSendType" SG_ 854 CVC_ADAS_TSR_SOTA 2;
BA_ "InvalidValue" SG_ 854 CVC_ADAS_ISA_SOTA "7h";
BA_ "GenSigSendType" SG_ 854 CVC_ADAS_ISA_SOTA 2;
BA_ "InvalidValue" SG_ 854 CVC_ADAS_NOP_SOTA "7h";
BA_ "GenSigSendType" SG_ 854 CVC_ADAS_NOP_SOTA 2;
BA_ "InvalidValue" SG_ 854 CVC_ADAS_AAESA_SOTA "7h";
BA_ "GenSigSendType" SG_ 854 CVC_ADAS_AAESA_SOTA 2;
BA_ "InvalidValue" SG_ 854 CVC_ADAS_ALCM_SOTA "7h";
BA_ "GenSigSendType" SG_ 854 CVC_ADAS_ALCM_SOTA 2;
BA_ "InvalidValue" SG_ 854 CVC_ADAS_AACC_SOTA "7h";
BA_ "GenSigSendType" SG_ 854 CVC_ADAS_AACC_SOTA 2;
BA_ "InvalidValue" SG_ 854 CVC_ADAS_TLD_SOTA "7h";
BA_ "GenSigSendType" SG_ 854 CVC_ADAS_TLD_SOTA 2;
BA_ "InvalidValue" SG_ 854 CVC_ADAS_DNS_SOTA "7h";
BA_ "GenSigSendType" SG_ 854 CVC_ADAS_DNS_SOTA 2;
BA_ "InvalidValue" SG_ 854 CVC_ADAS_LDW_SOTA "7h";
BA_ "GenSigSendType" SG_ 854 CVC_ADAS_LDW_SOTA 2;
BA_ "InvalidValue" SG_ 854 CVC_ADAS_LKA_SOTA "7h";
BA_ "GenSigSendType" SG_ 854 CVC_ADAS_LKA_SOTA 2;
BA_ "InvalidValue" SG_ 854 CVC_ADAS_ELK_SOTA "7h";
BA_ "GenSigSendType" SG_ 854 CVC_ADAS_ELK_SOTA 2;
BA_ "InvalidValue" SG_ 854 CVC_ADAS_FAEB_SOTA "7h";
BA_ "GenSigSendType" SG_ 854 CVC_ADAS_FAEB_SOTA 2;
BA_ "InvalidValue" SG_ 854 CVC_ADAS_ESA_SOTA "7h";
BA_ "GenSigSendType" SG_ 854 CVC_ADAS_ESA_SOTA 2;
BA_ "InvalidValue" SG_ 854 CVC_ADAS_RAEB_SOTA "7h";
BA_ "GenSigSendType" SG_ 854 CVC_ADAS_RAEB_SOTA 2;
BA_ "InvalidValue" SG_ 854 CVC_ADAS_FCW_SOTA "7h";
BA_ "GenSigSendType" SG_ 854 CVC_ADAS_FCW_SOTA 2;
BA_ "InvalidValue" SG_ 854 CVC_ADAS_RCTA_SOTA "7h";
BA_ "GenSigSendType" SG_ 854 CVC_ADAS_RCTA_SOTA 2;
BA_ "InvalidValue" SG_ 854 CVC_ADAS_BSD_SOTA "7h";
BA_ "GenSigSendType" SG_ 854 CVC_ADAS_BSD_SOTA 2;
BA_ "InvalidValue" SG_ 854 CVC_ADAS_DOW_SOTA "7h";
BA_ "GenSigSendType" SG_ 854 CVC_ADAS_DOW_SOTA 2;
BA_ "InvalidValue" SG_ 854 CVC_ADAS_IA_SOTA "7h";
BA_ "GenSigSendType" SG_ 854 CVC_ADAS_IA_SOTA 2;
BA_ "InvalidValue" SG_ 854 CVC_ADAS_SVM_SOTA "7h";
BA_ "GenSigSendType" SG_ 854 CVC_ADAS_SVM_SOTA 2;
BA_ "InvalidValue" SG_ 854 CVC_ADAS_RVC_SOTA "7h";
BA_ "GenSigSendType" SG_ 854 CVC_ADAS_RVC_SOTA 2;
BA_ "InvalidValue" SG_ 854 CVC_ADAS_FPA_SOTA "7h";
BA_ "GenSigSendType" SG_ 854 CVC_ADAS_FPA_SOTA 2;
BA_ "InvalidValue" SG_ 854 CVC_ADAS_RPA_SOTA "7h";
BA_ "GenSigSendType" SG_ 854 CVC_ADAS_RPA_SOTA 2;
BA_ "InvalidValue" SG_ 854 CVC_ADAS_SpaFAPA_SOTA "7h";
BA_ "GenSigSendType" SG_ 854 CVC_ADAS_SpaFAPA_SOTA 2;
BA_ "InvalidValue" SG_ 854 CVC_ADAS_RP_SOTA "7h";
BA_ "GenSigSendType" SG_ 854 CVC_ADAS_RP_SOTA 2;
BA_ "InvalidValue" SG_ 854 CVC_ADAS_VParkingSelect_SOTA "7h";
BA_ "GenSigSendType" SG_ 854 CVC_ADAS_VParkingSelect_SOTA 2;
BA_ "InvalidValue" SG_ 854 CVC_ADAS_VParkingComfort_SOTA "7h";
BA_ "GenSigSendType" SG_ 854 CVC_ADAS_VParkingComfort_SOTA 2;
BA_ "InvalidValue" SG_ 854 CVC_ADAS_VParkingSummon_SOTA "7h";
BA_ "GenSigSendType" SG_ 854 CVC_ADAS_VParkingSummon_SOTA 2;
BA_ "InvalidValue" SG_ 854 CVC_ADAS_VParkingAutoRev_SOTA "7h";
BA_ "GenSigSendType" SG_ 854 CVC_ADAS_VParkingAutoRev_SOTA 2;
BA_ "InvalidValue" SG_ 854 CVC_ADAS_AHB_SOTA "7h";
BA_ "GenSigSendType" SG_ 854 CVC_ADAS_AHB_SOTA 2;
BA_ "InvalidValue" SG_ 854 CVC_ADAS_ADB_SOTA "7h";
BA_ "GenSigSendType" SG_ 854 CVC_ADAS_ADB_SOTA 2;
BA_ "InvalidValue" SG_ 854 CVC_ADAS_DMS_SOTA "7h";
BA_ "GenSigSendType" SG_ 854 CVC_ADAS_DMS_SOTA 2;
BA_ "InvalidValue" SG_ 854 CVC_ADAS_DMSFaceID_SOTA "7h";
BA_ "GenSigSendType" SG_ 854 CVC_ADAS_DMSFaceID_SOTA 2;
BA_ "InvalidValue" SG_ 854 CVC_ADAS_DCM_SOTA "7h";
BA_ "GenSigSendType" SG_ 854 CVC_ADAS_DCM_SOTA 2;
BA_ "InvalidValue" SG_ 854 CVC_ADAS_AdasEDR_SOTA "7h";
BA_ "GenSigSendType" SG_ 854 CVC_ADAS_AdasEDR_SOTA 2;
BA_ "InvalidValue" SG_ 854 CVC_ADAS_ACPE_SOTA "7h";
BA_ "GenSigSendType" SG_ 854 CVC_ADAS_ACPE_SOTA 2;
BA_ "InvalidValue" SG_ 854 CVC_ADAS_SentryMode_SOTA "7h";
BA_ "GenSigSendType" SG_ 854 CVC_ADAS_SentryMode_SOTA 2;
BA_ "InvalidValue" SG_ 862 ALIVE_CVC_Vehicle_info "Fh";
BA_ "GenSigStartValue" SG_ 862 CVC_VehLock_STS 3;
BA_ "GenSigStartValue" SG_ 862 CVC_ACInputChgCurLim 6;
BA_ "InvalidValue" SG_ 863 ALIVE_CVC_SchdlChg_Info "Fh";
BA_ "InvalidValue" SG_ 863 Ack_SchdlChg "3h";
BA_ "InvalidValue" SG_ 866 ALIVE_WCBS_RecuBrkTrqReq "Fh";
BA_ "InvalidValue" SG_ 866 WCBS_F_RegenTarTrq "FFFFh";
BA_ "GenSigStartValue" SG_ 866 WCBS_F_RegenTarTrq 4000;
BA_ "InvalidValue" SG_ 866 WCBS_R_RegenTarTrq "FFFFh";
BA_ "GenSigStartValue" SG_ 866 WCBS_R_RegenTarTrq 4000;
BA_ "InvalidValue" SG_ 866 WCBS_F_FrictionTarTrq "FFFFh";
BA_ "GenSigStartValue" SG_ 866 WCBS_F_FrictionTarTrq 4000;
BA_ "InvalidValue" SG_ 866 WCBS_R_FrictionTarTrq "FFFFh";
BA_ "GenSigStartValue" SG_ 866 WCBS_R_FrictionTarTrq 4000;
BA_ "InvalidValue" SG_ 880 MNF_WorkTimeRes "1Fh";
BA_ "InvalidValue" SG_ 880 MNF_TempSetRes "7Fh";
BA_ "InvalidValue" SG_ 880 MNF_AMB_T "FFh";
BA_ "InvalidValue" SG_ 881 MNF_INT_T "FFh";
BA_ "GenSigTimeoutTime_ALL" SG_ 883 CVC_WMCID_IVITheftWarning 1000;
BA_ "GenSigTimeoutTime_ALL" SG_ 883 CVC_WMCID_CAppTheftWarning 1000;
BA_ "GenSigTimeoutTime_ALL" SG_ 883 CVC_GPSMonitorStatus 1000;
BA_ "InvalidValue" SG_ 884 ALIVE_USS_RPA_Distance "Fh";
BA_ "InvalidValue" SG_ 884 USS_RPA_DistRLI "FFh";
BA_ "GenSigStartValue" SG_ 884 USS_RPA_DistRLI 255;
BA_ "GenSigSendType" SG_ 884 USS_RPA_DistRLI 2;
BA_ "InvalidValue" SG_ 884 USS_RPA_DistRLO "FFh";
BA_ "GenSigStartValue" SG_ 884 USS_RPA_DistRLO 255;
BA_ "GenSigSendType" SG_ 884 USS_RPA_DistRLO 2;
BA_ "InvalidValue" SG_ 884 USS_RPA_DistRRI "FFh";
BA_ "GenSigStartValue" SG_ 884 USS_RPA_DistRRI 255;
BA_ "GenSigSendType" SG_ 884 USS_RPA_DistRRI 2;
BA_ "InvalidValue" SG_ 884 USS_RPA_DistRRO "FFh";
BA_ "GenSigStartValue" SG_ 884 USS_RPA_DistRRO 255;
BA_ "GenSigSendType" SG_ 884 USS_RPA_DistRRO 2;
BA_ "InvalidValue" SG_ 886 ALIVE_USS_RPA_Status "Fh";
BA_ "InvalidValue" SG_ 886 USS_RPA_state "7h";
BA_ "GenSigStartValue" SG_ 886 USS_RPA_state 7;
BA_ "GenSigSendType" SG_ 886 USS_RPA_state 2;
BA_ "InvalidValue" SG_ 886 USS_RPA_AlertRLI "7h";
BA_ "GenSigSendType" SG_ 886 USS_RPA_AlertRLI 2;
BA_ "InvalidValue" SG_ 886 USS_RPA_AlertRLO "7h";
BA_ "GenSigSendType" SG_ 886 USS_RPA_AlertRLO 2;
BA_ "InvalidValue" SG_ 886 USS_RPA_AlertRRI "7h";
BA_ "GenSigSendType" SG_ 886 USS_RPA_AlertRRI 2;
BA_ "InvalidValue" SG_ 886 USS_RPA_AlertRRO "7h";
BA_ "GenSigSendType" SG_ 886 USS_RPA_AlertRRO 2;
BA_ "InvalidValue" SG_ 886 USS_RPA_SensorRLI "3h";
BA_ "GenSigStartValue" SG_ 886 USS_RPA_SensorRLI 3;
BA_ "GenSigSendType" SG_ 886 USS_RPA_SensorRLI 2;
BA_ "InvalidValue" SG_ 886 USS_RPA_SensorRLO "3h";
BA_ "GenSigStartValue" SG_ 886 USS_RPA_SensorRLO 3;
BA_ "GenSigSendType" SG_ 886 USS_RPA_SensorRLO 2;
BA_ "InvalidValue" SG_ 886 USS_RPA_SensorRRI "3h";
BA_ "GenSigStartValue" SG_ 886 USS_RPA_SensorRRI 3;
BA_ "GenSigSendType" SG_ 886 USS_RPA_SensorRRI 2;
BA_ "InvalidValue" SG_ 886 USS_RPA_SensorRRO "3h";
BA_ "GenSigStartValue" SG_ 886 USS_RPA_SensorRRO 3;
BA_ "GenSigSendType" SG_ 886 USS_RPA_SensorRRO 2;
BA_ "InvalidValue" SG_ 887 ALIVE_USS_FPA_Status "Fh";
BA_ "InvalidValue" SG_ 887 USS_FPA_state "7h";
BA_ "GenSigStartValue" SG_ 887 USS_FPA_state 7;
BA_ "GenSigSendType" SG_ 887 USS_FPA_state 2;
BA_ "GenSigSendType" SG_ 887 USS_FPA_AutoOn_Feed 2;
BA_ "InvalidValue" SG_ 887 USS_FPA_AlertFLI "7h";
BA_ "GenSigSendType" SG_ 887 USS_FPA_AlertFLI 2;
BA_ "InvalidValue" SG_ 887 USS_FPA_AlertFLO "7h";
BA_ "GenSigSendType" SG_ 887 USS_FPA_AlertFLO 2;
BA_ "InvalidValue" SG_ 887 USS_FPA_AlertFRI "7h";
BA_ "GenSigSendType" SG_ 887 USS_FPA_AlertFRI 2;
BA_ "InvalidValue" SG_ 887 USS_FPA_AlertFRO "7h";
BA_ "GenSigSendType" SG_ 887 USS_FPA_AlertFRO 2;
BA_ "InvalidValue" SG_ 887 USS_FPA_SensorFLI "3h";
BA_ "GenSigStartValue" SG_ 887 USS_FPA_SensorFLI 3;
BA_ "GenSigSendType" SG_ 887 USS_FPA_SensorFLI 2;
BA_ "InvalidValue" SG_ 887 USS_FPA_SensorFLO "3h";
BA_ "GenSigStartValue" SG_ 887 USS_FPA_SensorFLO 3;
BA_ "GenSigSendType" SG_ 887 USS_FPA_SensorFLO 2;
BA_ "InvalidValue" SG_ 887 USS_FPA_SensorFRI "3h";
BA_ "GenSigStartValue" SG_ 887 USS_FPA_SensorFRI 3;
BA_ "GenSigSendType" SG_ 887 USS_FPA_SensorFRI 2;
BA_ "InvalidValue" SG_ 887 USS_FPA_SensorFRO "3h";
BA_ "GenSigStartValue" SG_ 887 USS_FPA_SensorFRO 3;
BA_ "GenSigSendType" SG_ 887 USS_FPA_SensorFRO 2;
BA_ "InvalidValue" SG_ 889 ALIVE_USS_FPA_Distance "Fh";
BA_ "InvalidValue" SG_ 889 USS_FPA_DistFLI "FFh";
BA_ "GenSigStartValue" SG_ 889 USS_FPA_DistFLI 255;
BA_ "GenSigSendType" SG_ 889 USS_FPA_DistFLI 2;
BA_ "InvalidValue" SG_ 889 USS_FPA_DistFLO "FFh";
BA_ "GenSigStartValue" SG_ 889 USS_FPA_DistFLO 255;
BA_ "GenSigSendType" SG_ 889 USS_FPA_DistFLO 2;
BA_ "InvalidValue" SG_ 889 USS_FPA_DistFRI "FFh";
BA_ "GenSigStartValue" SG_ 889 USS_FPA_DistFRI 255;
BA_ "GenSigSendType" SG_ 889 USS_FPA_DistFRI 2;
BA_ "InvalidValue" SG_ 889 USS_FPA_DistFRO "FFh";
BA_ "GenSigStartValue" SG_ 889 USS_FPA_DistFRO 255;
BA_ "GenSigSendType" SG_ 889 USS_FPA_DistFRO 2;
BA_ "InvalidValue" SG_ 892 ALIVE_EVCC_Charging_Sts "Fh";
BA_ "InvalidValue" SG_ 892 EVCC_ChgGun_Sts "7h";
BA_ "InvalidValue" SG_ 892 EVCC_ChgFlap_Sts "3h";
BA_ "InvalidValue" SG_ 892 EVCC_ChgType "7h";
BA_ "InvalidValue" SG_ 892 EVCC_VehChg_Sts "7h";
BA_ "InvalidValue" SG_ 892 EVCC_ChgAuthen_Sts "7h";
BA_ "InvalidValue" SG_ 892 EVCC_PaymentType "7h";
BA_ "InvalidValue" SG_ 892 EVCC_VehChgCompError_Sts "7h";
BA_ "InvalidValue" SG_ 892 EVCC_S3Button_Sts "3h";
BA_ "InvalidValue" SG_ 897 ALIVE_ACU_OCCUPANT_STATUS "Fh";
BA_ "GenSigTimeoutTime_ALL" SG_ 899 CVC_VIN_Byte1 5000;
BA_ "GenSigTimeoutTime_ALL" SG_ 899 CVC_VIN_Byte2 5000;
BA_ "GenSigTimeoutTime_ALL" SG_ 899 CVC_VIN_Byte3 5000;
BA_ "GenSigTimeoutTime_ALL" SG_ 899 CVC_VIN_Byte4 5000;
BA_ "GenSigTimeoutTime_ALL" SG_ 899 CVC_VIN_Byte5 5000;
BA_ "GenSigTimeoutTime_ALL" SG_ 899 CVC_VIN_Byte6 5000;
BA_ "GenSigTimeoutTime_ALL" SG_ 899 CVC_VIN_Byte7 5000;
BA_ "InvalidValue" SG_ 925 ALIVE_CVC_AHB_Sts "Fh";
BA_ "InvalidValue" SG_ 925 CVC_AHB_Override "3h";
BA_ "InvalidValue" SG_ 992 ALIVE_CVC_HVsystem_status "Fh";
BA_ "InvalidValue" SG_ 993 ALIVE_CVC_HMI_Info "Fh";
BA_ "InvalidValue" SG_ 993 CVC_MHU_Ack_ChgSche_stt "3h";
BA_ "GenSigStartValue" SG_ 993 CVC_MHU_Ack_ChgSche_stt 3;
BA_ "GenSigStartValue" SG_ 993 CVC_MHU_Ack_TargetSOC 100;
BA_ "InvalidValue" SG_ 993 CVC_ValetMode_sts "FFh";
BA_ "InvalidValue" SG_ 993 CVC_BEDrvInhibit "3h";
BA_ "InvalidValue" SG_ 358 ALIVE_CVC_Status "Fh";
BA_ "InvalidValue" SG_ 358 CVC_CruiseSetSpd "FFh";
BA_ "GenSigStartValue" SG_ 358 CVC_CruiseSetSpd 30;
BA_ "InvalidValue" SG_ 358 CVC_REX_StartTimer "3FFh";
BA_ "GenSigStartValue" SG_ 358 CVC_REX_StartTimer 600;
BA_ "InvalidValue" SG_ 994 ALIVE_WCBS_IMU_Output "Fh";
BA_ "InvalidValue" SG_ 994 WCBS_LateralACC "FFFFh";
BA_ "GenSigStartValue" SG_ 994 WCBS_LateralACC 12000;
BA_ "InvalidValue" SG_ 994 WCBS_LongitudeACC "FFFFh";
BA_ "GenSigStartValue" SG_ 994 WCBS_LongitudeACC 12000;
BA_ "InvalidValue" SG_ 994 WCBS_VehDynYawRate "FFFFh";
BA_ "GenSigStartValue" SG_ 994 WCBS_VehDynYawRate 15000;
BA_ "InvalidValue" SG_ 994 WCBS_LateralACCRaw "FFFFh";
BA_ "GenSigStartValue" SG_ 994 WCBS_LateralACCRaw 30000;
BA_ "InvalidValue" SG_ 994 WCBS_LongitudeACCRaw "FFFFh";
BA_ "GenSigStartValue" SG_ 994 WCBS_LongitudeACCRaw 30000;
BA_ "InvalidValue" SG_ 994 WCBS_VehDynYawRateRaw "FFFFh";
BA_ "GenSigStartValue" SG_ 994 WCBS_VehDynYawRateRaw 30000;
BA_ "InvalidValue" SG_ 994 WCBS_ESCTarYawRate "FFFFh";
BA_ "GenSigStartValue" SG_ 994 WCBS_ESCTarYawRate 30000;
BA_ "InvalidValue" SG_ 996 ALIVE_IMU_Output2_Filtered "fh";
BA_ "InvalidValue" SG_ 996 IMU_VerticalACC "FFFFh";
BA_ "GenSigStartValue" SG_ 996 IMU_VerticalACC 30000;
BA_ "InvalidValue" SG_ 996 IMU_VehDynPitchRate "FFFFh";
BA_ "GenSigStartValue" SG_ 996 IMU_VehDynPitchRate 30000;
BA_ "InvalidValue" SG_ 996 IMU_VehDynRollRate "FFFFh";
BA_ "GenSigStartValue" SG_ 996 IMU_VehDynRollRate 30000;
BA_ "InvalidValue" SG_ 997 ALIVE_IMU_Output2_Unfiltered "fh";
BA_ "InvalidValue" SG_ 997 IMU_VerticalACCRaw "FFFFh";
BA_ "GenSigStartValue" SG_ 997 IMU_VerticalACCRaw 30000;
BA_ "InvalidValue" SG_ 997 IMU_VehDynPitchRateRaw "FFFFh";
BA_ "GenSigStartValue" SG_ 997 IMU_VehDynPitchRateRaw 30000;
BA_ "InvalidValue" SG_ 997 IMU_VehDynRollRateRaw "FFFFh";
BA_ "GenSigStartValue" SG_ 997 IMU_VehDynRollRateRaw 30000;
BA_ "InvalidValue" SG_ 1004 ALIVE_CVC_PanicEvent "Fh";
BA_ "GenSigSendType" SG_ 1004 CVC_PanicEventTrigger 7;
BA_ "GenSigSendType" SG_ 1004 CVC_PanicEventSource 7;
BA_ "GenSigSendType" SG_ 1004 CVC_PanicEventStatus 7;
BA_ "GenSigSendType" SG_ 1004 CVC_PanicEventCounter 7;
BA_ "InvalidValue" SG_ 1011 ALIVE_CVC_DKSettingStatus "Fh";
BA_ "InvalidValue" SG_ 1011 CVC_STAT_PaaK_Enable "3h";
BA_ "InvalidValue" SG_ 1011 CVC_STAT_UserSettingApproachUnlo "3h";
BA_ "InvalidValue" SG_ 1011 CVC_STAT_UserSettingWalkawayLock "3h";
BA_ "InvalidValue" SG_ 1011 CVC_STAT_LockUnlockDriveCfg_Phon "3h";
BA_ "InvalidValue" SG_ 1011 CVC_STAT_LockUnlockDriveCfg_NFC_ "3h";
BA_ "InvalidValue" SG_ 1012 ALIVE_DK_WarnMsg "Fh";
BA_ "SystemSignalLongSymbol" SG_ 1012 DK_PhoneKeyNfcExteriorAuthFailAl "DK_PhoneKeyNfcExteriorAuthFailAlert";
BA_ "SystemSignalLongSymbol" SG_ 1012 DK_PhoneKeyNfcInteriorAuthFailAl "DK_PhoneKeyNfcInteriorAuthFailAlert";
BA_ "InvalidValue" SG_ 1014 ALIVE_DK_PhoneInformation "Fh";
BA_ "InvalidValue" SG_ 1015 ALIVE_CVC_MFS_Control_Button "Fh";
BA_ "InvalidValue" SG_ 1015 MFS_L_Lever_Control "7h";
BA_ "GenSigSendType" SG_ 1015 MFS_L_Lever_Control 4;
BA_ "InvalidValue" SG_ 1015 MFS_L_LeverButton_Control "7h";
BA_ "GenSigSendType" SG_ 1015 MFS_L_LeverButton_Control 4;
BA_ "InvalidValue" SG_ 1015 MFS_L_Failure "3h";
BA_ "GenSigSendType" SG_ 1015 MFS_L_Failure 4;
BA_ "InvalidValue" SG_ 1015 MFS_L_UpControl "7h";
BA_ "GenSigSendType" SG_ 1015 MFS_L_UpControl 4;
BA_ "InvalidValue" SG_ 1015 MFS_L_DownControl "7h";
BA_ "GenSigSendType" SG_ 1015 MFS_L_DownControl 4;
BA_ "InvalidValue" SG_ 1015 MFS_L_LeftControl "7h";
BA_ "GenSigSendType" SG_ 1015 MFS_L_LeftControl 4;
BA_ "InvalidValue" SG_ 1015 MFS_L_RightControl "7h";
BA_ "GenSigSendType" SG_ 1015 MFS_L_RightControl 4;
BA_ "GenSigSendType" SG_ 1015 MFS_LIN_error 4;
BA_ "InvalidValue" SG_ 1015 MFS_R_Lever_Control "7h";
BA_ "GenSigSendType" SG_ 1015 MFS_R_Lever_Control 4;
BA_ "InvalidValue" SG_ 1015 MFS_R_LeverButton_Control "7h";
BA_ "GenSigSendType" SG_ 1015 MFS_R_LeverButton_Control 4;
BA_ "InvalidValue" SG_ 1015 MFS_R_Failure "3h";
BA_ "GenSigSendType" SG_ 1015 MFS_R_Failure 4;
BA_ "InvalidValue" SG_ 1015 MFS_R_UpControl "7h";
BA_ "GenSigSendType" SG_ 1015 MFS_R_UpControl 4;
BA_ "InvalidValue" SG_ 1015 MFS_R_DownControl "7h";
BA_ "GenSigSendType" SG_ 1015 MFS_R_DownControl 4;
BA_ "InvalidValue" SG_ 1015 MFS_R_LeftControl "7h";
BA_ "GenSigSendType" SG_ 1015 MFS_R_LeftControl 4;
BA_ "InvalidValue" SG_ 1015 MFS_R_RightControl "7h";
BA_ "GenSigSendType" SG_ 1015 MFS_R_RightControl 4;
BA_ "GenSigSendType" SG_ 1015 MFS_Delta_Scroll_Wheel_Left 4;
BA_ "GenSigSendType" SG_ 1015 MFS_Delta_Scroll_Wheel_Right 4;
BA_ "InvalidValue" SG_ 1015 MFS_Scroll_Wheel_Left_Direction "3h";
BA_ "GenSigSendType" SG_ 1015 MFS_Scroll_Wheel_Left_Direction 4;
BA_ "InvalidValue" SG_ 1015 MFS_Scroll_Wheel_Right_Direction "3h";
BA_ "GenSigSendType" SG_ 1015 MFS_Scroll_Wheel_Right_Direction 4;
BA_ "InvalidValue" SG_ 1015 MFS_Scroll_Wheel_Left_Press "3h";
BA_ "GenSigSendType" SG_ 1015 MFS_Scroll_Wheel_Left_Press 4;
BA_ "GenSigSendType" SG_ 1015 MFS_Scroll_Wheel_Right_Press 4;
BA_ "GenSigSendType" SG_ 1015 MFS_Scroll_Wheel_Left_Valid 4;
BA_ "GenSigSendType" SG_ 1015 MFS_Scroll_Wheel_Right_Valid 4;
BA_ "GenSigSendType" SG_ 1015 MFS_Scroll_Wheel_Left_ID 4;
BA_ "GenSigSendType" SG_ 1015 MFS_Scroll_Wheel_Right_ID 4;
BA_ "InvalidValue" SG_ 1027 ALIVE_CVC_MHU_EvSetting "Fh";
BA_ "GenSigStartValue" SG_ 1027 CVC_ChargeSetTargetSOC 80;
BA_ "InvalidValue" SG_ 1027 CVC_ChargeScheduleSet "3h";
BA_ "GenSigStartValue" SG_ 1027 CVC_ChargeScheduleSet 2;
BA_ "GenSigStartValue" SG_ 1027 CVC_ChargingRequest 3;
BA_ "InvalidValue" SG_ 1027 CVC_ChgPort_Open_req "3h";
BA_ "InvalidValue" SG_ 1027 CVC_SET_DrivingModeSwitch "3h";
BA_ "GenSigStartValue" SG_ 1027 CVC_SET_DrivingModeSwitch 3;
BA_ "InvalidValue" SG_ 1027 CVC_ValetMode_Activation "FFh";
BA_ "GenSigStartValue" SG_ 1027 CVC_ValetMode_Activation 2;
BA_ "GenSigStartValue" SG_ 1027 CVC_ValetMode_MaxSpeed 255;
BA_ "GenSigStartValue" SG_ 1027 CVC_ChargingCurrentLimit 6;
BA_ "InvalidValue" SG_ 1031 CVC_Wiper_Front_Status "7h";
BA_ "InvalidValue" SG_ 1031 CVC_Wiper_Rear_Status "3h";
BA_ "InvalidValue" SG_ 1031 CVC_Fr_Rr_WashAndMist_Status "7h";
BA_ "InvalidValue" SG_ 1031 CVC_Rear_Wiper_Park_Pos_Status "3h";
BA_ "GenSigStartValue" SG_ 1031 CVC_Rear_Wiper_Park_Pos_Status 1;
BA_ "InvalidValue" SG_ 1031 CVC_Front_Wiper_Park_Pos_Status "3h";
BA_ "GenSigStartValue" SG_ 1031 CVC_Front_Wiper_Park_Pos_Status 1;
BA_ "InvalidValue" SG_ 1037 ALIVE_CVC_DIGIT_SPEED "Fh";
BA_ "GenSigTimeoutTime_ALL" SG_ 1044 CRC_CVC_HOD_Status 2500;
BA_ "InvalidValue" SG_ 1044 ALIVE_CVC_HOD_Status "Fh";
BA_ "GenSigTimeoutTime_ALL" SG_ 1044 ALIVE_CVC_HOD_Status 2500;
BA_ "GenSigTimeoutTime_ALL" SG_ 1044 HOD_Calc_Threshold_CH0 2500;
BA_ "GenSigTimeoutTime_ALL" SG_ 1044 HOD_Calc_Threshold_CH1 2500;
BA_ "GenSigTimeoutTime_ALL" SG_ 1044 HOD_Immag_Impedence_CH0 2500;
BA_ "GenSigTimeoutTime_ALL" SG_ 1044 HOD_Immag_Impedence_CH1 2500;
BA_ "InvalidValue" SG_ 1044 HOD_ERR_STATE "Fh";
BA_ "GenSigTimeoutTime_ALL" SG_ 1044 HOD_ERR_STATE 2500;
BA_ "GenSigTimeoutTime_ALL" SG_ 1044 HOD_RsErr_HOD 2500;
BA_ "InvalidValue" SG_ 1044 HOD_Status "5h";
BA_ "GenSigTimeoutTime_ALL" SG_ 1044 HOD_Status 2500;
BA_ "InvalidValue" SG_ 1052 ALIVE_SCMF_SEAT_POSITION "Fh";
BA_ "InvalidValue" SG_ 1052 SCMF_Seat_track_pos_Dri "3h";
BA_ "InvalidValue" SG_ 1052 SCMF_Seat_track_posPas "3h";
BA_ "InvalidValue" SG_ 1055 ALIVE_OCS_PasSts "Fh";
BA_ "GenSigStartValue" SG_ 1055 OCS_Passenger_class_stat 1;
BA_ "GenSigStartValue" SG_ 1059 AVAS_EnableSts 1;
BA_ "GenSigStartValue" SG_ 1064 TRMFitted 2;
BA_ "InvalidValue" SG_ 1067 ALIVE_SCMF_FR_SEAT_CONTROL "Fh";
BA_ "InvalidValue" SG_ 1067 SCMF_PsSeat_Control_Status "7h";
BA_ "GenSigStartValue" SG_ 1067 SCMF_PsReclinerPos 54;
BA_ "GenSigStartValue" SG_ 1067 SCMF_PsHeightPos 30;
BA_ "GenSigStartValue" SG_ 1067 SCMF_PsTrackPos 40;
BA_ "InvalidValue" SG_ 1067 SCMF_SeatTilt_FRSw "3h";
BA_ "InvalidValue" SG_ 1067 SCMF_SeatHeight_FRSw "3h";
BA_ "InvalidValue" SG_ 1067 SCMF_SeatTrack_FRSw "3h";
BA_ "InvalidValue" SG_ 1068 ALIVE_SCMF_FL_SEAT_CONTROL "Fh";
BA_ "InvalidValue" SG_ 1068 SCMF_D_DrvSeat_Control_Status "7h";
BA_ "GenSigStartValue" SG_ 1068 SCMF_D_DrvReclinerPos 54;
BA_ "GenSigStartValue" SG_ 1068 SCMF_D_DrvHeightPos 30;
BA_ "GenSigStartValue" SG_ 1068 SCMF_D_DrvTrackPos 40;
BA_ "InvalidValue" SG_ 1068 SCMF_SeatRecliner_FLSw "3h";
BA_ "InvalidValue" SG_ 1068 SCMF_SeatTilt_FLSw "3h";
BA_ "InvalidValue" SG_ 1068 SCMF_SeatHeight_FLSw "3h";
BA_ "InvalidValue" SG_ 1068 SCMF_SeatTrack_FLSw "3h";
BA_ "InvalidValue" SG_ 1071 BCMFL_STAT_LeftMirrorHeating "3h";
BA_ "InvalidValue" SG_ 1071 BCMFL_STAT_LeftMirrorFold "3h";
BA_ "InvalidValue" SG_ 1071 BCMFL_STAT_MirrorAdjustLeft "3h";
BA_ "InvalidValue" SG_ 1072 BCMFR_STAT_RightMirrorHeating "3h";
BA_ "InvalidValue" SG_ 1072 BCMFR_STAT_RightMirrorFold "3h";
BA_ "InvalidValue" SG_ 1072 BCMFR_STAT_MirrorAdjustRight "3h";
BA_ "InvalidValue" SG_ 181 ALIVE_BCM_WindowsFR_Status "Fh";
BA_ "InvalidValue" SG_ 181 Window_Position_FR "Fh";
BA_ "InvalidValue" SG_ 181 Window_Position_RR "Fh";
BA_ "GenSigSendType" SG_ 535 BCM_PositionLight_RL_STS 4;
BA_ "GenSigSendType" SG_ 535 BCM_PositionLight_RR_STS 4;
BA_ "GenSigSendType" SG_ 535 BCM_TurnIndicator_RL_STS 4;
BA_ "GenSigSendType" SG_ 535 BCM_TurnIndicator_RR_STS 4;
BA_ "GenSigSendType" SG_ 535 BCM_ReverseLamp_RL_STS 4;
BA_ "GenSigSendType" SG_ 535 BCM_ReverseLamp_RR_STS 4;
BA_ "GenSigSendType" SG_ 535 BCM_BrakeLight_RL_STS 4;
BA_ "GenSigSendType" SG_ 535 BCM_BrakeLight_RR_STS 4;
BA_ "GenSigSendType" SG_ 535 BCM_RearFogLamp_RR_STS 4;
BA_ "GenSigSendType" SG_ 535 BCM_BrakeLight_Center_STS 4;
BA_ "GenSigSendType" SG_ 535 BCM_LicensePlateLamp_RE_STS 4;
BA_ "GenSigSendType" SG_ 535 BCM_RearFogLamp_RL_STS 4;
BA_ "GenSigSendType" SG_ 535 BCM_SignatureRear_STS 4;
BA_ "GenSigSendType" SG_ 535 BCMRE_WelcomeFarewellLight_STS 4;
BA_ "GenSigSendType" SG_ 535 BCM_PositionLight_RM_STS 4;
BA_ "InvalidValue" SG_ 535 BCM_ParkingLight_RL_STS "3h";
BA_ "GenSigSendType" SG_ 535 BCM_ParkingLight_RL_STS 4;
BA_ "InvalidValue" SG_ 535 BCM_ParkingLight_RM_STS "3h";
BA_ "GenSigSendType" SG_ 535 BCM_ParkingLight_RM_STS 4;
BA_ "InvalidValue" SG_ 535 BCM_ParkingLight_RR_STS "3h";
BA_ "GenSigSendType" SG_ 535 BCM_ParkingLight_RR_STS 4;
BA_ "InvalidValue" SG_ 1079 ALIVE_CVC_MHU_info_2 "Fh";
BA_ "InvalidValue" SG_ 1079 CVC_DCM_Status "0h";
BA_ "InvalidValue" SG_ 1082 ALIVE_CVC_MHU_info "Fh";
BA_ "GenSigStartValue" SG_ 1082 CVC_PowerRegenGaugeDisplay 100;
BA_ "GenSigStartValue" SG_ 1082 CVC_Regen_available 1;
BA_ "InvalidValue" SG_ 1082 CVC_StoppingMode_stt "7h";
BA_ "InvalidValue" SG_ 1082 CVC_AutoP_Feedback "3h";
BA_ "InvalidValue" SG_ 1082 CVC_HDC_Status "7h";
BA_ "GenSigTimeoutTime_ALL" SG_ 1082 CVC_HDC_Status 1000;
BA_ "InvalidValue" SG_ 1084 ALIVE_SCMF_Info1 "Fh";
BA_ "GenSigStartValue" SG_ 1084 RMrrStFlg 1;
BA_ "InvalidValue" SG_ 1085 ALIVE_SCMF_Info3 "Fh";
BA_ "GenSigStartValue" SG_ 1085 DrStHtRunSt_sec 1;
BA_ "GenSigStartValue" SG_ 1085 PStHtRunSt_sec 1;
BA_ "GenSigStartValue" SG_ 1085 DrStVtRunSt_sec 1;
BA_ "GenSigStartValue" SG_ 1085 PStVtRunSt_sec 1;
BA_ "InvalidValue" SG_ 1086 ALIVE_SCMF_Info4 "Fh";
BA_ "GenSigStartValue" SG_ 1086 DrStHtRunSt_3rd 1;
BA_ "GenSigStartValue" SG_ 1086 PStHtRunSt_3rd 1;
BA_ "InvalidValue" SG_ 1090 WLC_Setting_standard "3h";
BA_ "GenSigStartValue" SG_ 1090 WLC_Setting_standard 2;
BA_ "InvalidValue" SG_ 1090 Transmit_WLC_situation "7h";
BA_ "InvalidValue" SG_ 1090 WLC_Phoneforgetalert_state "3h";
BA_ "InvalidValue" SG_ 1093 RS_Sol_L "FFh";
BA_ "InvalidValue" SG_ 1093 RS_Sol_R "FFh";
BA_ "InvalidValue" SG_ 1093 RS_St_LampReq "3h";
BA_ "InvalidValue" SG_ 1093 RS_St_CurrentRain "7h";
BA_ "InvalidValue" SG_ 1093 RS_HUD_illuminance "FFFFh";
BA_ "InvalidValue" SG_ 529 ALIVE_BCMFL_ExteriorLight_STS "Fh";
BA_ "InvalidValue" SG_ 529 BCM_LowBeam_FL_Sts "3h";
BA_ "GenSigSendType" SG_ 529 BCM_LowBeam_FL_Sts 2;
BA_ "InvalidValue" SG_ 529 BCM_HighBeam_FL_Sts "3h";
BA_ "GenSigSendType" SG_ 529 BCM_HighBeam_FL_Sts 2;
BA_ "InvalidValue" SG_ 529 BCM_TurnIndicator_FL_STS "3h";
BA_ "GenSigSendType" SG_ 529 BCM_TurnIndicator_FL_STS 2;
BA_ "InvalidValue" SG_ 529 BCM_PositionLight_FL_STS "3h";
BA_ "GenSigSendType" SG_ 529 BCM_PositionLight_FL_STS 2;
BA_ "InvalidValue" SG_ 529 BCM_RearFogLamp_FL_STS "3h";
BA_ "GenSigSendType" SG_ 529 BCM_RearFogLamp_FL_STS 2;
BA_ "GenSigSendType" SG_ 529 BCM_HeightSensorSTS_Front 2;
BA_ "GenSigSendType" SG_ 529 BCM_HeightSensorValue_Front 2;
BA_ "InvalidValue" SG_ 529 BCM_MirrorLED_FL_STS "3h";
BA_ "GenSigSendType" SG_ 529 BCM_MirrorLED_FL_STS 2;
BA_ "InvalidValue" SG_ 529 BCM_HazardButton_FL_STS "3h";
BA_ "GenSigSendType" SG_ 529 BCM_HazardButton_FL_STS 2;
BA_ "InvalidValue" SG_ 529 BCM_DaytimeRunningLight_FL_Sts "3h";
BA_ "GenSigSendType" SG_ 529 BCM_DaytimeRunningLight_FL_Sts 2;
BA_ "InvalidValue" SG_ 529 BCM_FrontFogLamp_FL_STS "3h";
BA_ "GenSigSendType" SG_ 529 BCM_FrontFogLamp_FL_STS 2;
BA_ "GenSigStartValue" SG_ 1100 PsStHtRunSt 1;
BA_ "GenSigStartValue" SG_ 1100 DrStHtRunSt 1;
BA_ "GenSigStartValue" SG_ 1100 PsStVtRunSt 1;
BA_ "GenSigStartValue" SG_ 1100 DrStVtRunSt 1;
BA_ "InvalidValue" SG_ 1110 OP_WISW_SZL_LIN "FFh";
BA_ "GenSigSendType" SG_ 1110 OP_WISW_SZL_LIN 1;
BA_ "GenSigSendType" SG_ 1110 COMM_ERR_SZL_LIN 1;
BA_ "InvalidValue" SG_ 1110 BCM_Wiper_Front_Status "7h";
BA_ "GenSigSendType" SG_ 1110 BCM_Wiper_Front_Status 1;
BA_ "InvalidValue" SG_ 1110 OP_WIPO_SZL_LIN "7h";
BA_ "GenSigSendType" SG_ 1110 OP_WIPO_SZL_LIN 1;
BA_ "InvalidValue" SG_ 1110 OP_COLS_SZL_LIN "FFh";
BA_ "GenSigSendType" SG_ 1110 OP_COLS_SZL_LIN 1;
BA_ "InvalidValue" SG_ 1110 NOD_ERR_SZL_LIN "3h";
BA_ "GenSigSendType" SG_ 1110 NOD_ERR_SZL_LIN 1;
BA_ "InvalidValue" SG_ 1110 BCM_Wiper_Rear_Status "3h";
BA_ "GenSigSendType" SG_ 1110 BCM_Wiper_Rear_Status 1;
BA_ "GenSigSendType" SG_ 1110 ALIV_WISW_SZL_LIN 1;
BA_ "InvalidValue" SG_ 1152 ALIVE_SCMF_WarnMsg "Fh";
BA_ "GenSigStartValue" SG_ 1155 TPMS_TireTemp 68;
BA_ "InvalidValue" SG_ 1158 ALIVE_TPMS_TirePressure2 "Fh";
BA_ "InvalidValue" SG_ 1160 ALIVE_ACU_WarnMsg "Fh";
BA_ "InvalidValue" SG_ 1160 ACU_PAB_Suppression "3h";
BA_ "InvalidValue" SG_ 1166 ALIVE_ETG_WarnMsg "Fh";
BA_ "InvalidValue" SG_ 1171 ALIVE_BMS_WarnMsg "Fh";
BA_ "InvalidValue" SG_ 1171 BMS_Warning_DeltaTemperature "FFh";
BA_ "InvalidValue" SG_ 1171 BMS_Warning_BDUTemperatureSts "FFh";
VAL_ 854 CVC_ADAS_HWA_SOTA 0 "Feature SOTA NOT supported" 1 "Feature NOT Supported" 2 "Features Disable" 3 "Features Enable" 4 "Reserve" 5 "Reserve" 6 "Reserve" 7 "Invalid" ;
VAL_ 854 CVC_ADAS_AESA_SOTA 0 "Feature SOTA NOT supported" 1 "Feature NOT Supported" 2 "Features Disable" 3 "Features Enable" 4 "Reserve" 5 "Reserve" 6 "Reserve" 7 "Invalid" ;
VAL_ 854 CVC_ADAS_ALCA_SOTA 0 "Feature SOTA NOT supported" 1 "Feature NOT Supported" 2 "Features Disable" 3 "Features Enable" 4 "Reserve" 5 "Reserve" 6 "Reserve" 7 "Invalid" ;
VAL_ 854 CVC_ADAS_BasicCruise_SOTA 0 "Feature SOTA NOT supported" 1 "Feature NOT Supported" 2 "Features Disable" 3 "Features Enable" 4 "Reserve" 5 "Reserve" 6 "Reserve" 7 "Invalid" ;
VAL_ 854 CVC_ADAS_ACC_SOTA 0 "Feature SOTA NOT supported" 1 "Feature NOT Supported" 2 "Features Disable" 3 "Features Enable" 4 "Reserve" 5 "Reserve" 6 "Reserve" 7 "Invalid" ;
VAL_ 854 CVC_ADAS_TSR_SOTA 0 "Feature SOTA NOT supported" 1 "Feature NOT Supported" 2 "Features Disable" 3 "Features Enable" 4 "Reserve" 5 "Reserve" 6 "Reserve" 7 "Invalid" ;
VAL_ 854 CVC_ADAS_ISA_SOTA 0 "Feature SOTA NOT supported" 1 "Feature NOT Supported" 2 "Features Disable" 3 "Features Enable" 4 "Reserve" 5 "Reserve" 6 "Reserve" 7 "Invalid" ;
VAL_ 854 CVC_ADAS_NOP_SOTA 0 "Feature SOTA NOT supported" 1 "Feature NOT Supported" 2 "Features Disable" 3 "Features Enable" 4 "Reserve" 5 "Reserve" 6 "Reserve" 7 "Invalid" ;
VAL_ 854 CVC_ADAS_AAESA_SOTA 0 "Feature SOTA NOT supported" 1 "Feature NOT Supported" 2 "Features Disable" 3 "Features Enable" 4 "Reserve" 5 "Reserve" 6 "Reserve" 7 "Invalid" ;
VAL_ 854 CVC_ADAS_ALCM_SOTA 0 "Feature SOTA NOT supported" 1 "Feature NOT Supported" 2 "Features Disable" 3 "Features Enable" 4 "Reserve" 5 "Reserve" 6 "Reserve" 7 "Invalid" ;
VAL_ 854 CVC_ADAS_AACC_SOTA 0 "Feature SOTA NOT supported" 1 "Feature NOT Supported" 2 "Features Disable" 3 "Features Enable" 4 "Reserve" 5 "Reserve" 6 "Reserve" 7 "Invalid" ;
VAL_ 854 CVC_ADAS_TLD_SOTA 0 "Feature SOTA NOT supported" 1 "Feature NOT Supported" 2 "Features Disable" 3 "Features Enable" 4 "Reserve" 5 "Reserve" 6 "Reserve" 7 "Invalid" ;
VAL_ 854 CVC_ADAS_DNS_SOTA 0 "Feature SOTA NOT supported" 1 "Feature NOT Supported" 2 "Features Disable" 3 "Features Enable" 4 "Reserve" 5 "Reserve" 6 "Reserve" 7 "Invalid" ;
VAL_ 854 CVC_ADAS_LDW_SOTA 0 "Feature SOTA NOT supported" 1 "Feature NOT Supported" 2 "Features Disable" 3 "Features Enable" 4 "Reserve" 5 "Reserve" 6 "Reserve" 7 "Invalid" ;
VAL_ 854 CVC_ADAS_LKA_SOTA 0 "Feature SOTA NOT supported" 1 "Feature NOT Supported" 2 "Features Disable" 3 "Features Enable" 4 "Reserve" 5 "Reserve" 6 "Reserve" 7 "Invalid" ;
VAL_ 854 CVC_ADAS_ELK_SOTA 0 "Feature SOTA NOT supported" 1 "Feature NOT Supported" 2 "Features Disable" 3 "Features Enable" 4 "Reserve" 5 "Reserve" 6 "Reserve" 7 "Invalid" ;
VAL_ 854 CVC_ADAS_FAEB_SOTA 0 "Feature SOTA NOT supported" 1 "Feature NOT Supported" 2 "Features Disable" 3 "Features Enable" 4 "Reserve" 5 "Reserve" 6 "Reserve" 7 "Invalid" ;
VAL_ 854 CVC_ADAS_ESA_SOTA 0 "Feature SOTA NOT supported" 1 "Feature NOT Supported" 2 "Features Disable" 3 "Features Enable" 4 "Reserve" 5 "Reserve" 6 "Reserve" 7 "Invalid" ;
VAL_ 854 CVC_ADAS_RAEB_SOTA 0 "Feature SOTA NOT supported" 1 "Feature NOT Supported" 2 "Features Disable" 3 "Features Enable" 4 "Reserve" 5 "Reserve" 6 "Reserve" 7 "Invalid" ;
VAL_ 854 CVC_ADAS_FCW_SOTA 0 "Feature SOTA NOT supported" 1 "Feature NOT Supported" 2 "Features Disable" 3 "Features Enable" 4 "Reserve" 5 "Reserve" 6 "Reserve" 7 "Invalid" ;
VAL_ 854 CVC_ADAS_RCTA_SOTA 0 "Feature SOTA NOT supported" 1 "Feature NOT Supported" 2 "Features Disable" 3 "Features Enable" 4 "Reserve" 5 "Reserve" 6 "Reserve" 7 "Invalid" ;
VAL_ 854 CVC_ADAS_BSD_SOTA 0 "Feature SOTA NOT supported" 1 "Feature NOT Supported" 2 "Features Disable" 3 "Features Enable" 4 "Reserve" 5 "Reserve" 6 "Reserve" 7 "Invalid" ;
VAL_ 854 CVC_ADAS_DOW_SOTA 0 "Feature SOTA NOT supported" 1 "Feature NOT Supported" 2 "Features Disable" 3 "Features Enable" 4 "Reserve" 5 "Reserve" 6 "Reserve" 7 "Invalid" ;
VAL_ 854 CVC_ADAS_IA_SOTA 0 "Feature SOTA NOT supported" 1 "Feature NOT Supported" 2 "Features Disable" 3 "Features Enable" 4 "Reserve" 5 "Reserve" 6 "Reserve" 7 "Invalid" ;
VAL_ 854 CVC_ADAS_SVM_SOTA 0 "Feature SOTA NOT supported" 1 "Feature NOT Supported" 2 "Features Disable" 3 "Features Enable" 4 "Reserve" 5 "Reserve" 6 "Reserve" 7 "Invalid" ;
VAL_ 854 CVC_ADAS_RVC_SOTA 0 "Feature SOTA NOT supported" 1 "Feature NOT Supported" 2 "Features Disable" 3 "Features Enable" 4 "Reserve" 5 "Reserve" 6 "Reserve" 7 "Invalid" ;
VAL_ 854 CVC_ADAS_FPA_SOTA 0 "Feature SOTA NOT supported" 1 "Feature NOT Supported" 2 "Features Disable" 3 "Features Enable" 4 "Reserve" 5 "Reserve" 6 "Reserve" 7 "Invalid" ;
VAL_ 854 CVC_ADAS_RPA_SOTA 0 "Feature SOTA NOT supported" 1 "Feature NOT Supported" 2 "Features Disable" 3 "Features Enable" 4 "Reserve" 5 "Reserve" 6 "Reserve" 7 "Invalid" ;
VAL_ 854 CVC_ADAS_SpaFAPA_SOTA 0 "Feature SOTA NOT supported" 1 "Feature NOT Supported" 2 "Features Disable" 3 "Features Enable" 4 "Reserve" 5 "Reserve" 6 "Reserve" 7 "Invalid" ;
VAL_ 854 CVC_ADAS_RP_SOTA 0 "Feature SOTA NOT supported" 1 "Feature NOT Supported" 2 "Features Disable" 3 "Features Enable" 4 "Reserve" 5 "Reserve" 6 "Reserve" 7 "Invalid" ;
VAL_ 854 CVC_ADAS_VParkingSelect_SOTA 0 "Feature SOTA NOT supported" 1 "Feature NOT Supported" 2 "Features Disable" 3 "Features Enable" 4 "Reserve" 5 "Reserve" 6 "Reserve" 7 "Invalid" ;
VAL_ 854 CVC_ADAS_VParkingComfort_SOTA 0 "Feature SOTA NOT supported" 1 "Feature NOT Supported" 2 "Features Disable" 3 "Features Enable" 4 "Reserve" 5 "Reserve" 6 "Reserve" 7 "Invalid" ;
VAL_ 854 CVC_ADAS_VParkingSummon_SOTA 0 "Feature SOTA NOT supported" 1 "Feature NOT Supported" 2 "Features Disable" 3 "Features Enable" 4 "Reserve" 5 "Reserve" 6 "Reserve" 7 "Invalid" ;
VAL_ 854 CVC_ADAS_VParkingAutoRev_SOTA 0 "Feature SOTA NOT supported" 1 "Feature NOT Supported" 2 "Features Disable" 3 "Features Enable" 4 "Reserve" 5 "Reserve" 6 "Reserve" 7 "Invalid" ;
VAL_ 854 CVC_ADAS_AHB_SOTA 0 "Feature SOTA NOT supported" 1 "Feature NOT Supported" 2 "Features Disable" 3 "Features Enable" 4 "Reserve" 5 "Reserve" 6 "Reserve" 7 "Invalid" ;
VAL_ 854 CVC_ADAS_ADB_SOTA 0 "Feature SOTA NOT supported" 1 "Feature NOT Supported" 2 "Features Disable" 3 "Features Enable" 4 "Reserve" 5 "Reserve" 6 "Reserve" 7 "Invalid" ;
VAL_ 854 CVC_ADAS_DMS_SOTA 0 "Feature SOTA NOT supported" 1 "Feature NOT Supported" 2 "Features Disable" 3 "Features Enable" 4 "Reserve" 5 "Reserve" 6 "Reserve" 7 "Invalid" ;
VAL_ 854 CVC_ADAS_DMSFaceID_SOTA 0 "Feature SOTA NOT supported" 1 "Feature NOT Supported" 2 "Features Disable" 3 "Features Enable" 4 "Reserve" 5 "Reserve" 6 "Reserve" 7 "Invalid" ;
VAL_ 854 CVC_ADAS_DCM_SOTA 0 "Feature SOTA NOT supported" 1 "Feature NOT Supported" 2 "Features Disable" 3 "Features Enable" 4 "Reserve" 5 "Reserve" 6 "Reserve" 7 "Invalid" ;
VAL_ 854 CVC_ADAS_AdasEDR_SOTA 0 "Feature SOTA NOT supported" 1 "Feature NOT Supported" 2 "Features Disable" 3 "Features Enable" 4 "Reserve" 5 "Reserve" 6 "Reserve" 7 "Invalid" ;
VAL_ 854 CVC_ADAS_ACPE_SOTA 0 "Feature SOTA NOT supported" 1 "Feature NOT Supported" 2 "Features Disable" 3 "Features Enable" 4 "Reserve" 5 "Reserve" 6 "Reserve" 7 "Invalid" ;
VAL_ 854 CVC_ADAS_SentryMode_SOTA 0 "Feature SOTA NOT supported" 1 "Feature NOT Supported" 2 "Features Disable" 3 "Features Enable" 4 "Reserve" 5 "Reserve" 6 "Reserve" 7 "Invalid" ;
VAL_ 862 CVC_VehLock_STS 0 "Locked" 1 "Unlocked" ;
VAL_ 862 CVC_VehChgAllow 0 "Forbid charging" 1 "Not allow, waiting" 2 "Allow charging" 3 "Invalid" ;
VAL_ 862 CVC_VehDischgAllow 0 "Forbid discharging" 1 "Shutdown" 2 "Allow discharging" 3 "Invalid" ;
VAL_ 862 Re_InitCharging_Req 0 "Forbid" 1 "Allow" 2 "Reserved" 3 "Invalid" ;
VAL_ 862 CVC_StopChg_Req 0 "No request" 1 "Request" ;
VAL_ 862 CVC_GunUnlock_Req 0 "No action" 1 "Lock" 2 "Unlock" 3 "Invalid" ;
VAL_ 862 CVC_AntiTheft_Status 0 "Secured" 1 "Unsecured" 2 "Alarm" 3 "Partly secured" 4 "Reserved" 5 "Reserved" 6 "Reserved" 7 "Signal invalid" ;
VAL_ 863 Ack_SchdlChg 0 "Schedule charging disabled" 1 "Schedule charging enabled" 2 "Reserved" 3 "Invalid" ;
VAL_ 866 WCBS_RBC_STS 0 "inactive" 1 "active" ;
VAL_ 866 WCBS_RegenMonFail 0 "Normal" 1 "Fail" ;
VAL_ 866 WCBS_TorqReqMode 0 "Normal mode" 1 "TCS mode" 2 "Regen mode" 3 "Reserved" ;
VAL_ 866 WCBS_F_RegenTarTrqValid 0 "Invalid" 1 "valid" ;
VAL_ 866 WCBS_R_RegenTarTrqValid 0 "Invalid" 1 "valid" ;
VAL_ 872 FMCU_PhaseOverCurrentSWFault 0 "Normal" 1 "Error" ;
VAL_ 872 FMCU_MCUOverTempFault 0 "Normal" 1 "Error" ;
VAL_ 872 FMCU_MCUOverTempAlarm 0 "Normal" 1 "Error" ;
VAL_ 872 FMCU_MotOverTemp2Fault 0 "Normal" 1 "Error" ;
VAL_ 872 FMCU_MotTempSenFault 0 "Normal" 1 "Error" ;
VAL_ 872 FMCU_MotOverTemp1Fault 0 "Normal" 1 "Error" ;
VAL_ 872 FMCU_MotOverTempAlarm 0 "Normal" 1 "Error" ;
VAL_ 872 FMCU_MCUHVUnderVoltageFault 0 "Normal" 1 "Error" ;
VAL_ 872 FMCU_MCUHVUnderVoltageAlarm 0 "Normal" 1 "Error" ;
VAL_ 872 FMCU_MCUHVOverVoltageFault 0 "Normal" 1 "Error" ;
VAL_ 872 FMCU_MCUHVOverVoltageAlarm 0 "Normal" 1 "Error" ;
VAL_ 872 FMCU_MCUCurrentSenWFault 0 "Normal" 1 "Error" ;
VAL_ 872 FMCU_MCUCurrentSenVFault 0 "Normal" 1 "Error" ;
VAL_ 872 FMCU_MCUCurrentSenUFault 0 "Normal" 1 "Error" ;
VAL_ 872 FMCU_PhaseOverCurrentHWFault 0 "Normal" 1 "Error" ;
VAL_ 872 FMCU_MotOverFault 0 "Normal" 1 "Error" ;
VAL_ 872 FMCU_MotOverAlarm 0 "Normal" 1 "Error" ;
VAL_ 872 FMCU_12VUnderVoltageAlarm 0 "Normal" 1 "Error" ;
VAL_ 872 FMCU_12VOverVoltageAlarm 0 "Normal" 1 "Error" ;
VAL_ 872 FMCU_MCUHVSensorFault 0 "Normal" 1 "Error" ;
VAL_ 872 FMCU_MCUDisChgFault 0 "Normal" 1 "Error" ;
VAL_ 872 FMCU_MotBlockedFault 0 "Normal" 1 "Error" ;
VAL_ 872 FMCU_MotRotSenFault 0 "Normal" 1 "Error" ;
VAL_ 872 FMCU_BMSLostFault 0 "Normal" 1 "Error" ;
VAL_ 872 FMCU_CVCLostFault 0 "Normal" 1 "Error" ;
VAL_ 872 FMCU_CANBusoffFault 0 "Normal" 1 "Error" ;
VAL_ 872 FMCU_IGBTFault 0 "Normal" 1 "Error" ;
VAL_ 872 FMCU_MCUCurrentSenWZeroFault 0 "Normal" 1 "Error" ;
VAL_ 872 FMCU_MCUCurrentSenVZeroFault 0 "Normal" 1 "Error" ;
VAL_ 872 FMCU_MCUCurrentSenUZeroFault 0 "Normal" 1 "Error" ;
VAL_ 872 FMCU_MCUTempSenWFault 0 "Normal" 1 "Error" ;
VAL_ 872 FMCU_MCUTempSenVFault 0 "Normal" 1 "Error" ;
VAL_ 872 FMCU_MCUTempSenUFault 0 "Normal" 1 "Error" ;
VAL_ 872 FMCU_InitMode 0 "Normal" 1 "Error" ;
VAL_ 874 RMCU_PhaseOverCurrentSWFault 0 "Normal" 1 "Error" ;
VAL_ 874 RMCU_MCUOverTempFault 0 "Normal" 1 "Error" ;
VAL_ 874 RMCU_MCUOverTempAlarm 0 "Normal" 1 "Error" ;
VAL_ 874 RMCU_MotOverTemp2Fault 0 "Normal" 1 "Error" ;
VAL_ 874 RMCU_MotTempSenFault 0 "Normal" 1 "Error" ;
VAL_ 874 RMCU_MotOverTemp1Fault 0 "Normal" 1 "Error" ;
VAL_ 874 RMCU_MotOverTempAlarm 0 "Normal" 1 "Error" ;
VAL_ 874 RMCU_MCUHVUnderVoltageFault 0 "Normal" 1 "Error" ;
VAL_ 874 RMCU_MCUHVUnderVoltageAlarm 0 "Normal" 1 "Error" ;
VAL_ 874 RMCU_MCUHVOverVoltageFault 0 "Normal" 1 "Error" ;
VAL_ 874 RMCU_MCUHVOverVoltageAlarm 0 "Normal" 1 "Error" ;
VAL_ 874 RMCU_MCUCurrentSenWFault 0 "Normal" 1 "Error" ;
VAL_ 874 RMCU_MCUCurrentSenVFault 0 "Normal" 1 "Error" ;
VAL_ 874 RMCU_MCUCurrentSenUFault 0 "Normal" 1 "Error" ;
VAL_ 874 RMCU_PhaseOverCurrentHWFault 0 "Normal" 1 "Error" ;
VAL_ 874 RMCU_MotOverFault 0 "Normal" 1 "Error" ;
VAL_ 874 RMCU_MotOverAlarm 0 "Normal" 1 "Error" ;
VAL_ 874 RMCU_12VUnderVoltageAlarm 0 "Normal" 1 "Error" ;
VAL_ 874 RMCU_12VOverVoltageAlarm 0 "Normal" 1 "Error" ;
VAL_ 874 RMCU_MCUHVSensorFault 0 "Normal" 1 "Error" ;
VAL_ 874 RMCU_MCUDisChgFault 0 "Normal" 1 "Error" ;
VAL_ 874 RMCU_MotBlockedFault 0 "Normal" 1 "Error" ;
VAL_ 874 RMCU_MotRotSenFault 0 "Normal" 1 "Error" ;
VAL_ 874 RMCU_BMSLostFault 0 "Normal" 1 "Error" ;
VAL_ 874 RMCU_CVCLostFault 0 "Normal" 1 "Error" ;
VAL_ 874 RMCU_CANBusoffFault 0 "Normal" 1 "Error" ;
VAL_ 874 RMCU_IGBTFault 0 "Normal" 1 "Error" ;
VAL_ 874 RMCU_MCUCurrentSenWZeroFault 0 "Normal" 1 "Error" ;
VAL_ 874 RMCU_MCUCurrentSenVZeroFault 0 "Normal" 1 "Error" ;
VAL_ 874 RMCU_MCUCurrentSenUZeroFault 0 "Normal" 1 "Error" ;
VAL_ 874 RMCU_MCUTempSenWFault 0 "Normal" 1 "Error" ;
VAL_ 874 RMCU_MCUTempSenVFault 0 "Normal" 1 "Error" ;
VAL_ 874 RMCU_MCUTempSenUFault 0 "Normal" 1 "Error" ;
VAL_ 874 RMCU_InitMode 0 "Normal" 1 "Error" ;
VAL_ 880 MNF_ErrSt 0 "No Error" 1 "Error" ;
VAL_ 880 MNF_OverTempWarning 0 "Normal" 1 "Active" ;
VAL_ 880 MNF_DoorOpenWarning1 0 "Inactive" 1 "Active" ;
VAL_ 880 MNF_DoorOpenWarning2 0 "Inactive" 1 "Active" ;
VAL_ 880 MNF_SpecialModeSts 0 "OFF" 1 "Iced" 2 "Preservation" 3 "Warm milk" 4 "Reserved" 5 "Reserved" 6 "Reserved" 7 "Reserved" ;
VAL_ 880 MNF_AutoStartRes 0 "Disable" 1 "Enable" ;
VAL_ 880 MNF_WorkSts 0 "OFF" 1 "Cooling" 2 "Heating" 3 "Reserved" ;
VAL_ 880 MNF_LockRes 0 "Close" 1 "Temperature Lock" 2 "All Function" 3 "Reserved" ;
VAL_ 880 MNF_Door_Lock_Sts 0 "Locked" 1 "Unlocked" ;
VAL_ 880 MNF_AutoCloseRes 0 "Normal" 1 "Low SOC" 2 "OverTemp" 3 "LowEnergyMode" 4 "TransportMode" 5 "HV disconnect" 6 "System Error" 7 "Reserved" ;
VAL_ 881 MNF_ErrInfo 0 "Normal" 1 "Low voltage" 2 "Fan error" 3 "Compressor start error" 4 "Compressor low speed" 5 "Compressor MCU Over Temp" 6 "NTC error(interior)" 7 "NTC error(AMB)" 8 "Defrost heater error" 9 "Communication Error within MCU and panel" 10 "PI heater error" 11 "Compressor low voltage" 12 "E-actuator openload" ;
VAL_ 881 MNF_HVReq 0 "Inactive" 1 "Active" ;
VAL_ 883 CVC_WMCID_IVITheftWarning 0 "OFF" 1 "ON" ;
VAL_ 883 CVC_WMCID_CAppTheftWarning 0 "OFF" 1 "ON" ;
VAL_ 883 CVC_GPSMonitorStatus 0 "OFF" 1 "ON" ;
VAL_ 886 USS_RPA_state 0 "OFF State" 1 "Standby state" 2 "Active State" 3 "Temporary Failed State" 4 "permanent Failed State" 5 "Reserved" 6 "Reserved" 7 "Invalid" ;
VAL_ 886 USS_RPA_AlertRLI 0 "No warning" 1 "Warning level 1" 2 "Warning level 2" 3 "Warning level 3" 4 "Warning level 4" 5 "Warning level 5" 6 "Reserved" 7 "Invalid" ;
VAL_ 886 USS_RPA_AlertRLO 0 "No warning" 1 "Warning level 1" 2 "Warning level 2" 3 "Warning level 3" 4 "Warning level 4" 5 "Warning level 5" 6 "Reserved" 7 "Invalid" ;
VAL_ 886 USS_RPA_AlertRRI 0 "No warning" 1 "Warning level 1" 2 "Warning level 2" 3 "Warning level 3" 4 "Warning level 4" 5 "Warning level 5" 6 "Reserved" 7 "Invalid" ;
VAL_ 886 USS_RPA_AlertRRO 0 "No warning" 1 "Warning level 1" 2 "Warning level 2" 3 "Warning level 3" 4 "Warning level 4" 5 "Warning level 5" 6 "Reserved" 7 "Invalid" ;
VAL_ 886 USS_RPA_SensorRLI 0 "Sensor Normal" 1 "Sensor Unavailable temporarily" 2 "Sensor Fault" 3 "Invalid" ;
VAL_ 886 USS_RPA_SensorRLO 0 "Sensor Normal" 1 "Sensor Unavailable temporarily" 2 "Sensor Fault" 3 "Invalid" ;
VAL_ 886 USS_RPA_SensorRRI 0 "Sensor Normal" 1 "Sensor Unavailable temporarily" 2 "Sensor Fault" 3 "Invalid" ;
VAL_ 886 USS_RPA_SensorRRO 0 "Sensor Normal" 1 "Sensor Unavailable temporarily" 2 "Sensor Fault" 3 "Invalid" ;
VAL_ 887 USS_FPA_state 0 "OFF State" 1 "Standby state" 2 "Active State" 3 "Temporary Failed State" 4 "permanent Failed State" 5 "Reserved" 6 "Reserved" 7 "Invalid" ;
VAL_ 887 USS_FPA_AutoOn_Feed 0 "OFF" 1 "ON" ;
VAL_ 887 USS_FPA_AlertFLI 0 "No warning" 1 "Warning level 1" 2 "Warning level 2" 3 "Warning level 3" 4 "Warning level 4" 5 "Warning level 5" 6 "Reserved" 7 "Invalid" ;
VAL_ 887 USS_FPA_AlertFLO 0 "No warning" 1 "Warning level 1" 2 "Warning level 2" 3 "Warning level 3" 4 "Warning level 4" 5 "Warning level 5" 6 "Reserved" 7 "Invalid" ;
VAL_ 887 USS_FPA_AlertFRI 0 "No warning" 1 "Warning level 1" 2 "Warning level 2" 3 "Warning level 3" 4 "Warning level 4" 5 "Warning level 5" 6 "Reserved" 7 "Invalid" ;
VAL_ 887 USS_FPA_AlertFRO 0 "No warning" 1 "Warning level 1" 2 "Warning level 2" 3 "Warning level 3" 4 "Warning level 4" 5 "Warning level 5" 6 "Reserved" 7 "Invalid" ;
VAL_ 887 USS_FPA_SensorFLI 0 "Sensor Normal" 1 "Sensor Unavailable temporarily" 2 "Sensor Fault" 3 "Invalid" ;
VAL_ 887 USS_FPA_SensorFLO 0 "Sensor Normal" 1 "Sensor Unavailable temporarily" 2 "Sensor Fault" 3 "Invalid" ;
VAL_ 887 USS_FPA_SensorFRI 0 "Sensor Normal" 1 "Sensor Unavailable temporarily" 2 "Sensor Fault" 3 "Invalid" ;
VAL_ 887 USS_FPA_SensorFRO 0 "Sensor Normal" 1 "Sensor Unavailable temporarily" 2 "Sensor Fault" 3 "Invalid" ;
VAL_ 892 EVCC_ChgGun_Sts 0 "Gun not plugged-in" 1 "Gun plugged-in, locked" 2 "Gun plugged-in, released" 3 "Error, cannot lock" 4 "Error, cannot release" 5 "Bad connection" 6 "Reversed" 7 "Invalid" ;
VAL_ 892 EVCC_ChgFlap_Sts 0 "Locked" 1 "Unlocked" 2 "Faults" 3 "Invalid" ;
VAL_ 892 EVCC_ChgType 0 "No charging" 1 "Normal AC charging" 2 "PLC AC charging" 3 "DC charging" 4 "V2L" 5 "Reserved" 6 "Reserved" 7 "Invalid" ;
VAL_ 892 EVCC_VehChg_Sts 0 "Not charging" 1 "Charging in-progress" 2 "Waiting to start charging" 3 "Charging complete" 4 "Charge fault" 5 "Reserved" 6 "Reserved" 7 "Invalid" ;
VAL_ 892 EVCC_ChgAuthen_Sts 0 "Not authenticating" 1 "Authenticating" 2 "Authentication success" 3 "Authentication failed" 4 "Forbidden vehicle" 5 "Reserved" 6 "Reserved" 7 "Invalid" ;
VAL_ 892 EVCC_PaymentType 0 "Init" 1 "EIM" 2 "PnC" 3 "Reserved" 4 "Reserved" 5 "Reserved" 6 "Reserved" 7 "Invalid" ;
VAL_ 892 EVCC_VehChgCompError_Sts 0 "No error" 1 "Error level 1" 2 "Error level 2" 3 "Error level 3" 4 "Error level 4" 5 "Reserved" 6 "Reserved" 7 "Reserved" ;
VAL_ 892 EVCC_S3Button_Sts 0 "Not pressed" 1 "Pressed" 2 "Reserved" 3 "Invalid" ;
VAL_ 897 ACU_Seat_Occupancy_Passenger 0 "Seat_Not_Occupied" 1 "Seat Occupied" 2 "Not_Available" 3 "Failure" ;
VAL_ 897 ACU_Seat_Occupancy_2nd_Row_Dri 0 "Seat_Not_Occupied" 1 "Seat Occupied" 2 "Not_Available" 3 "Failure" ;
VAL_ 897 ACU_Seat_Occupancy_2nd_Row_Pas 0 "Seat_Not_Occupied" 1 "Seat Occupied" 2 "Not_Available" 3 "Failure" ;
VAL_ 897 ACU_Seat_Occupancy_2nd_Row_Mid 0 "Seat_Not_Occupied" 1 "Seat Occupied" 2 "Not_Available" 3 "Failure" ;
VAL_ 897 ACU_Seat_Belt_Status_Passenger 0 "Not_buckled" 1 "Buckled" 2 "Not_Available" 3 "Failure" ;
VAL_ 897 ACU_Seat_Belt_Status_Driver 0 "Not_buckled" 1 "Buckled" 2 "Not_Available" 3 "Failure" ;
VAL_ 897 ACU_Seat_Belt_Status_2nd_Row_Dri 0 "Not_buckled" 1 "Buckled" 2 "Not_Available" 3 "Failure" ;
VAL_ 897 ACU_Seat_Belt_Status_2nd_Row_Mid 0 "Not_buckled" 1 "Buckled" 2 "Not_Available" 3 "Failure" ;
VAL_ 897 ACU_Seat_Belt_Status_2nd_Row_Pas 0 "Not_buckled" 1 "Buckled" 2 "Not_Available" 3 "Failure" ;
VAL_ 897 ACU_Seat_Occupancy_Driver 0 "Seat_Not_Occupied" 1 "Seat Occupied" 2 "Not_Available" 3 "Failure" ;
VAL_ 925 CVC_ADAS_AHB_Sts 0 "OFF State" 1 "HighBeam Passive or Inactive" 2 "HighBeam Active" 3 "Fault" ;
VAL_ 925 CVC_AHB_Override 0 "Not used" 1 "Automatic High Beam request" 2 "AHB Inhibit by Driver" 3 "Invalid" ;
VAL_ 925 CVC_ADAS_AHB_RBPos_Sts 0 "Off or low beam" 1 "high beam" 2 "Reserved" 3 "Reserved" 4 "Reserved" 5 "Reserved" 6 "Reserved" 7 "Reserved" ;
VAL_ 925 CVC_ADAS_AHB_LBPos_Sts 0 "Off or low beam" 1 "high beam" 2 "Reserved" 3 "Reserved" 4 "Reserved" 5 "Reserved" 6 "Reserved" 7 "Reserved" ;
VAL_ 925 CVC_AHB_Icon_Sts 0 "Off" 1 "Gray ICON" 2 "Green ICON" 3 "White ICON" 4 "Yellow ICON" 5 "Red ICON" ;
VAL_ 992 CVC_RunningRange_chrg_estSts 0 "Not ready" 1 "Processing" 2 "Estimated" 3 "Failed" ;
VAL_ 992 CVC_HVbatSoc_charged_estStatus 0 "Not ready" 1 "Processing" 2 "Estimated" 3 "Failed" ;
VAL_ 993 CVC_MHU_Ack_ChgSche_stt 0 "Charging Schedule Enable" 1 "Charging Schedule Disable" 2 "Reserved" 3 "Signal Invalid" ;
VAL_ 993 CVC_ValetMode_sts 0 "Inactive" 1 "Active" 255 "Invalid" ;
VAL_ 993 CVC_DashCam_Info 0 "OFF" 1 "ON" 2 "Standby" 3 "ReceivedSendMode" 4 "Failure" 5 "Reserved" 6 "Reserved" 7 "Reserved" ;
VAL_ 993 CVC_BEDrvInhibit 0 "No effect" 1 "Inhibited" 2 "UnInhibited" ;
VAL_ 358 CVC_DriveModeSts 0 "Invalid" 1 "Comfort Mode" 2 "Eco Mode" 3 "Sport Mode" ;
VAL_ 358 CVC_DriveReady 0 "Not Ready" 1 "Ready" ;
VAL_ 358 CVC_Fault 0 "No fault" 1 "FaultLevel 1" 2 "FaultLevel 2" 3 "Faultlevel3(Error)" ;
VAL_ 358 CVC_VecFltInd 0 "No fault" 1 "Fault" ;
VAL_ 358 CVC_Creep_Sts 0 "Invalid" 1 "Creep disable" 2 "Creep enable" 3 "Creep function fault" ;
VAL_ 358 CVC_CruiseCtrlSts 0 "OFF" 1 "Standby" 2 "Active" 3 "Override" 4 "Fault" 5 "Reserved" 6 "Reserved" ;
VAL_ 358 CVC_StsBrakePedalSwitch 0 "Reserved" 1 "Not pressed" 2 "Pressed" 3 "Invalid" ;
VAL_ 358 CVC_VehicleMode 0 "EV" 1 "REV" 2 "Fuel" ;
VAL_ 358 CVC_CruiseFaultIndication 0 "No Fault" 1 "Pre-Condition not met" 2 "Function fault" ;
VAL_ 358 CVC_FuelDetectionSwitchState 0 "No COM" 1 "Enable" 2 "Close" 3 "Invalid" ;
VAL_ 358 CVC_FuelDetectionState 0 "No COM" 1 "High Idle" 2 "Low Idle" 3 "Invalid" ;
VAL_ 358 CVC_ParkingChargeRequest 0 "No COM" 1 "Enable" 2 "Close" 3 "Invalid" ;
VAL_ 358 CVC_ParkingChargeModeSet 0 "NORequest" 1 "LOW" 2 "MIDDLE" 3 "HIGH" ;
VAL_ 358 LV_EM_Rampup_Req 0 "No Load Management" 1 "DCDC OFF_No_Rampup" 2 "DCDCRampupTimer_Active" ;
VAL_ 358 LV_PowerSupply_Status 0 "No Fault" 1 "Fault" ;
VAL_ 358 LV_EM_OTA_Req 0 "No OTA LM" 1 "OTA LV Rampup" 2 "OTA_LV_LM_TimerExpired" 3 "OTA_LV_LM_DCDCOFF" ;
VAL_ 358 CVC_STAT_AirDistributionModeLH 0 "OFF" 1 "Vent" 2 "Vent LH + Foot LH" 3 "Foot LH" 4 "Foot LH + Defrost" 5 "Defrost" 6 "Defrost + Face" 7 "Tri Level" ;
VAL_ 358 CVC_STAT_AirDistributionModeRH 0 "OFF" 1 "Vent" 2 "Vent RH + Foot RH" 3 "Foot RH" ;
VAL_ 358 CVC_STAT_DriverOnly 0 "OFF" 1 "ON" 2 "Reserved" 3 "Signal Invalid" ;
VAL_ 994 WCBS_LateralACC_Valid 0 "Invalid" 1 "Valid" ;
VAL_ 994 WCBS_LongitudeACC_Valid 0 "Invalid" 1 "Valid" ;
VAL_ 994 WCBS_VehDynYawRate_Valid 0 "Invalid" 1 "Valid" ;
VAL_ 996 IMU_VerticalACC_Valid 0 "Invalid" 1 "Valid" ;
VAL_ 996 IMU_VehDynPitchRate_Valid 0 "Invalid" 1 "Valid" ;
VAL_ 996 IMU_VehDynRollRate_Valid 0 "Invalid" 1 "Valid" ;
VAL_ 997 IMU_VerticalACCRaw_Valid 0 "Invalid" 1 "Valid" ;
VAL_ 997 IMU_VehDynPitchRateRaw_Valid 0 "Invalid" 1 "Valid" ;
VAL_ 997 IMU_VehDynRollRateRaw_Valid 0 "Invalid" 1 "Valid" ;
VAL_ 1004 CVC_PanicEventTrigger 0 "No event" 1 "Panic triggered" ;
VAL_ 1004 CVC_PanicEventSource 0 "Unknown / Reserved" 1 "Mobile App (Digital Key)" 2 "Key Fob" 3 "Vehicle HMI / Interior Button (if any)" ;
VAL_ 1004 CVC_PanicEventStatus 0 "Idle" 1 "Active" 2 "Completed" 3 "Cancelled" ;
VAL_ 1011 CVC_STAT_PaaK_Enable 0 "Disable" 1 "Enable" 2 "Reserved" 3 "Signal Invalid" ;
VAL_ 1011 CVC_STAT_UserSettingApproachUnlo 0 "Disable" 1 "Enable" 2 "Reserved" 3 "Signal Invalid" ;
VAL_ 1011 CVC_STAT_UserSettingWalkawayLock 0 "Disable" 1 "Enable" 2 "Reserved" 3 "Signal Invalid" ;
VAL_ 1011 CVC_STAT_LockUnlockDriveCfg_Phon 0 "Disable" 1 "Enable" 2 "Reserved" 3 "Signal Invalid" ;
VAL_ 1011 CVC_STAT_LockUnlockDriveCfg_NFC_ 0 "Disable" 1 "Enable" 2 "Reserved" 3 "Signal Invalid" ;
VAL_ 1012 DKAnchor_FrontAnchorStatus_A1 0 "No Error" 1 "Error" ;
VAL_ 1012 DKAnchor_LeftAnchorStatus_A2 0 "No Error" 1 "Error" ;
VAL_ 1012 DKAnchor_RightAnchorStatus_A3 0 "No Error" 1 "Error" ;
VAL_ 1012 DKAnchor_RearAnchorStatus_A4 0 "No Error" 1 "Error" ;
VAL_ 1012 DKAnchor_DKCUAnchorStatus_A5 0 "No Error" 1 "Error" ;
VAL_ 1012 DKAnchor_CPDAnchorStatus_A6 0 "No Error" 1 "Error" ;
VAL_ 1012 DKAnchor_ExtNFCStatus_A7 0 "No Fault" 1 "Fault" ;
VAL_ 1012 DKAnchor_IntNFCStatus_A8 0 "No Fault" 1 "Fault" ;
VAL_ 1012 DK_PhoneKeyPanicAlarmAlert 0 "None" 1 "Alert" ;
VAL_ 1012 DK_PhoneKeyBattLowAlert 0 "None" 1 "Low" ;
VAL_ 1012 DK_PhoneKeyIdleStsAlert 0 "Active Use" 1 "No Active Use" ;
VAL_ 1012 DK_VehicleIdleStsAlert 0 "Active Use" 1 "No Active Use" ;
VAL_ 1012 DK_BleOnOffStsAlert 0 "On" 1 "Off" ;
VAL_ 1012 DK_LeftCarAlert 0 "None" 1 "Alert" ;
VAL_ 1012 DK_AuthFailAlert 0 "None" 1 "Fail" ;
VAL_ 1012 DK_PhoneKeyForgotInsideAlert 0 "None" 1 "ForgotInside" ;
VAL_ 1012 DK_PhoneKeyApproachUnlockAlert 0 "Sucessful" 1 "Failed" ;
VAL_ 1012 DK_PhoneKeyCapabilityAlert 0 "UWB and BLE Both" 1 "BLE_Only" ;
VAL_ 1012 DK_PhoneKeyNfcExteriorAuthFailAl 0 "None" 1 "AuthFail" ;
VAL_ 1012 DK_PhoneKeyNfcInteriorAuthFailAl 0 "None" 1 "AuthFail" ;
VAL_ 1012 DK_PhoneKeyTrunkClosingAlert 0 "None" 1 "Alert" ;
VAL_ 1012 DK_PhoneKeyWalkawayLockFailAlert 0 "None" 1 "Alert" ;
VAL_ 1012 DK_PhoneKeyRemoteBLECmdFailAlert 0 "None" 1 "Alert" ;
VAL_ 1014 PhoneKey_Capability_Status 0 "Unknown" 1 "BLE_ONLY" 2 "BLE_PLUS_UWB" ;
VAL_ 1014 Phone_BLEConnectionSts 0 "Lost" 1 "Bad" 2 "Good" 3 "Very Good" ;
VAL_ 1014 Phone_UWBConnectionSts 0 "Lost" 1 "Bad" 2 "Good" 3 "Very Good" ;
VAL_ 1014 Phone_NFCConnectionSts 0 "Lost" 1 "Bad" 2 "Good" 3 "Very Good" ;
VAL_ 1015 MFS_L_Lever_Control 0 "No action" 1 "Short Up" 2 "Long Up" 3 "Short Down" 4 "Long Down" 7 "Signal invalid" ;
VAL_ 1015 MFS_L_LeverButton_Control 0 "Unpressed" 1 "Short Press" 2 "Long Press" 7 "Signal invalid" ;
VAL_ 1015 MFS_L_Failure 0 "No Error" 1 "Error" ;
VAL_ 1015 MFS_L_UpControl 0 "Unpressed" 1 "Short Press" 2 "Long Press" 7 "Signal invalid" ;
VAL_ 1015 MFS_L_DownControl 0 "Unpressed" 1 "Short Press" 2 "Long Press" 7 "Signal invalid" ;
VAL_ 1015 MFS_L_LeftControl 0 "Unpressed" 1 "Short Press" 2 "Long Press" 7 "Signal invalid" ;
VAL_ 1015 MFS_L_RightControl 0 "Unpressed" 1 "Short Press" 2 "Long Press" 7 "Signal invalid" ;
VAL_ 1015 MFS_LIN_error 0 "No Error" 1 "Error" ;
VAL_ 1015 MFS_R_Lever_Control 0 "No action" 1 "Short Up" 2 "Long Up" 3 "Short Down" 4 "Long Down" 7 "Signal invalid" ;
VAL_ 1015 MFS_R_LeverButton_Control 0 "Unpressed" 1 "Short Press" 2 "Long Press" 7 "Signal invalid" ;
VAL_ 1015 MFS_R_Failure 0 "No Error" 1 "Error" ;
VAL_ 1015 MFS_R_UpControl 0 "Unpressed" 1 "Short Press" 2 "Long Press" 7 "Signal invalid" ;
VAL_ 1015 MFS_R_DownControl 0 "Unpressed" 1 "Short Press" 2 "Long Press" 7 "Signal invalid" ;
VAL_ 1015 MFS_R_LeftControl 0 "Unpressed" 1 "Short Press" 2 "Long Press" 7 "Signal invalid" ;
VAL_ 1015 MFS_R_RightControl 0 "Unpressed" 1 "Short Press" 2 "Long Press" 7 "Signal invalid" ;
VAL_ 1015 MFS_Scroll_Wheel_Left_Direction 0 "Neutral" 1 "Scroll Up" 2 "Scroll Down" 3 "Reserve" ;
VAL_ 1015 MFS_Scroll_Wheel_Right_Direction 0 "Neutral" 1 "Scroll Up" 2 "Scroll Down" 3 "Reserve" ;
VAL_ 1015 MFS_Scroll_Wheel_Left_Press 0 "No Request" 1 "Short Press" 2 "Long Press" 3 "Reserve" ;
VAL_ 1015 MFS_Scroll_Wheel_Right_Press 0 "No Request" 1 "Short Press" 2 "Long Press" 3 "Reserve" ;
VAL_ 1015 MFS_Scroll_Wheel_Left_Valid 0 "Valid" 1 "Invalid" ;
VAL_ 1015 MFS_Scroll_Wheel_Right_Valid 0 "Valid" 1 "Invalid" ;
VAL_ 1027 MHU_CVC_CreepDisable_stt 0 "No request" 1 "Creep Disable request" ;
VAL_ 1027 CVC_BrakeRegenMode 0 "HIGH" 1 "MID" 2 "LOW" 3 "OFF" ;
VAL_ 1027 CVC_ChargeScheduleSet 0 "disable" 1 "Enable" 2 "No effect" 3 "Invalid" ;
VAL_ 1027 CVC_ChargingRequest 0 "Stop charging" 1 "Start charging" 2 "Pause charging" 3 "No effect" ;
VAL_ 1027 CVC_ChgPort_Open_req 0 "No request" 1 "Requesting" 2 "Reserved" 3 "Signal invalid" ;
VAL_ 1027 CVC_SET_DrivingModeSwitch 0 "NORMAL" 1 "ECO" 2 "SPORT" 3 "Signal invalid" ;
VAL_ 1027 CVC_ValetMode_Activation 0 "Inactive" 1 "Active" 2 "No effect" 255 "Invalid" ;
VAL_ 1027 CVC_PreheatBatt_Req 0 "Off" 1 "On" 2 "No action" ;
VAL_ 1031 CVC_RearWiperAutoMode 0 "OFF" 1 "ON" 2 "Reserved" 3 "Reserved" ;
VAL_ 1031 CVC_Wiper_Front_Status 0 "OFF" 1 "Mist" 2 "Intermittent Auto" 3 "Low speed" 4 "High speed" 5 "Reserved" 6 "Reserved" 7 "Invalid" ;
VAL_ 1031 CVC_Wiper_Rear_Status 0 "OFF" 1 "ON" 2 "Mist" 3 "Invalid" ;
VAL_ 1031 CVC_WasherPumpSts 0 "OFF" 1 "Front spraying" 2 "Rear spraying" 3 "Fault" ;
VAL_ 1031 CVC_Fr_Rr_WashAndMist_Status 0 "No Request" 1 "Front MIST" 2 "Front Wash and Wipe" 3 "Rear MIST" 4 "Rear Wash and Wipe" 5 "Reserved" 6 "Reserved" 7 "Invalid" ;
VAL_ 1031 CVC_Rear_Wiper_Park_Pos_Status 0 "Rear wiper not in Parking position" 1 "Rear wiper in Parking position" 2 "Rear wiper motor stalling" 3 "Invalid" ;
VAL_ 1031 CVC_Front_Wiper_Park_Pos_Status 0 "Front wiper not in Parking position" 1 "Front wiper in Parking position" 2 "Front wiper motor stalling" 3 "Invalid" ;
VAL_ 1044 HOD_ERR_STATE 0 "NO_ERROR" 1 "HOD_EEPROM_ERROR" 2 "HOD_ROM_ERROR" 3 "HOD_WATCHDOG_ERROR" 4 "HOD_CPU_ERROR" 5 "HOD_GUARD_INTERRUPTION_ERROR" 6 "HOD_SENSE_INTERRUPTION_ERROR" 7 "HOD_CPU_DEFECT_OR_MAT_SHORTAGE" 8 "UNDERVOLTAGE_ERROR" 9 "OVERVOLTAGE_ERROR" 10 "HOD_CODING_ERROR" 11 "HOD_GENERIC_SYSTEM_ERROR" 15 "Not Available" ;
VAL_ 1044 HOD_RsErr_HOD 0 "No_error" 1 "error" ;
VAL_ 1044 HOD_Status 0 "Init" 1 "Hands OFF" 2 "Hands ON" 3 "Energie_Save_Mode" 4 "HOD error" 5 "Invalid value" 6 "Reserved" 7 "Reserved" 8 "Reserved" 9 "Reserved" 10 "Reserved" 11 "Reserved" 12 "Reserved" 13 "Reserved" 14 "Reserved" 15 "Reserved" ;
VAL_ 1052 SCMF_Seat_track_pos_Dri 0 "Front position" 1 "Not Front position" 2 "Failure" 3 "Invalid Value" ;
VAL_ 1052 SCMF_Seat_track_posPas 0 "Front position" 1 "Not Front position" 2 "Failure" 3 "Invalid Value" ;
VAL_ 1055 OCS_Passenger_class_stat 0 "Seat Empty or Childseat (Class1)" 1 "Adult (Class2)" 2 "OSC Failure" ;
VAL_ 1059 AVAS_BatteryUnderVoltage 0 "Normal" 1 "Failure" ;
VAL_ 1059 AVAS_BatteryOverVoltage 0 "Normal" 1 "Failure" ;
VAL_ 1059 AVAS_VINInfoNotPrgm 0 "Normal" 1 "Failure" ;
VAL_ 1059 AVAS_AMPVoltSplDrvOperationFail 0 "Normal" 1 "Failure" ;
VAL_ 1059 AVAS_AMPIntFaultOverCurr 0 "Normal" 1 "Failure" ;
VAL_ 1059 AVAS_AMPInternalFaultDCError 0 "Normal" 1 "Failure" ;
VAL_ 1059 AVAS_AMPInternalFaultOverTemp 0 "Normal" 1 "Failure" ;
VAL_ 1059 AVAS_AMPInternalFaultClockError 0 "Normal" 1 "Failure" ;
VAL_ 1059 AVAS_SpkrMntPwrSwDrvHighFlt 0 "Normal" 1 "Failure" ;
VAL_ 1059 AVAS_SpkrMntPwrSwDrvLowFlt 0 "Normal" 1 "Failure" ;
VAL_ 1059 AVAS_InternalSpeakerOpen 0 "Normal" 1 "Failure" ;
VAL_ 1059 AVAS_ECUMalFlshOperationErr 0 "Normal" 1 "Failure" ;
VAL_ 1059 AVAS_ECUMalfunctionRamFailure 0 "Normal" 1 "Failure" ;
VAL_ 1059 AVAS_ECUMalEEPROMFailure 0 "Normal" 1 "Failure" ;
VAL_ 1059 AVAS_CANBusOff 0 "Normal" 1 "Failure" ;
VAL_ 1059 AVAS_LossCommVehicleSpeed 0 "Normal" 1 "Failure" ;
VAL_ 1059 AVAS_LossCommGearPosition 0 "Normal" 1 "Failure" ;
VAL_ 1059 AVAS_LossCommAVASCloseCmd 0 "Normal" 1 "Failure" ;
VAL_ 1059 AVAS_EnableSts 0 "Enable" 1 "Disable" ;
VAL_ 1064 TRMFitted 0 "Unsupported" 1 "Fitted" 2 "Not Fitted" 3 "SNA" ;
VAL_ 1067 SCMF_PsSeat_Control_Status 0 "Idle" 1 "Moving by CVC" 2 "Moving by switch" 3 "Failure" 4 "Reserved" 5 "Reserved" 6 "Reserved" 7 "Invalid" ;
VAL_ 1067 SCMF_SeatRecliner_FRSw 0 "No action" 1 "Forward request" 2 "Backward request" 3 "Invalid Value" ;
VAL_ 1067 SCMF_SeatTilt_FRSw 0 "No action" 1 "Angle up request" 2 "Angle down request" 3 "Invalid Value" ;
VAL_ 1067 SCMF_SeatHeight_FRSw 0 "No action" 1 "Up request" 2 "Down request" 3 "Invalid Value" ;
VAL_ 1067 SCMF_SeatTrack_FRSw 0 "No action" 1 "Forward request" 2 "Backward request" 3 "Invalid Value" ;
VAL_ 1068 SCMF_D_DrvSeat_Control_Status 0 "Idle" 1 "Moving by CVC" 2 "Moving by switch" 3 "Failure" 4 "Reserved" 5 "Reserved" 6 "Reserved" 7 "Invalid" ;
VAL_ 1068 SCMF_SeatRecliner_FLSw 0 "No action" 1 "Forward request" 2 "Backward request" 3 "Invalid Value" ;
VAL_ 1068 SCMF_SeatTilt_FLSw 0 "No action" 1 "Angle up request" 2 "Angle down request" 3 "Invalid Value" ;
VAL_ 1068 SCMF_SeatHeight_FLSw 0 "No action" 1 "Up request" 2 "Down request" 3 "Invalid Value" ;
VAL_ 1068 SCMF_SeatTrack_FLSw 0 "No action" 1 "Forward request" 2 "Backward request" 3 "Invalid Value" ;
VAL_ 1071 BCMFL_STAT_LeftMirrorHeating 0 "OFF" 1 "ON" 2 "Fault" 3 "Signal Invalid" ;
VAL_ 1071 BCMFL_STAT_LeftMirrorFold 0 "Fold" 1 "Unfold" 2 "Fault" 3 "Signal Invalid" ;
VAL_ 1071 BCMFL_STAT_MirrorAdjustLeft 0 "OFF" 1 "ON" 2 "Fault" 3 "Signal Invalid" ;
VAL_ 1072 BCMFR_STAT_RightMirrorHeating 0 "OFF" 1 "ON" 2 "Fault" 3 "Signal Invalid" ;
VAL_ 1072 BCMFR_STAT_RightMirrorFold 0 "Fold" 1 "Unfold" 2 "Fault" 3 "Signal Invalid" ;
VAL_ 1072 BCMFR_STAT_MirrorAdjustRight 0 "OFF" 1 "ON" 2 "Fault" 3 "Signal Invalid" ;
VAL_ 181 BCMFR_WindowsFR_AntiPinch_Warn 0 "No error" 1 "Anti-pinch FR window" 2 "Error" 3 "Invalid" ;
VAL_ 181 BCMFR_WindowFR_Learning_Sts 0 "Invalid" 1 "FL window done" 2 "FL window failure" 3 "FL window learning" ;
VAL_ 181 BCMFR_WindowFR_Suppression_Warn 0 "OFF" 1 "Suppressed" 2 "Not suppressed" ;
VAL_ 181 BCMFR_WindowFR_LockActive 0 "Not Activate" 1 "Activated" ;
VAL_ 181 BCMFR_WindowFR_ThermalProtect 0 "OFF" 1 "Level 1" 2 "Level 2" ;
VAL_ 181 BCMFR_WindowFR_Error 0 "None" 1 "Window Error FL" ;
VAL_ 181 BCMFR_WindowsRR_AntiPinch_Warn 0 "No error" 1 "Anti-pinch RR window" 2 "Error" 3 "Invalid" ;
VAL_ 181 BCMFR_WindowRR_LockActive 0 "Not Activate" 1 "Activated" ;
VAL_ 181 BCMFR_WindowRR_Error 0 "None" 1 "Window Error RR" ;
VAL_ 181 BCMFR_WindowRR_Learning_Sts 0 "Invalid" 1 "RR window done" 2 "RR window failure" 3 "RR window learning" ;
VAL_ 181 BCMFR_WindowRR_Suppression_Warn 0 "OFF" 1 "Suppressed" 2 "Not suppressed" ;
VAL_ 181 BCMFR_WindowRR_ThermalProtect 0 "OFF" 1 "Level 1" 2 "Level 2" ;
VAL_ 181 BCMFR_WindowBtnPress_FrontPass 0 "No action" 1 "Pull up 1st stage" 2 "Pull up 2nd stage" 3 "Press down 1st stage" 4 "Press down 2nd stage" ;
VAL_ 181 Window_Position_FR 0 "Unknown" 1 "Closed (top) 0%" 2 "Position2(10%)" 3 "Position3(20%)" 4 "Position4(30%)" 5 "Position5(40%)" 6 "Position6(50%)" 7 "Position7(60%)" 8 "Position8(70%)" 9 "Position9(80%)" 10 "Position10(90%)" 11 "Soft Stop(95%)" 12 "Open (bottom) 100%" 13 "Reserved" 14 "Reserved" 15 "Signal Invalid" ;
VAL_ 181 Window_Position_RR 0 "Unknown" 1 "Closed (top) 0%" 2 "Position2(10%)" 3 "Position3(20%)" 4 "Position4(30%)" 5 "Position5(40%)" 6 "Position6(50%)" 7 "Position7(60%)" 8 "Position8(70%)" 9 "Position9(80%)" 10 "Position10(90%)" 11 "Soft Stop(95%)" 12 "Open (bottom) 100%" 13 "Reserved" 14 "Reserved" 15 "Signal Invalid" ;
VAL_ 181 BCMFR_WindowBtnPress_RR 0 "No action" 1 "Pull up 1st stage" 2 "Pull up 2nd stage" 3 "Press down 1st stage" 4 "Press down 2nd stage" ;
VAL_ 181 BCMFR_WindowFR_Malfunction_Warn 0 "No Error" 1 "Error" 2 "Reserved" 3 "Invalid" ;
VAL_ 181 BCMFR_WindowRR_Malfunction_Warn 0 "No Error" 1 "Error" 2 "Reserved" 3 "Invalid" ;
VAL_ 535 BCM_PositionLight_RL_STS 0 "OFF" 1 "ON" 2 "Reserved" 3 "Signal Invalid" 4 "Fault" ;
VAL_ 535 BCM_PositionLight_RR_STS 0 "OFF" 1 "ON" 2 "Reserved" 3 "Signal Invalid" 4 "Fault" ;
VAL_ 535 BCM_TurnIndicator_RL_STS 0 "OFF" 1 "ON" 2 "Reserved" 3 "Signal Invalid" 4 "Fault" ;
VAL_ 535 BCM_TurnIndicator_RR_STS 0 "OFF" 1 "ON" 2 "Reserved" 3 "Signal Invalid" 4 "Fault" ;
VAL_ 535 BCM_ReverseLamp_RL_STS 0 "OFF" 1 "ON" 2 "Reserved" 3 "Signal Invalid" 4 "Fault" ;
VAL_ 535 BCM_ReverseLamp_RR_STS 0 "OFF" 1 "ON" 2 "Reserved" 3 "Signal Invalid" 4 "Fault" ;
VAL_ 535 BCM_BrakeLight_RL_STS 0 "OFF" 1 "ON" 2 "Reserved" 3 "Signal Invalid" 4 "Fault" ;
VAL_ 535 BCM_BrakeLight_RR_STS 0 "OFF" 1 "ON" 2 "Reserved" 3 "Signal Invalid" 4 "Fault" ;
VAL_ 535 BCM_RearFogLamp_RR_STS 0 "OFF" 1 "ON" 2 "Reserved" 3 "Signal Invalid" 4 "Fault" ;
VAL_ 535 BCM_BrakeLight_Center_STS 0 "OFF" 1 "ON" 2 "Reserved" 3 "Signal Invalid" 4 "Fault" ;
VAL_ 535 BCM_LicensePlateLamp_RE_STS 0 "OFF" 1 "ON" 2 "Reserved" 3 "Signal Invalid" 4 "Fault" ;
VAL_ 535 BCM_RearFogLamp_RL_STS 0 "OFF" 1 "ON" 2 "Reserved" 3 "Signal Invalid" 4 "Fault" ;
VAL_ 535 BCM_SignatureRear_STS 0 "OFF" 1 "ON" 2 "Reserved" 3 "Signal Invalid" 4 "Fault" ;
VAL_ 535 BCMRE_WelcomeFarewellLight_STS 0 "OFF" 1 "Welcome mode 1" 2 "Welcome mode 2" 3 "Welcome mode 3" 4 "Farewell mode 1" 5 "Farewell mode 2" 6 "Farewell mode 3" 7 "Signal invalid" ;
VAL_ 535 BCM_PositionLight_RM_STS 0 "OFF" 1 "ON" 2 "Reserved" 3 "Signal Invalid" 4 "Fault" ;
VAL_ 535 BCM_ParkingLight_RL_STS 0 "OFF" 1 "ON" 2 "Reserved" 3 "Signal Invalid" ;
VAL_ 535 BCM_ParkingLight_RM_STS 0 "OFF" 1 "ON" 2 "Reserved" 3 "Signal Invalid" ;
VAL_ 535 BCM_ParkingLight_RR_STS 0 "OFF" 1 "ON" 2 "Reserved" 3 "Signal Invalid" ;
VAL_ 1079 CVC_SpdLimiterSts 0 "OFF" 1 "Standby" 2 "Active" 3 "Override" 4 "Fault" 5 "Reserved" 6 "Reserved" ;
VAL_ 1079 CVC_DCM_Status 0 "Normal" 1 "Fault" 2 "Reserved" ;
VAL_ 1082 CVC_BrakeRegenMode 0 "OFF" 1 "LOW" 2 "MID" 3 "HIGH" ;
VAL_ 1082 CVC_CreepEnable_stt 0 "Enable" 1 "Disable" ;
VAL_ 1082 CVC_Regen_available 0 "Not available" 1 "Available" 2 "Regen limit" 3 "Regen faut" ;
VAL_ 1082 CVC_StoppingMode_stt 0 "Off" 1 "CreepMode" 2 "RollMode" 3 "HoldMode" 4 "Reserved" 5 "Reserved" 6 "Reserved" 7 "Reserved" ;
VAL_ 1082 CVC_AutoP_Feedback 0 "ON" 1 "OFF" 2 "Reserved" 3 "Signal Invalid" ;
VAL_ 1082 CVC_Hvbatt_charging_stt 0 "Not charging" 1 "Charging" ;
VAL_ 1082 CVC_PreheatBatt_Sts 0 "Off" 1 "On" ;
VAL_ 1082 CVC_HDC_Status 0 "Off" 1 "Standby" 2 "Active" 3 "Warning" 4 "Error" ;
VAL_ 1082 CVC_STAT_RearAircondition 0 "OFF" 1 "ON" 2 "Reserved" 3 "Signal Invalid" ;
VAL_ 1082 CVC_STAT_AirDistributionRear 0 "OFF" 1 "Vent" 2 "Vent + Foot" 3 "Foot" ;
VAL_ 1082 CVC_STAT_RearFanSpeed 0 "OFF" 1 "Level 1" 2 "Level 2" 3 "Level 3" 4 "Level 4" 5 "Level 5" 6 "Level 6" 15 "Level " ;
VAL_ 1082 CVC_STAT_RearAuto 0 "OFF" 1 "ON" 2 "Reserved" 3 "Signal Invalid" ;
VAL_ 1084 MmrySeatSSaveTips 0 "no tips" 1 "save successfully" 2 "save fail" ;
VAL_ 1084 SeatSNoRecordWaring 0 "no waring" 1 "waring" ;
VAL_ 1084 CmfblUOActiveSts 0 "Inactive" 1 "Active" ;
VAL_ 1084 CmfblUOSetSt 0 "Unavailable" 1 "Off" 2 "On" 3 "Unused and Reserved" ;
VAL_ 1084 PstiUncftyFb 0 "False" 1 "True" ;
VAL_ 1084 RMrrStFlg 0 "False" 1 "True" ;
VAL_ 1085 CmfblUOActiveSts_Sec_1 0 "Inactive" 1 "Active" ;
VAL_ 1085 CmfblUOSetSt_Sec_1 0 "Unavailable" 1 "Off" 2 "On" 3 "Unused and Reserved" ;
VAL_ 1085 PstiUncftyFb_R1 0 "False" 1 "True" ;
VAL_ 1085 RMrrStFlg_R1 0 "False" 1 "True" ;
VAL_ 1085 DrStHtCntSt_sec 0 "Unavailable" 1 "One" 2 "Two" 3 "Three" 4 "Unused and Reserved" 5 "Unused and Reserved" 6 "Unused and Reserved" 7 "OFF" ;
VAL_ 1085 DrStHtRunSt_sec 0 "Normal" 1 "Error" ;
VAL_ 1085 PStHtCntSt_sec 0 "Unavailable" 1 "One" 2 "Two" 3 "Three" 4 "Unused and Reserved" 5 "Unused and Reserved" 6 "Unused and Reserved" 7 "OFF" ;
VAL_ 1085 PStHtRunSt_sec 0 "Normal" 1 "Error" ;
VAL_ 1085 DrStVtRunSt_sec 0 "Error" 1 "Normal" ;
VAL_ 1085 PStVtRunSt_sec 0 "Error" 1 "Normal" ;
VAL_ 1086 CmfblUOActiveSts_Sec_2 0 "Inactive" 1 "Active" ;
VAL_ 1086 CmfblUOSetSt_Sec_2 0 "Unavailable" 1 "Off" 2 "On" 3 "Unused and Reserved" ;
VAL_ 1086 PstiUncftyFb_R2 0 "False" 1 "True" ;
VAL_ 1086 RMrrStFlg_R2 0 "False" 1 "True" ;
VAL_ 1086 DrStHtCntSt_3rd 0 "Unavailable" 1 "One" 2 "Two" 3 "Three" 4 "Unused and Reserved" 5 "Unused and Reserved" 6 "Unused and Reserved" 7 "OFF" ;
VAL_ 1086 DrStHtRunSt_3rd 0 "Normal" 1 "Error" ;
VAL_ 1086 PStHtCntSt_3rd 0 "Unavailable" 1 "One" 2 "Two" 3 "Three" 4 "Unused and Reserved" 5 "Unused and Reserved" 6 "Unused and Reserved" 7 "OFF" ;
VAL_ 1086 PStHtRunSt_3rd 0 "Normal" 1 "Error" ;
VAL_ 1090 WLC_IC_Error 0 "No Error" 1 "Error" ;
VAL_ 1090 WLC_FAN_Error 0 "No Error" 1 "Error" ;
VAL_ 1090 WLC_TempSNSR_Error 0 "No Error" 1 "Error" ;
VAL_ 1090 WLC_Setting_standard 0 "OFF (Disable)" 1 "ON (Enable)" 2 "Default" 3 "Invalid" ;
VAL_ 1090 Transmit_WLC_situation 0 "Power OFF" 1 "Cellphone reminder" 2 "Charging" 3 "Charging complete" 4 "Wakeup" 5 "Error" 6 "Reserved" 7 "Invalid" ;
VAL_ 1090 WLC_Phoneforgetalert_state 0 "OFF" 1 "ON" 2 "Reserved" 3 "Signal invalid" ;
VAL_ 1090 WLC_Resp_Error 0 "No Error" 1 "Error" ;
VAL_ 1090 WLC_FOD_Error 0 "No Error" 1 "Error" ;
VAL_ 1090 WLC_Curr_Error 0 "No Error" 1 "Error" ;
VAL_ 1090 WLC_Temp_Error 0 "No Error" 1 "Error" ;
VAL_ 1090 WLC_VehSpeed_Error 0 "No Error" 1 "Error" ;
VAL_ 1093 RS_F_LightSensor 0 "No error" 1 "Light sensor error" ;
VAL_ 1093 RS_F_HUD_Sensor 0 "No error" 1 "HUD error" ;
VAL_ 1093 RS_St_LampReq 0 "OFF" 1 "ON" 2 "Reserved" 3 "Invalid" ;
VAL_ 1093 RS_St_CurrentRain 0 "No rain" 1 "level 1(light rain)" 2 "level 2(moderate rain)" 3 "level 3(heavy rain)" 4 "Reserved" 5 "Reserved" 6 "Reserved" 7 "Signal invalid" ;
VAL_ 529 BCM_LowBeam_FL_Sts 0 "OFF" 1 "ON" 2 "Reserved" 3 "Signal Invalid" 4 "Fault" ;
VAL_ 529 BCM_HighBeam_FL_Sts 0 "OFF" 1 "ON" 2 "Reserved" 3 "Signal Invalid" 4 "Fault" ;
VAL_ 529 BCM_TurnIndicator_FL_STS 0 "OFF" 1 "ON" 2 "Reserved" 3 "Signal Invalid" 4 "Fault" ;
VAL_ 529 BCM_PositionLight_FL_STS 0 "OFF" 1 "ON" 2 "Reserved" 3 "Signal Invalid" 4 "Fault" ;
VAL_ 529 BCM_RearFogLamp_FL_STS 0 "OFF" 1 "ON" 2 "Reserved" 3 "Signal Invalid" 4 "Fault" ;
VAL_ 529 BCM_HeightSensorSTS_Front 0 "Inactive" 1 "Active" 2 "Reserved" 3 "Error" ;
VAL_ 529 BCM_MirrorLED_FL_STS 0 "OFF" 1 "ON" 2 "Reserved" 3 "Signal Invalid" 4 "Fault" ;
VAL_ 529 BCM_HazardButton_FL_STS 0 "Not Press" 1 "Press" 2 "Reserved" 3 "Signal Invalid" ;
VAL_ 529 BCM_DaytimeRunningLight_FL_Sts 0 "OFF" 1 "ON" 2 "Reserved" 3 "Signal Invalid" 4 "Fault" ;
VAL_ 529 BCM_FrontFogLamp_FL_STS 0 "OFF" 1 "ON" 2 "Reserved" 3 "Signal Invalid" 4 "Fault" ;
VAL_ 1100 SCMF_RLSeatVent_Sts 0 "OFF" 1 "Level 1" 2 "Level 2" 3 "Level 3" 4 "Reserved" 5 "Reserved" 6 "Reserved" 7 "Invalid" ;
VAL_ 1100 SCMF_RRSeatVent_Sts 0 "OFF" 1 "Level 1" 2 "Level 2" 3 "Level 3" 4 "Reserved" 5 "Reserved" 6 "Reserved" 7 "Invalid" ;
VAL_ 1100 MmryFctOprtSetSt 0 "No Request" 1 "Save" 2 "Transfer" 3 "Moving" ;
VAL_ 1100 PsStHtCntSt 0 "Unavailable" 1 "One" 2 "Two" 3 "Three" 4 "Unused and Reserved" 5 "Unused and Reserved" 6 "Unused and Reserved" 7 "OFF" ;
VAL_ 1100 PsStHtRunSt 0 "Normal" 1 "Error" ;
VAL_ 1100 DrStHtCntSt 0 "Unavailable" 1 "One" 2 "Two" 3 "Three" 4 "Unused and Reserved" 5 "Unused and Reserved" 6 "Unused and Reserved" 7 "OFF" ;
VAL_ 1100 DrStHtRunSt 0 "Normal" 1 "Error" ;
VAL_ 1100 SCMF_FRSeatVent_Sts 0 "OFF" 1 "Level 1" 2 "Level 2" 3 "Level 3" 4 "Reserved" 5 "Reserved" 6 "Reserved" 7 "Invalid" ;
VAL_ 1100 PsStVtRunSt 0 "Error" 1 "Normal" ;
VAL_ 1100 SCMF_FLSeatVent_Sts 0 "OFF" 1 "Level 1" 2 "Level 2" 3 "Level 3" 4 "Reserved" 5 "Reserved" 6 "Reserved" 7 "Invalid" ;
VAL_ 1100 DrStVtRunSt 0 "Error" 1 "Normal" ;
VAL_ 1100 Key2AscitAcuntSt 0 "No Request" 1 "One" 2 "Two" 3 "Three" 4 "Four" 5 "Five" 6 "Six" 7 "Seven" 8 "Eight" 9 "Nine" 10 "Ten" 11 "Unused and Reserved" 15 "Unused and Reserved" ;
VAL_ 1100 Key1AscitAcuntSt 0 "No Request" 1 "One" 2 "Two" 3 "Three" 4 "Four" 5 "Five" 6 "Six" 7 "Seven" 8 "Eight" 9 "Nine" 10 "Ten" 11 "Unused and Reserved" 15 "Unused and Reserved" ;
VAL_ 1100 Key4AscitAcuntSt 0 "No Request" 1 "One" 2 "Two" 3 "Three" 4 "Four" 5 "Five" 6 "Six" 7 "Seven" 8 "Eight" 9 "Nine" 10 "Ten" 11 "Unused and Reserved" 15 "Unused and Reserved" ;
VAL_ 1100 Key3AscitAcuntSt 0 "No Request" 1 "One" 2 "Two" 3 "Three" 4 "Four" 5 "Five" 6 "Six" 7 "Seven" 8 "Eight" 9 "Nine" 10 "Ten" 11 "Unused and Reserved" 15 "Unused and Reserved" ;
VAL_ 1100 MmryDrvSeatSSetReq 0 "No Request" 1 "Seat1" 2 "Seat2" 3 "Seat3" ;
VAL_ 1100 MmryPsSeatSSetReq 0 "No Request" 1 "Seat1" 2 "Seat2" 3 "Seat3" ;
VAL_ 1110 OP_WISW_SZL_LIN 0 "No action" 255 "Signal Invalid" ;
VAL_ 1110 COMM_ERR_SZL_LIN 0 "No error" 1 "Error active" ;
VAL_ 1110 BCM_Wiper_Front_Status 0 "OFF" 1 "Mist" 2 "IntermittentAuto" 3 "Low Speed" 4 "High Speed" 5 "Reserved" 6 "Reserved" 7 "Invalid" ;
VAL_ 1110 OP_WIPO_SZL_LIN 0 "Step 1" 1 "Step 2" 2 "Step 3" 4 "Step 4" 7 "Signal Invalid" ;
VAL_ 1110 OP_COLS_SZL_LIN 0 "No action" 255 "Signal Invalid" ;
VAL_ 1110 NOD_ERR_SZL_LIN 0 "NO error" 1 "error active" 2 "error Stat change" 3 "Signal invalid" ;
VAL_ 1110 BCM_Wiper_Rear_Status 0 "OFF" 1 "ON" 2 "Reserved" 3 "Signal Invalid" ;
VAL_ 1152 SCMF_DrvSeatMissalignment 0 "Off" 1 "Driver Power seat malfunction, Seat Initialization required" ;
VAL_ 1152 SCMF_PasSeatMisalignment 0 "Off" 1 "Passenger Power seat malfunction, Seat Initialization required" ;
VAL_ 1155 TPMS_FLTirePressAlarm 0 "No warning" 1 "High pressure warning" 2 "Low pressure warning" 3 "Quick leakage" 4 "Lost Sensor" 5 "Sensor battery low" 6 "Sensor failure" 7 "High temperature" ;
VAL_ 1155 TPMS_FRTirePressAlarm 0 "No warning" 1 "High pressure warning" 2 "Low pressure warning" 3 "Quick leakage" 4 "Lost Sensor" 5 "Sensor battery low" 6 "Sensor failure" 7 "High temperature" ;
VAL_ 1155 TPMS_RLTirePressAlarm 0 "No warning" 1 "High pressure warning" 2 "Low pressure warning" 3 "Quick leakage" 4 "Lost Sensor" 5 "Sensor battery low" 6 "Sensor failure" 7 "High temperature" ;
VAL_ 1155 TPMS_RRTirePressAlarm 0 "No warning" 1 "High pressure warning" 2 "Low pressure warning" 3 "Quick leakage" 4 "Lost Sensor" 5 "Sensor battery low" 6 "Sensor failure" 7 "High temperature" ;
VAL_ 1155 TPMS_TirePosition 0 "No any sensor" 1 "Left Front tire" 2 "Right Front tire" 3 "Right Rear tire" 4 "Left Rear tire" 5 "reseved" 6 "reseved" 7 "reserved" ;
VAL_ 1155 TPMS_ready2learning 0 "Invalid" 1 "Ready" ;
VAL_ 1155 TPMS_TireTempAlarm 0 "No warning" 1 "High Temperature Warning" ;
VAL_ 1155 TPMS_LearningStatus 0 "Invalid" 1 "Left Front tire done" 2 "Right Front tire done" 3 "Right Rear tire done" 4 "Left Rear tire done" 5 "All completed" 6 "Failure" 7 "reserved" ;
VAL_ 1157 TBOX_RPADirSel 0 "No Park Slot" 1 "FrntLeCrss" 2 "FrntLePrl" 3 "Frnt" 4 "FrntRiCrss" 5 "FrntRiPrl" 6 "Bck" 7 "BckLe" 8 "BckRi" 9 "Reserved" 10 "Reserved" 11 "Reserved" 12 "Reserved" 13 "Reserved" 14 "Reserved" 15 "SNA" ;
VAL_ 1158 TPMS_FLTirePressAlarm2 0 "No warning" 1 "High pressure warning" 2 "Low pressure warning" 3 "Quick leakage" 4 "Lost Sensor" 5 "Sensor battery low" 6 "Sensor failure" 7 "Reserved" ;
VAL_ 1158 TPMS_FRTirePressAlarm2 0 "No warning" 1 "High pressure warning" 2 "Low pressure warning" 3 "Quick leakage" 4 "Lost Sensor" 5 "Sensor battery low" 6 "Sensor failure" 7 "Reserved" ;
VAL_ 1158 TPMS_RLTirePressAlarm2 0 "No warning" 1 "High pressure warning" 2 "Low pressure warning" 3 "Quick leakage" 4 "Lost Sensor" 5 "Sensor battery low" 6 "Sensor failure" 7 "Reserved" ;
VAL_ 1158 TPMS_RRTirePressAlarm2 0 "No warning" 1 "High pressure warning" 2 "Low pressure warning" 3 "Quick leakage" 4 "Lost Sensor" 5 "Sensor battery low" 6 "Sensor failure" 7 "Reserved" ;
VAL_ 1160 ACU_Malfunction 0 "ACM_Failure" 1 "ACM_Normal_Operation" ;
VAL_ 1160 ACU_Pre_Drive_Check 0 "ACM_Pre_Drive_Check" 1 "ACM_Normal_Operation" ;
VAL_ 1160 ACU_in_Plant_Mode 0 "ACM_in_Plant_Mode" 1 "ACM_in_Normal_Mode" ;
VAL_ 1160 ACU_PAB_Suppression 0 "Not_Suppressed" 1 "Suppressed" 2 "Function Failure" 3 "Invalid_Value" ;
VAL_ 1160 ACU_Airbag_Disabled 0 "ACM_AirBag_Disabled" 1 "ACM_Normal_Operation" ;
VAL_ 1160 ACU_Development_Calibration 0 "ACM_Dev_Calibrated" 1 "ACM_Normal_Operation" ;
VAL_ 1160 ACU_In_Disposal_Mode 0 "ACM_In_Disposal_Mode" 1 "ACM_Normal_Operation" ;
VAL_ 1166 ETG_Malfunction 0 "No Error" 1 "Error" ;
VAL_ 1166 ETG_Warning_Flag_2 0 "No Error" 1 "Error" ;
VAL_ 1166 ETG_Warning_Flag_3 0 "No Error" 1 "Error" ;
VAL_ 1166 ETG_Warning_Flag_4 0 "No Error" 1 "Error" ;
VAL_ 1166 ETG_Warning_Flag_5 0 "No Error" 1 "Error" ;
VAL_ 1166 ETG_Warning_Flag_6 0 "No Error" 1 "Error" ;
VAL_ 1166 ETG_Warning_Flag_7 0 "No Error" 1 "Error" ;
VAL_ 1166 ETG_Warning_Flag_8 0 "No Error" 1 "Error" ;
VAL_ 1166 ETG_Warning_Flag_9 0 "No Error" 1 "Error" ;
VAL_ 1166 ETG_Warning_Flag_10 0 "No Error" 1 "Error" ;
VAL_ 1166 ETG_Warning_Flag_11 0 "No Error" 1 "Error" ;
VAL_ 1166 ETG_Warning_Flag_12 0 "No Error" 1 "Error" ;
VAL_ 1171 BMS_PackTempSts 0 "No warning" 1 "Over Temperature Warning" 2 "Under Temperature Warning" ;
VAL_ 1171 BMS_ThermalRunaway 0 "No Warning" 1 "Warning" ;
VAL_ 1171 BMS_BatteryReplacement 0 "No Warning" 1 "Warning" ;
VAL_ 1171 BMS_Warning_PowerDegrade 0 "Normal" 1 "Pack Power Degrade" ;
VAL_ 1171 BMS_Warning_DeltaSoC 0 "Normal" 1 "Delta SOC high" ;
VAL_ 1171 BMS_Warning_HVILSts 0 "Normal" 1 "HVIL error detected" ;
VAL_ 1171 BMS_Warning_Isolation 0 "Normal" 1 "Isolation reached level 3" ;
VAL_ 1171 BMS_Warning_CoolantLeakage 0 "Normal" 1 "Coolant leakage detected" ;
VAL_ 1171 BMS_MalfunctionSts 0 "No Warning" 1 "Warning" ;
VAL_ 1171 BMS_LowBattery 0 "No warning" 1 "Low level" 2 "Extremely low level" ;
VAL_ 1171 BMS_Warning_DeltaTemperature 0 "Normal" 1 "Level 1 warning" 2 "Level 2 extreme" ;
VAL_ 1171 BMS_Warning_BDUTemperatureSts 0 "Normal" 1 "BDU temp warning" 2 "BDU hot" 3 "BDU extreme hot" ;
VAL_ 1171 BMS_Warning_Contactor_Aging 0 "No Warning" 1 "Warning" ;
